VERSION "HNNBNNNYNNNNNNNNNNNNNNNNNNNNNNNNNNNNNNNNNN/4/%%%/4/'%**4NNN///"

NS_ :

BS_:

BU_: BAP_Tester CGS Gateway Gateway_PAG HUD Kombi Kombi_LB Kombi_PAG Waehlhebel_SB

BO_ 974 TSG_HFS_01: 8 Gateway
 SG_ HFS_Tuer_geoeffnet : 0|1@1+ (1.0,0.0) [0.0|1] ""  Vector__XXX
 SG_ HFS_verriegelt : 1|1@1+ (1.0,0.0) [0.0|1] ""  Vector__XXX
 SG_ HFS_gesafet : 2|1@1+ (1.0,0.0) [0.0|1] ""  Vector__XXX
 SG_ HFS_Heckrollotaster_betaetigt : 3|1@1+ (1.0,0.0) [0.0|1] ""  Vector__XXX
 SG_ HFS_Tuerschloss_defekt : 4|1@1+ (1.0,0.0) [0.0|1] ""  Kombi,Kombi_LB,Kombi_PAG
 SG_ HFS_Unlock_Taster : 5|1@1+ (1.0,0.0) [0.0|1] ""  Vector__XXX
 SG_ HFS_Lock_Taster : 6|1@1+ (1.0,0.0) [0.0|1] ""  Vector__XXX
 SG_ HFS_Sperrklinke : 7|1@1+ (1.0,0.0) [0.0|1] ""  Vector__XXX
 SG_ HFS_TAG_betaetigt : 8|1@1+ (1.0,0.0) [0.0|1] ""  Vector__XXX
 SG_ HFS_TIG_betaetigt : 9|1@1+ (1.0,0.0) [0.0|1] ""  Vector__XXX
 SG_ HFS_FH_S_HBFS_AutoHoch : 10|1@1+ (1.0,0.0) [0.0|1] ""  Vector__XXX
 SG_ HFS_FH_S_HBFS_AutoTief : 11|1@1+ (1.0,0.0) [0.0|1] ""  Vector__XXX
 SG_ HFS_FH_S_HBFS_ManHoch : 12|1@1+ (1.0,0.0) [0.0|1] ""  Vector__XXX
 SG_ HFS_FH_S_HBFS_ManTief : 13|1@1+ (1.0,0.0) [0.0|1] ""  Vector__XXX
 SG_ HFS_Tuer_Status : 14|2@1+ (1.0,0.0) [0.0|3] ""  Kombi_PAG
 SG_ HFS_SAD_Schalter : 16|4@1+ (1.0,0.0) [0.0|15] ""  Vector__XXX
 SG_ HFS_FH_S_ManHoch : 20|1@1+ (1.0,0.0) [0.0|1] ""  Vector__XXX
 SG_ HFS_FH_S_AutoHoch : 21|1@1+ (1.0,0.0) [0.0|1] ""  Vector__XXX
 SG_ HFS_FH_S_ManTief : 22|1@1+ (1.0,0.0) [0.0|1] ""  Vector__XXX
 SG_ HFS_FH_S_AutoTief : 23|1@1+ (1.0,0.0) [0.0|1] ""  Vector__XXX
 SG_ HFS_FH_Oeffnung : 24|8@1+ (0.5,0) [0.0|100.0] "Unit_PerCent"  Vector__XXX
 SG_ HFS_FH_Bew_hoch : 32|1@1+ (1.0,0.0) [0.0|1] ""  Vector__XXX
 SG_ HFS_FH_Bew_tief : 33|1@1+ (1.0,0.0) [0.0|1] ""  Vector__XXX
 SG_ HFS_FH_Fang : 34|1@1+ (1.0,0.0) [0.0|1] ""  Vector__XXX
 SG_ HFS_FH_Block : 35|1@1+ (1.0,0.0) [0.0|1] ""  Vector__XXX
 SG_ HFS_FH_Thermo : 36|1@1+ (1.0,0.0) [0.0|1] ""  Vector__XXX
 SG_ HFS_UEKB_aktiviert : 37|1@1+ (1.0,0.0) [0.0|1] ""  Vector__XXX
 SG_ HFS_Tueroeffnen_Warnung : 38|1@1+ (1.0,0.0) [0.0|1] ""  Kombi,Kombi_LB,Kombi_PAG
 SG_ HFS_FH_normiert : 39|1@1+ (1.0,0.0) [0.0|1] ""  Vector__XXX
 SG_ ASW_Warnung_aktiv_HFS : 40|1@1+ (1.0,0.0) [0.0|1] ""  Kombi,Kombi_LB,Kombi_PAG
 SG_ HFS_Zuziehhilfe_aktiv : 41|1@1+ (1.0,0.0) [0.0|1] ""  Vector__XXX
 SG_ HFS_Seitenrollo_hoch : 42|1@1+ (1.0,0.0) [0.0|1] ""  Vector__XXX
 SG_ HFS_Seitenrollo_tief : 43|1@1+ (1.0,0.0) [0.0|1] ""  Vector__XXX
 SG_ HFS_Status_KiSi : 44|1@1+ (1.0,0.0) [0.0|1] ""  Kombi_PAG
 SG_ SSR_HFS_Pos_Unten : 45|1@1+ (1.0,0.0) [0.0|1] ""  Vector__XXX
 SG_ HFS_Oben_Block_erw : 46|1@1+ (1.0,0.0) [0.0|1] ""  Vector__XXX
 SG_ HFS_Unten_Block_erw : 47|1@1+ (1.0,0.0) [0.0|1] ""  Vector__XXX
 SG_ MTHFS_M_Taste : 48|1@1+ (1.0,0.0) [0.0|1] ""  Vector__XXX
 SG_ MTHFS_Pos1 : 49|1@1+ (1.0,0.0) [0.0|1] ""  Vector__XXX
 SG_ MTHFS_Pos2 : 50|1@1+ (1.0,0.0) [0.0|1] ""  Vector__XXX
 SG_ MTHFS_Pos3 : 51|1@1+ (1.0,0.0) [0.0|1] ""  Vector__XXX
 SG_ HFS_MRollo_Schalter : 52|3@1+ (1.0,0.0) [0.0|7] ""  Vector__XXX
 SG_ HFS_Lock_Taster_inv : 55|1@1+ (1.0,0.0) [0.0|1] ""  Vector__XXX
 SG_ HFS_Status_eTAG : 56|2@1+ (1.0,0.0) [0.0|3] ""  Vector__XXX
 SG_ HFS_Tuer_Status_QBit : 58|1@1+ (1.0,0.0) [0.0|1] ""  Vector__XXX
 SG_ HFS_TCR_Mode_aktiv : 59|1@1+ (1.0,0.0) [0.0|1] ""  Kombi_PAG

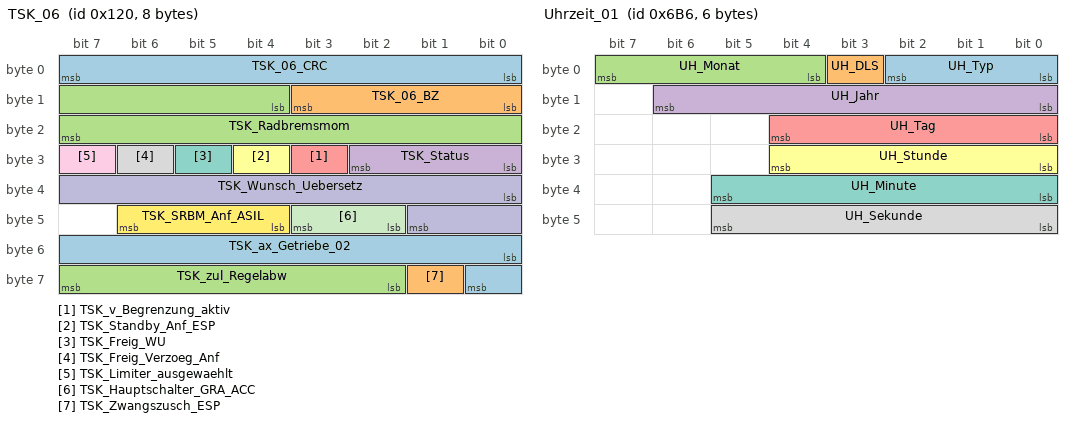
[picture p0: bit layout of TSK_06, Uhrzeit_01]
BO_ 288 TSK_06: 8 Gateway
 SG_ TSK_06_CRC : 0|8@1+ (1,0) [0|255] ""  Vector__XXX
 SG_ TSK_06_BZ : 8|4@1+ (1,0) [0|15] ""  Vector__XXX
 SG_ TSK_Radbremsmom : 12|12@1+ (8,0) [0|32760] "Unit_NewtoMeter"  Vector__XXX
 SG_ TSK_Status : 24|3@1+ (1.0,0.0) [0.0|7] ""  Vector__XXX
 SG_ TSK_v_Begrenzung_aktiv : 27|1@1+ (1.0,0.0) [0.0|1] ""  Vector__XXX
 SG_ TSK_Standby_Anf_ESP : 28|1@1+ (1.0,0.0) [0.0|1] ""  Vector__XXX
 SG_ TSK_Freig_WU : 29|1@1+ (1.0,0.0) [0.0|1] ""  Vector__XXX
 SG_ TSK_Freig_Verzoeg_Anf : 30|1@1+ (1.0,0.0) [0.0|1] ""  Vector__XXX
 SG_ TSK_Limiter_ausgewaehlt : 31|1@1+ (1.0,0.0) [0.0|1] ""  Vector__XXX
 SG_ TSK_Wunsch_Uebersetz : 32|10@1+ (0.0245,0) [0.0245|25.0635] ""  Vector__XXX
 SG_ TSK_Hauptschalter_GRA_ACC : 42|2@1+ (1.0,0.0) [0.0|3] ""  Kombi,Kombi_LB,Kombi_PAG
 SG_ TSK_SRBM_Anf_ASIL : 44|3@1+ (1.0,0.0) [0.0|7] ""  Vector__XXX
 SG_ TSK_ax_Getriebe_02 : 48|9@1+ (0.024,-2.016) [-2.016|10.224] "Unit_MeterPerSeconSquar"  Vector__XXX
 SG_ TSK_Zwangszusch_ESP : 57|1@1+ (1.0,0.0) [0.0|1] ""  Vector__XXX
 SG_ TSK_zul_Regelabw : 58|6@1+ (0.024,0) [0.000|1.512] "Unit_MeterPerSeconSquar"  Vector__XXX

BO_ 798 TSK_07: 8 Gateway
 SG_ TSK_07_CRC : 0|8@1+ (1,0) [0|255] ""  Kombi,Kombi_LB,Kombi_PAG
 SG_ TSK_07_BZ : 8|4@1+ (1,0) [0|15] ""  Kombi,Kombi_LB,Kombi_PAG
 SG_ TSK_Wunschgeschw : 12|10@1+ (0.32,0) [0.00|326.72] "Unit_KiloMeterPerHour"  HUD,Kombi,Kombi_LB,Kombi_PAG
 SG_ TSK_praediktiver_Hinweis : 22|3@1+ (1.0,0.0) [0.0|7] ""  HUD,Kombi,Kombi_PAG
 SG_ TSK_naechstes_Event : 25|6@1+ (1.0,0.0) [0.0|63] ""  HUD,Kombi,Kombi_PAG
 SG_ TSK_Fahrzeugstatus_praed_Fkt : 31|3@1+ (1.0,0.0) [0.0|7] ""  HUD,Kombi,Kombi_PAG
 SG_ TSK_praediktiver_Automode : 34|1@1+ (1.0,0.0) [0.0|1] ""  HUD,Kombi,Kombi_PAG
 SG_ TSK_Texte : 40|5@1+ (1.0,0.0) [0.0|31] ""  Kombi,Kombi_LB,Kombi_PAG
 SG_ TSK_Akustik : 45|3@1+ (1.0,0.0) [0.0|7] ""  Kombi,Kombi_LB,Kombi_PAG
 SG_ TSK_Texte_Primaeranz : 48|5@1+ (1.0,0.0) [0.0|31] ""  HUD,Kombi,Kombi_LB,Kombi_PAG
 SG_ TSK_Limiter_Fahrerinfo : 53|2@1+ (1.0,0.0) [0.0|3] ""  HUD,Kombi,Kombi_LB,Kombi_PAG
 SG_ TSK_Limiter_Anzeige : 55|1@1+ (1.0,0.0) [0.0|1] ""  HUD,Kombi,Kombi_LB,Kombi_PAG
 SG_ TSK_Fahrzeugstatus_GRA : 56|1@1+ (1.0,0.0) [0.0|1] ""  Kombi,Kombi_LB,Kombi_PAG
 SG_ TSK_Fahrzeugstatus_Limiter : 57|1@1+ (1.0,0.0) [0.0|1] ""  Kombi,Kombi_LB,Kombi_PAG
 SG_ MO_Motorlaufwarnung : 58|1@1+ (1.0,0.0) [0.0|1] ""  Kombi,Kombi_LB,Kombi_PAG
 SG_ MO_Verlassenswarnung : 59|1@1+ (1.0,0.0) [0.0|1] ""  Kombi,Kombi_LB,Kombi_PAG
 SG_ TSK_naechstes_Event_Einheit : 60|1@1+ (1.0,0.0) [0.0|1] ""  Kombi,Kombi_PAG
 SG_ TSK_Status_Anzeige : 61|3@1+ (1.0,0.0) [0.0|7] ""  HUD,Kombi,Kombi_LB,Kombi_PAG

BO_ 563 TSK_10: 8 Gateway
 SG_ TSK_praed_Wunschgeschw : 54|10@1+ (0.32,0) [0.00|326.72] "Unit_KiloMeterPerHour"  HUD,Kombi,Kombi_PAG

BO_ 1718 Uhrzeit_01: 6 Kombi
 SG_ UH_Typ : 0|3@1+ (1.0,0.0) [0.0|7] ""  Gateway,Gateway_PAG
 SG_ UH_DLS : 3|1@1+ (1.0,0.0) [0.0|1] ""  Gateway,Gateway_PAG
 SG_ UH_Monat : 4|4@1+ (1,0) [1|12] "Unit_Month"  Gateway,Gateway_PAG
 SG_ UH_Jahr : 8|7@1+ (1,2000) [2000|2127] "Unit_Year"  Gateway,Gateway_PAG
 SG_ UH_Tag : 16|5@1+ (1,0) [1|31] "Unit_Day"  Gateway,Gateway_PAG
 SG_ UH_Stunde : 24|5@1+ (1,0) [0|23] "Unit_Hours"  Gateway,Gateway_PAG
 SG_ UH_Minute : 32|6@1+ (1,0) [0|59] "Unit_Minut"  Gateway,Gateway_PAG
 SG_ UH_Sekunde : 40|6@1+ (1,0) [0|59] "Unit_Secon"  Gateway,Gateway_PAG

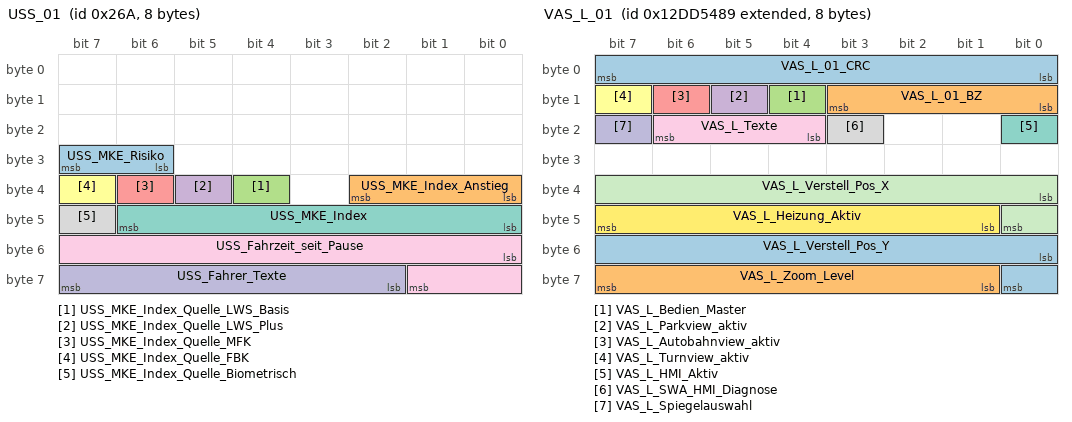
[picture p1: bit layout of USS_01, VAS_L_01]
BO_ 618 USS_01: 8 Gateway
 SG_ USS_MKE_Risiko : 30|2@1+ (1.0,0.0) [0.0|3] ""  Vector__XXX
 SG_ USS_MKE_Index_Anstieg : 32|3@1+ (1.0,0.0) [0.0|7] ""  Vector__XXX
 SG_ USS_MKE_Index_Quelle_LWS_Basis : 36|1@1+ (1.0,0.0) [0.0|1] ""  Vector__XXX
 SG_ USS_MKE_Index_Quelle_LWS_Plus : 37|1@1+ (1.0,0.0) [0.0|1] ""  Vector__XXX
 SG_ USS_MKE_Index_Quelle_MFK : 38|1@1+ (1.0,0.0) [0.0|1] ""  Vector__XXX
 SG_ USS_MKE_Index_Quelle_FBK : 39|1@1+ (1.0,0.0) [0.0|1] ""  Vector__XXX
 SG_ USS_MKE_Index : 40|7@1+ (0.1,0) [0.0|10.0] ""  Vector__XXX
 SG_ USS_MKE_Index_Quelle_Biometrisch : 47|1@1+ (1.0,0.0) [0.0|1] ""  Vector__XXX
 SG_ USS_Fahrzeit_seit_Pause : 48|10@1+ (1,0) [0|1020] "Unit_Minut"  Vector__XXX
 SG_ USS_Fahrer_Texte : 58|6@1+ (1.0,0.0) [0.0|63] ""  Kombi,Kombi_LB

BO_ 2463978633 VAS_L_01: 8 Gateway
 SG_ VAS_L_01_CRC : 0|8@1+ (1,0) [0|255] ""  Kombi,Kombi_LB
 SG_ VAS_L_01_BZ : 8|4@1+ (1,0) [0|15] ""  Kombi,Kombi_LB
 SG_ VAS_L_Bedien_Master : 12|1@1+ (1.0,0.0) [0.0|1] ""  Vector__XXX
 SG_ VAS_L_Parkview_aktiv : 13|1@1+ (1.0,0.0) [0.0|1] ""  Vector__XXX
 SG_ VAS_L_Autobahnview_aktiv : 14|1@1+ (1.0,0.0) [0.0|1] ""  Vector__XXX
 SG_ VAS_L_Turnview_aktiv : 15|1@1+ (1.0,0.0) [0.0|1] ""  Vector__XXX
 SG_ VAS_L_HMI_Aktiv : 16|1@1+ (1.0,0.0) [0.0|1] ""  Vector__XXX
 SG_ VAS_L_SWA_HMI_Diagnose : 19|1@1+ (1.0,0.0) [0.0|1] ""  Vector__XXX
 SG_ VAS_L_Texte : 20|3@1+ (1.0,0.0) [0.0|7] ""  Kombi
 SG_ VAS_L_Spiegelauswahl : 23|1@1+ (1.0,0.0) [0.0|1] ""  Vector__XXX
 SG_ VAS_L_Verstell_Pos_X : 32|9@1+ (1,0) [0|400] "Unit_None"  Vector__XXX
 SG_ VAS_L_Heizung_Aktiv : 41|7@1+ (1,0) [0|100] "Unit_PerCent"  Vector__XXX
 SG_ VAS_L_Verstell_Pos_Y : 48|9@1+ (1,0) [0|400] "Unit_None"  Vector__XXX
 SG_ VAS_L_Zoom_Level : 57|7@1+ (1,0) [0|100] "Unit_PerCent"  Vector__XXX

BO_ 995 Verdeck_01: 8 Gateway
 SG_ Verdeck_01_CRC : 0|8@1+ (1,0) [0|255] ""  Vector__XXX
 SG_ Verdeck_01_BZ : 8|4@1+ (1,0) [0|15] ""  Vector__XXX
 SG_ VS_VD_zu_ver : 16|1@1+ (1.0,0.0) [0.0|1] ""  Kombi,Kombi_PAG
 SG_ VS_VD_entriegelt : 17|1@1+ (1.0,0.0) [0.0|1] ""  Vector__XXX
 SG_ VS_VD_offen_ver : 18|1@1+ (1.0,0.0) [0.0|1] ""  Kombi
 SG_ VS_VD_Zwischenposition : 19|1@1+ (1.0,0.0) [0.0|1] ""  Vector__XXX
 SG_ VS_VD_Bew_auf : 20|1@1+ (1.0,0.0) [0.0|1] ""  Vector__XXX
 SG_ VS_VD_Bew_zu : 21|1@1+ (1.0,0.0) [0.0|1] ""  Vector__XXX
 SG_ VS_Verdeck_Anf : 22|1@1+ (1.0,0.0) [0.0|1] ""  Vector__XXX
 SG_ VS_Hardtop : 23|1@1+ (1.0,0.0) [0.0|1] ""  Vector__XXX
 SG_ VS_VD_Fehler : 24|1@1+ (1.0,0.0) [0.0|1] ""  Vector__XXX
 SG_ VS_Lampe_Blk : 25|1@1+ (1.0,0.0) [0.0|1] ""  Kombi
 SG_ VS_Buzzer : 26|1@1+ (1.0,0.0) [0.0|1] ""  Kombi
 SG_ VS_HD_sperren : 27|1@1+ (1.0,0.0) [0.0|1] ""  Vector__XXX
 SG_ VS_HHS_enable : 28|1@1+ (1.0,0.0) [0.0|1] ""  Vector__XXX
 SG_ VD_SpannungsAnf : 29|2@1+ (1.0,0.0) [0.0|3] ""  Vector__XXX
 SG_ VS_VDKD_auf : 31|1@1+ (1.0,0.0) [0.0|1] ""  Vector__XXX
 SG_ VS_FS_AutoHoch : 32|1@1+ (1.0,0.0) [0.0|1] ""  Vector__XXX
 SG_ VS_FS_AutoTief : 33|1@1+ (1.0,0.0) [0.0|1] ""  Vector__XXX
 SG_ VS_FS_ManHoch : 34|1@1+ (1.0,0.0) [0.0|1] ""  Vector__XXX
 SG_ VS_FS_ManTief : 35|1@1+ (1.0,0.0) [0.0|1] ""  Vector__XXX
 SG_ VS_BFS_AutoHoch : 36|1@1+ (1.0,0.0) [0.0|1] ""  Vector__XXX
 SG_ VS_BFS_AutoTief : 37|1@1+ (1.0,0.0) [0.0|1] ""  Vector__XXX
 SG_ VS_BFS_ManHoch : 38|1@1+ (1.0,0.0) [0.0|1] ""  Vector__XXX
 SG_ VS_BFS_ManTief : 39|1@1+ (1.0,0.0) [0.0|1] ""  Vector__XXX
 SG_ VS_HFS_AutoHoch : 40|1@1+ (1.0,0.0) [0.0|1] ""  Vector__XXX
 SG_ VS_HFS_AutoTief : 41|1@1+ (1.0,0.0) [0.0|1] ""  Vector__XXX
 SG_ VS_HFS_ManHoch : 42|1@1+ (1.0,0.0) [0.0|1] ""  Vector__XXX
 SG_ VS_HFS_ManTief : 43|1@1+ (1.0,0.0) [0.0|1] ""  Vector__XXX
 SG_ VS_HBFS_AutoHoch : 44|1@1+ (1.0,0.0) [0.0|1] ""  Vector__XXX
 SG_ VS_HBFS_AutoTief : 45|1@1+ (1.0,0.0) [0.0|1] ""  Vector__XXX
 SG_ VS_HBFS_ManHoch : 46|1@1+ (1.0,0.0) [0.0|1] ""  Vector__XXX
 SG_ VS_HBFS_ManTief : 47|1@1+ (1.0,0.0) [0.0|1] ""  Vector__XXX
 SG_ VS_FH_FT_Langhub : 49|1@1+ (1.0,0.0) [0.0|1] ""  Vector__XXX
 SG_ VS_Windschott_nicht_abgelegt : 50|1@1+ (1.0,0.0) [0.0|1] ""  Vector__XXX
 SG_ VS_FH_BT_Langhub : 51|1@1+ (1.0,0.0) [0.0|1] ""  Vector__XXX
 SG_ VS_FH_HFS_Langhub : 53|1@1+ (1.0,0.0) [0.0|1] ""  Vector__XXX
 SG_ VS_Heckschloss_auf : 54|1@1+ (1.0,0.0) [0.0|1] ""  Vector__XXX
 SG_ VS_FH_HBFS_Langhub : 55|1@1+ (1.0,0.0) [0.0|1] ""  Vector__XXX
 SG_ VSG_Meldungen : 56|6@1+ (1,0) [1|63] "Unit_None"  Kombi,Kombi_PAG
 SG_ VS_StartStopp_Info : 62|2@1+ (1.0,0.0) [0.0|3] ""  Vector__XXX

BO_ 1716 VIN_01: 8 Gateway
 SG_ VIN_01_MUX M  : 0|2@1+ (1,0) [0|3] ""  Kombi,Kombi_LB,Kombi_PAG
 SG_ KS_Geheimnis_1 m0  : 8|8@1+ (1,0) [0|255] ""  Vector__XXX
 SG_ VIN_4 m1  : 8|8@1+ (1,0) [0|255] ""  Kombi,Kombi_PAG
 SG_ VIN_11 m2  : 8|8@1+ (1,0) [0|255] ""  Kombi,Kombi_PAG
 SG_ KS_Geheimnis_2 m0  : 16|8@1+ (1,0) [0|255] ""  Vector__XXX
 SG_ VIN_5 m1  : 16|8@1+ (1,0) [0|255] ""  Kombi,Kombi_PAG
 SG_ VIN_12 m2  : 16|8@1+ (1,0) [0|255] ""  Kombi,Kombi_PAG
 SG_ KS_Geheimnis_3 m0  : 24|8@1+ (1,0) [0|255] ""  Vector__XXX
 SG_ VIN_6 m1  : 24|8@1+ (1,0) [0|255] ""  Kombi,Kombi_PAG
 SG_ VIN_13 m2  : 24|8@1+ (1,0) [0|255] ""  Kombi,Kombi_PAG
 SG_ KS_Geheimnis_4 m0  : 32|8@1+ (1,0) [0|255] ""  Vector__XXX
 SG_ VIN_7 m1  : 32|8@1+ (1,0) [0|255] ""  Kombi,Kombi_PAG
 SG_ VIN_14 m2  : 32|8@1+ (1,0) [0|255] ""  Kombi,Kombi_PAG
 SG_ VIN_1 m0  : 40|8@1+ (1,0) [0|255] ""  Kombi,Kombi_LB,Kombi_PAG
 SG_ VIN_8 m1  : 40|8@1+ (1,0) [0|255] ""  Kombi,Kombi_PAG
 SG_ VIN_15 m2  : 40|8@1+ (1,0) [0|255] ""  Kombi,Kombi_PAG
 SG_ VIN_2 m0  : 48|8@1+ (1,0) [0|255] ""  Kombi,Kombi_LB,Kombi_PAG
 SG_ VIN_9 m1  : 48|8@1+ (1,0) [0|255] ""  Kombi,Kombi_PAG
 SG_ VIN_16 m2  : 48|8@1+ (1,0) [0|255] ""  Kombi,Kombi_PAG
 SG_ VIN_3 m0  : 56|8@1+ (1,0) [0|255] ""  Kombi,Kombi_LB,Kombi_PAG
 SG_ VIN_10 m1  : 56|8@1+ (1,0) [0|255] ""  Kombi,Kombi_PAG
 SG_ VIN_17 m2  : 56|8@1+ (1,0) [0|255] ""  Kombi,Kombi_PAG

BO_ 385 VZE_01: 8 Gateway
 SG_ VZE_Anzeigemodus : 0|2@1+ (1.0,0.0) [0.0|3] ""  HUD,Kombi,Kombi_LB,Kombi_PAG
 SG_ VZE_Hinweistext : 2|3@1+ (1,0) [1|7] ""  Kombi,Kombi_LB,Kombi_PAG
 SG_ VZE_Akustik_Limitwechsel : 5|1@1+ (1.0,0.0) [0.0|1] ""  Kombi,Kombi_LB,Kombi_PAG
 SG_ VZE_Modus_OptischeWarnung : 6|1@1+ (1.0,0.0) [0.0|1] ""  HUD,Kombi,Kombi_LB,Kombi_PAG
 SG_ VZE_Verkehrszeichen_Einheit : 8|1@1+ (1.0,0.0) [0.0|1] ""  HUD,Kombi_PAG
 SG_ VZE_Anzeigeunterdrueck_Zeichen_3 : 9|1@1+ (1.0,0.0) [0.0|1] ""  HUD,Kombi,Kombi_LB
 SG_ VZE_Anzeigeunterdrueck_Zeichen_2 : 10|1@1+ (1.0,0.0) [0.0|1] ""  HUD,Kombi,Kombi_LB
 SG_ VZE_Verkehrszeichen_1 : 11|8@1+ (1,0) [1|255] ""  HUD,Kombi,Kombi_LB,Kombi_PAG
 SG_ VZE_Verkehrszeichen_2 : 19|8@1+ (1,0) [1|255] ""  HUD,Kombi,Kombi_LB,Kombi_PAG
 SG_ VZE_Verkehrszeichen_3 : 27|8@1+ (1,0) [1|255] ""  HUD,Kombi,Kombi_LB,Kombi_PAG
 SG_ VZE_Warnung_Verkehrszeichen_1 : 35|1@1+ (1.0,0.0) [0.0|1] ""  HUD,Kombi,Kombi_LB,Kombi_PAG
 SG_ VZE_Warnung_Verkehrszeichen_2 : 36|1@1+ (1.0,0.0) [0.0|1] ""  HUD,Kombi,Kombi_LB,Kombi_PAG
 SG_ VZE_Warnung_Verkehrszeichen_3 : 37|1@1+ (1.0,0.0) [0.0|1] ""  HUD,Kombi,Kombi_LB,Kombi_PAG
 SG_ VZE_Zusatzschild_1 : 38|4@1+ (1,0) [1|15] ""  HUD,Kombi,Kombi_LB,Kombi_PAG
 SG_ VZE_Zusatzschild_2 : 42|4@1+ (1,0) [1|15] ""  HUD,Kombi,Kombi_LB,Kombi_PAG
 SG_ VZE_Zusatzschild_3 : 46|4@1+ (1,0) [1|15] ""  HUD,Kombi,Kombi_LB,Kombi_PAG
 SG_ VZE_Anzeigeunterdrueck_Zeichen_1 : 50|1@1+ (1.0,0.0) [0.0|1] ""  HUD,Kombi,Kombi_LB,Kombi_PAG
 SG_ VZE_Zeichen_01_KameraWied : 51|1@1+ (1.0,0.0) [0.0|1] ""  Vector__XXX
 SG_ VZE_Zeichen_02_KameraWied : 52|1@1+ (1.0,0.0) [0.0|1] ""  Vector__XXX
 SG_ VZE_Zeichen_03_KameraWied : 53|1@1+ (1.0,0.0) [0.0|1] ""  Vector__XXX
 SG_ VZE_Zeichen_01_Kamera : 54|1@1+ (1.0,0.0) [0.0|1] ""  Vector__XXX
 SG_ VZE_Zeichen_01_Karte : 55|1@1+ (1.0,0.0) [0.0|1] ""  Vector__XXX
 SG_ VZE_Zeichen_01_Gesetz : 56|1@1+ (1.0,0.0) [0.0|1] ""  Vector__XXX
 SG_ VZE_Zeichen_02_Kamera : 57|1@1+ (1.0,0.0) [0.0|1] ""  Vector__XXX
 SG_ VZE_Zeichen_02_Karte : 58|1@1+ (1.0,0.0) [0.0|1] ""  Vector__XXX
 SG_ VZE_Zeichen_02_Gesetz : 59|1@1+ (1.0,0.0) [0.0|1] ""  Vector__XXX
 SG_ VZE_Zeichen_03_Kamera : 60|1@1+ (1.0,0.0) [0.0|1] ""  Vector__XXX
 SG_ VZE_Zeichen_03_Karte : 61|1@1+ (1.0,0.0) [0.0|1] ""  Vector__XXX
 SG_ VZE_Zeichen_03_Gesetz : 62|1@1+ (1.0,0.0) [0.0|1] ""  Vector__XXX
 SG_ VZE_Gong : 63|1@1+ (1.0,0.0) [0.0|1] ""  Kombi,Kombi_LB,Kombi_PAG

BO_ 668 VZE_02: 8 Gateway
 SG_ VZE_Akustik_Limitwechsel_Status : 5|1@1+ (1.0,0.0) [0.0|1] ""  Vector__XXX
 SG_ VZE_SLWF_Status : 6|2@1+ (1.0,0.0) [0.0|3] ""  Kombi,Kombi_LB,Kombi_PAG
 SG_ VZE_Anzeigeunterdrueck_Zeichen_5 : 8|1@1+ (1.0,0.0) [0.0|1] ""  HUD,Kombi,Kombi_LB
 SG_ VZE_Zeichen_05_KameraWied : 9|1@1+ (1.0,0.0) [0.0|1] ""  Vector__XXX
 SG_ VZE_Zeichen_05_Kamera : 10|1@1+ (1.0,0.0) [0.0|1] ""  Vector__XXX
 SG_ VZE_Verkehrszeichen_4 : 11|8@1+ (1,0) [1|255] ""  HUD,Kombi,Kombi_LB,Kombi_PAG
 SG_ VZE_Verkehrszeichen_5 : 19|8@1+ (1,0) [1|255] ""  HUD,Kombi,Kombi_LB,Kombi_PAG
 SG_ VZE_Anhaenger_Vmax : 27|4@1+ (10,10) [10|140] "Unit_KiloMeterPerHour"  Vector__XXX
 SG_ VZE_Zeichen_04_Gesetz : 31|1@1+ (1.0,0.0) [0.0|1] ""  Vector__XXX
 SG_ VZE_Zeichen_04_Kamera : 32|1@1+ (1.0,0.0) [0.0|1] ""  Vector__XXX
 SG_ VZE_Zeichen_04_KameraWied : 33|1@1+ (1.0,0.0) [0.0|1] ""  Vector__XXX
 SG_ VZE_Zeichen_04_Karte : 34|1@1+ (1.0,0.0) [0.0|1] ""  Vector__XXX
 SG_ VZE_Warnung_Verkehrszeichen_4 : 35|1@1+ (1.0,0.0) [0.0|1] ""  HUD,Kombi,Kombi_LB,Kombi_PAG
 SG_ VZE_Warnung_Verkehrszeichen_5 : 36|1@1+ (1.0,0.0) [0.0|1] ""  HUD,Kombi,Kombi_LB,Kombi_PAG
 SG_ VZE_Zeichen_05_Gesetz : 37|1@1+ (1.0,0.0) [0.0|1] ""  Vector__XXX
 SG_ VZE_Zusatzschild_4 : 38|4@1+ (1,0) [1|15] ""  HUD,Kombi,Kombi_LB,Kombi_PAG
 SG_ VZE_Zusatzschild_5 : 42|4@1+ (1,0) [1|15] ""  HUD,Kombi,Kombi_LB,Kombi_PAG
 SG_ VZE_Baustelle : 46|2@1+ (1.0,0.0) [0.0|3] ""  Vector__XXX
 SG_ VZE_Zeichen_05_Karte : 48|1@1+ (1.0,0.0) [0.0|1] ""  Vector__XXX
 SG_ VZE_Zeichen_05_Entfernung : 49|7@1+ (1,0) [1|127] "Unit_Meter"  Vector__XXX
 SG_ VZE_Zeichen_05_Entfernung_StdA : 56|7@1+ (1,0) [1|127] "Unit_Meter"  Vector__XXX
 SG_ VZE_Anzeigeunterdrueck_Zeichen_4 : 63|1@1+ (1.0,0.0) [0.0|1] ""  HUD,Kombi,Kombi_LB

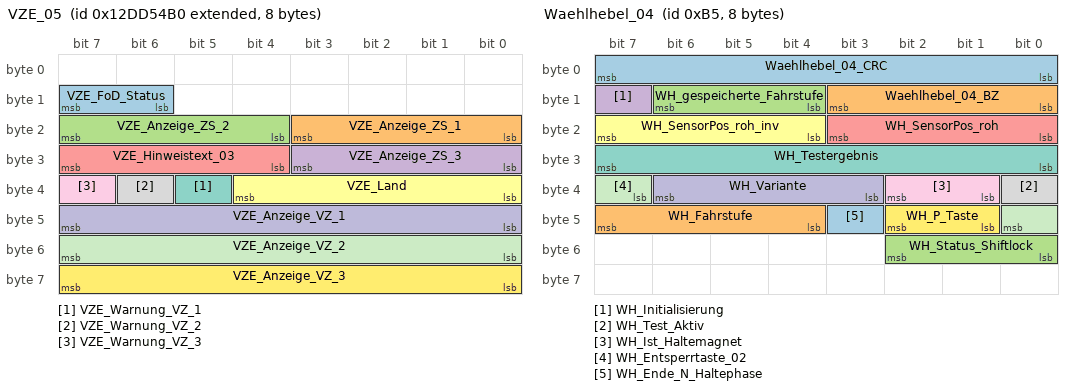
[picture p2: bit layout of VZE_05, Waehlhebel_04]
BO_ 2463978672 VZE_05: 8 Gateway
 SG_ VZE_FoD_Status : 14|2@1+ (1.0,0.0) [0.0|3] ""  HUD,Kombi,Kombi_LB,Kombi_PAG
 SG_ VZE_Anzeige_ZS_1 : 16|4@1+ (1,0) [1|15] "Unit_None"  HUD,Kombi,Kombi_LB,Kombi_PAG
 SG_ VZE_Anzeige_ZS_2 : 20|4@1+ (1,0) [1|15] "Unit_None"  HUD,Kombi,Kombi_LB,Kombi_PAG
 SG_ VZE_Anzeige_ZS_3 : 24|4@1+ (1,0) [1|15] "Unit_None"  HUD,Kombi,Kombi_LB,Kombi_PAG
 SG_ VZE_Hinweistext_03 : 28|4@1+ (1,0) [1|15] ""  HUD,Kombi,Kombi_LB,Kombi_PAG
 SG_ VZE_Land : 32|5@1+ (1,0) [1|31] ""  HUD,Kombi,Kombi_LB,Kombi_PAG
 SG_ VZE_Warnung_VZ_1 : 37|1@1+ (1.0,0.0) [0.0|1] ""  HUD,Kombi,Kombi_LB,Kombi_PAG
 SG_ VZE_Warnung_VZ_2 : 38|1@1+ (1.0,0.0) [0.0|1] ""  HUD,Kombi,Kombi_LB,Kombi_PAG
 SG_ VZE_Warnung_VZ_3 : 39|1@1+ (1.0,0.0) [0.0|1] ""  HUD,Kombi,Kombi_LB,Kombi_PAG
 SG_ VZE_Anzeige_VZ_1 : 40|8@1+ (1,0) [1|255] ""  HUD,Kombi,Kombi_LB,Kombi_PAG
 SG_ VZE_Anzeige_VZ_2 : 48|8@1+ (1,0) [1|255] "Unit_None"  HUD,Kombi,Kombi_LB,Kombi_PAG
 SG_ VZE_Anzeige_VZ_3 : 56|8@1+ (1,0) [1|255] "Unit_None"  HUD,Kombi,Kombi_LB,Kombi_PAG

BO_ 181 Waehlhebel_04: 8 CGS
 SG_ Waehlhebel_04_CRC : 0|8@1+ (1,0) [0|255] ""  Gateway,Gateway_PAG
 SG_ Waehlhebel_04_BZ : 8|4@1+ (1,0) [0|15] ""  Gateway,Gateway_PAG
 SG_ WH_gespeicherte_Fahrstufe : 12|3@1+ (1.0,0.0) [0.0|7] ""  Gateway,Gateway_PAG,Kombi_PAG
 SG_ WH_Initialisierung : 15|1@1+ (1.0,0.0) [0.0|1] ""  Gateway,Gateway_PAG,Kombi_PAG
 SG_ WH_SensorPos_roh : 16|4@1+ (1.0,0.0) [0.0|15] ""  Gateway,Gateway_PAG,Kombi_PAG
 SG_ WH_SensorPos_roh_inv : 20|4@1+ (1.0,0.0) [0.0|15] ""  Gateway,Gateway_PAG,Kombi_PAG
 SG_ WH_Testergebnis : 24|8@1+ (1,0) [0|255] ""  Gateway,Gateway_PAG
 SG_ WH_Test_Aktiv : 32|1@1+ (1.0,0.0) [0.0|1] ""  Gateway,Gateway_PAG
 SG_ WH_Ist_Haltemagnet : 33|2@1+ (1.0,0.0) [0.0|3] ""  Gateway,Gateway_PAG
 SG_ WH_Variante : 35|4@1+ (1.0,0.0) [0.0|15] ""  Gateway,Gateway_PAG,Kombi,Kombi_LB,Kombi_PAG
 SG_ WH_Entsperrtaste_02 : 39|2@1+ (1.0,0.0) [0.0|3] ""  Gateway,Gateway_PAG
 SG_ WH_P_Taste : 41|2@1+ (1.0,0.0) [0.0|3] ""  Gateway,Gateway_PAG
 SG_ WH_Ende_N_Haltephase : 43|1@1+ (1.0,0.0) [0.0|1] ""  Gateway,Gateway_PAG
 SG_ WH_Fahrstufe : 44|4@1+ (1.0,0.0) [0.0|15] ""  Gateway,Gateway_PAG
 SG_ WH_Status_Shiftlock : 48|3@1+ (1.0,0.0) [0.0|7] ""  Gateway,Gateway_PAG

BO_ 2589283476 Waehlhebel_05: 8 CGS
 SG_ WH_Warnung_02 : 12|3@1+ (1.0,0.0) [0.0|7] ""  Kombi,Kombi_LB,Kombi_PAG
 SG_ WH_Warnung_03 : 15|3@1+ (1.0,0.0) [0.0|7] ""  Kombi,Kombi_LB

BO_ 916 WBA_03: 8 Gateway
 SG_ WBA_03_CRC : 0|8@1+ (1,0) [0|255] ""  Kombi,Kombi_LB,Kombi_PAG
 SG_ WBA_03_BZ : 8|4@1+ (1,0) [0|15] ""  Kombi,Kombi_LB,Kombi_PAG
 SG_ WBA_Fahrstufe_02 : 12|4@1+ (1.0,0.0) [0.0|15] ""  HUD,Kombi,Kombi_LB,Kombi_PAG
 SG_ WBA_ZielFahrstufe : 16|4@1+ (1.0,0.0) [0.0|15] ""  Vector__XXX
 SG_ WBA_GE_Warnung_02 : 20|4@1+ (1.0,0.0) [0.0|15] ""  Kombi,Kombi_LB,Kombi_PAG
 SG_ WBA_eing_Gang_02 : 24|4@1+ (1.0,0.0) [0.0|15] ""  HUD,Kombi,Kombi_LB,Kombi_PAG
 SG_ WBA_GE_Texte : 28|3@1+ (1.0,0.0) [0.0|7] ""  Kombi,Kombi_LB,Kombi_PAG
 SG_ WBA_Segeln_aktiv : 31|1@1+ (1.0,0.0) [0.0|1] ""  Kombi,Kombi_LB,Kombi_PAG
 SG_ WBA_Schaltschema : 32|5@1+ (1.0,0.0) [0.0|31] ""  Vector__XXX
 SG_ WBA_GE_Zusatzwarnungen : 37|3@1+ (1.0,0.0) [0.0|7] ""  Kombi,Kombi_LB,Kombi_PAG
 SG_ GE_Sollgang : 40|4@1+ (1.0,0.0) [0.0|15] ""  Kombi,Kombi_LB,Kombi_PAG
 SG_ GE_Tipschaltempf_verfuegbar : 44|1@1+ (1.0,0.0) [0.0|1] ""  Kombi,Kombi_LB,Kombi_PAG
 SG_ WBA_GE_Texte_02 : 45|3@1+ (1.0,0.0) [0.0|7] ""  HUD,Kombi,Kombi_LB,Kombi_PAG
 SG_ WBA_GE_Texte_03 : 48|4@1+ (1.0,0.0) [0.0|15] ""  Vector__XXX
 SG_ WBA_Blinken : 54|1@1+ (1.0,0.0) [0.0|1] ""  HUD,Kombi,Kombi_LB,Kombi_PAG
 SG_ GE_Wiederstart_Anz_Std : 55|1@1+ (1.0,0.0) [0.0|1] ""  Vector__XXX
 SG_ GE_Stoppverbot_Anz_01 : 56|1@1+ (1.0,0.0) [0.0|1] ""  Vector__XXX
 SG_ GE_Stoppverbot_Anz_02 : 57|1@1+ (1.0,0.0) [0.0|1] ""  Vector__XXX
 SG_ GE_Stoppverbot_Anz_03 : 58|1@1+ (1.0,0.0) [0.0|1] ""  Vector__XXX
 SG_ GE_Stoppverbot_Anz_04 : 59|1@1+ (1.0,0.0) [0.0|1] ""  Vector__XXX
 SG_ GE_Stoppverbot_Anz_05 : 60|1@1+ (1.0,0.0) [0.0|1] ""  Vector__XXX
 SG_ GE_Stoppverbot_Anz_06 : 61|1@1+ (1.0,0.0) [0.0|1] ""  Vector__XXX
 SG_ GE_Stoppverbot_Anz_07 : 62|1@1+ (1.0,0.0) [0.0|1] ""  Vector__XXX
 SG_ GE_Stoppverbot_Anz_Std : 63|1@1+ (1.0,0.0) [0.0|1] ""  Vector__XXX

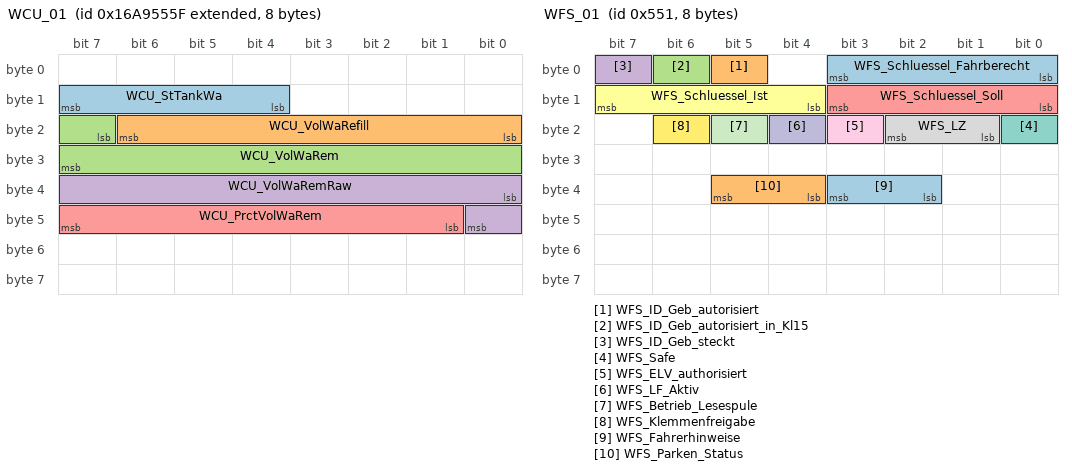
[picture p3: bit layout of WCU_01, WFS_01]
BO_ 2527679839 WCU_01: 8 Gateway
 SG_ WCU_StTankWa : 12|4@1+ (1.0,0.0) [0.0|15] ""  Kombi,Kombi_PAG
 SG_ WCU_VolWaRefill : 16|7@1+ (0.25,0) [0.00|31.25] "Unit_Liter"  Kombi,Kombi_PAG
 SG_ WCU_VolWaRem : 23|9@1+ (0.1,-1) [-1.0|49.9] "Unit_Liter"  Kombi,Kombi_PAG
 SG_ WCU_VolWaRemRaw : 32|9@1+ (0.1,0) [0.0|50.9] "Unit_Liter"  Kombi
 SG_ WCU_PrctVolWaRem : 41|7@1+ (1,0) [0|125] "Unit_PerCent"  Kombi,Kombi_PAG

BO_ 1361 WFS_01: 8 Gateway
 SG_ WFS_Schluessel_Fahrberecht : 0|4@1+ (1.0,0.0) [0.0|15] ""  Vector__XXX
 SG_ WFS_ID_Geb_autorisiert : 5|1@1+ (1.0,0.0) [0.0|1] ""  Vector__XXX
 SG_ WFS_ID_Geb_autorisiert_in_Kl15 : 6|1@1+ (1.0,0.0) [0.0|1] ""  Vector__XXX
 SG_ WFS_ID_Geb_steckt : 7|1@1+ (1.0,0.0) [0.0|1] ""  Vector__XXX
 SG_ WFS_Schluessel_Soll : 8|4@1+ (1,0) [0|8] "Unit_None"  Kombi,Kombi_LB,Kombi_PAG
 SG_ WFS_Schluessel_Ist : 12|4@1+ (1,0) [0|8] "Unit_None"  Kombi,Kombi_LB,Kombi_PAG
 SG_ WFS_Safe : 16|1@1+ (1.0,0.0) [0.0|1] ""  Kombi,Kombi_LB,Kombi_PAG
 SG_ WFS_LZ : 17|2@1+ (1.0,0.0) [0.0|3] ""  Kombi,Kombi_LB,Kombi_PAG
 SG_ WFS_ELV_authorisiert : 19|1@1+ (1.0,0.0) [0.0|1] ""  Vector__XXX
 SG_ WFS_LF_Aktiv : 20|1@1+ (1.0,0.0) [0.0|1] ""  Vector__XXX
 SG_ WFS_Betrieb_Lesespule : 21|1@1+ (1.0,0.0) [0.0|1] ""  Vector__XXX
 SG_ WFS_Klemmenfreigabe : 22|1@1+ (1.0,0.0) [0.0|1] ""  Vector__XXX
 SG_ WFS_Fahrerhinweise : 34|2@1+ (1.0,0.0) [0.0|3] ""  Kombi,Kombi_LB,Kombi_PAG
 SG_ WFS_Parken_Status : 36|2@1+ (1.0,0.0) [0.0|3] ""  Vector__XXX

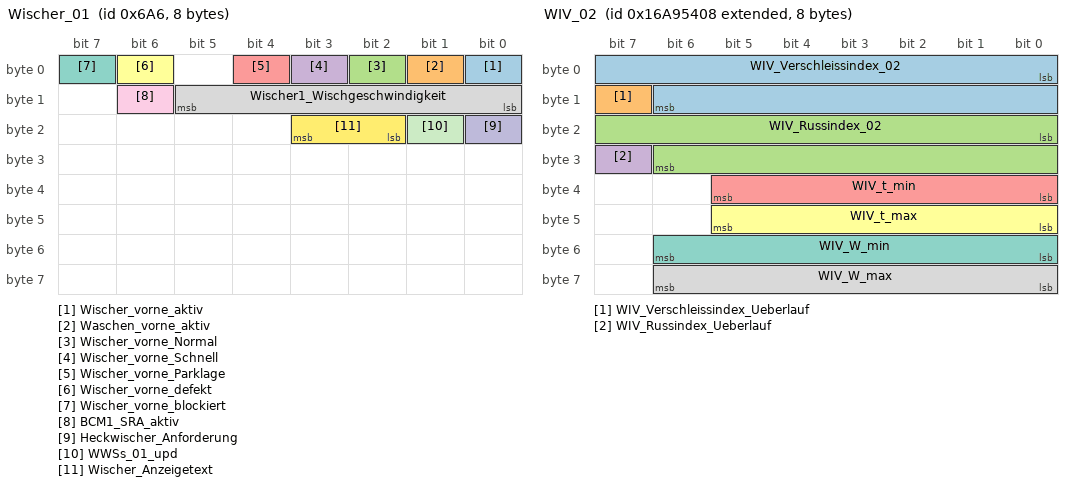
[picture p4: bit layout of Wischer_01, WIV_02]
BO_ 1702 Wischer_01: 8 Gateway
 SG_ Wischer_vorne_aktiv : 0|1@1+ (1.0,0.0) [0.0|1] ""  Vector__XXX
 SG_ Waschen_vorne_aktiv : 1|1@1+ (1.0,0.0) [0.0|1] ""  Vector__XXX
 SG_ Wischer_vorne_Normal : 2|1@1+ (1.0,0.0) [0.0|1] ""  Vector__XXX
 SG_ Wischer_vorne_Schnell : 3|1@1+ (1.0,0.0) [0.0|1] ""  Vector__XXX
 SG_ Wischer_vorne_Parklage : 4|1@1+ (1.0,0.0) [0.0|1] ""  Vector__XXX
 SG_ Wischer_vorne_defekt : 6|1@1+ (1.0,0.0) [0.0|1] ""  Kombi,Kombi_LB,Kombi_PAG
 SG_ Wischer_vorne_blockiert : 7|1@1+ (1.0,0.0) [0.0|1] ""  Vector__XXX
 SG_ Wischer1_Wischgeschwindigkeit : 8|6@1+ (1,9) [10|70] "Unit_MinutInver"  Vector__XXX
 SG_ BCM1_SRA_aktiv : 14|1@1+ (1.0,0.0) [0.0|1] ""  Vector__XXX
 SG_ Heckwischer_Anforderung : 16|1@1+ (1.0,0.0) [0.0|1] ""  Vector__XXX
 SG_ WWSs_01_upd : 17|1@1+ (1.0,0.0) [0.0|1] ""  Vector__XXX
 SG_ Wischer_Anzeigetext : 18|2@1+ (1.0,0.0) [0.0|3] ""  Kombi,Kombi_LB,Kombi_PAG

BO_ 2527679496 WIV_02: 8 Gateway
 SG_ WIV_Verschleissindex_02 : 0|15@1+ (0.001,0) [0.000|32.766] ""  Kombi,Kombi_LB,Kombi_PAG
 SG_ WIV_Verschleissindex_Ueberlauf : 15|1@1+ (1.0,0.0) [0.0|1] ""  Kombi,Kombi_LB,Kombi_PAG
 SG_ WIV_Russindex_02 : 16|15@1+ (0.001,0) [0.000|32.766] ""  Kombi,Kombi_LB,Kombi_PAG
 SG_ WIV_Russindex_Ueberlauf : 31|1@1+ (1.0,0.0) [0.0|1] ""  Kombi,Kombi_LB,Kombi_PAG
 SG_ WIV_t_min : 32|6@1+ (1,0) [0|63] "Unit_Month"  Kombi,Kombi_LB,Kombi_PAG
 SG_ WIV_t_max : 40|6@1+ (1,0) [0|63] "Unit_Month"  Kombi,Kombi_LB,Kombi_PAG
 SG_ WIV_W_min : 48|7@1+ (1000,0) [0|127000] "Unit_KiloMeter"  Kombi,Kombi_LB,Kombi_PAG
 SG_ WIV_W_max : 56|7@1+ (1000,0) [0|127000] "Unit_KiloMeter"  Kombi,Kombi_LB,Kombi_PAG

BO_ 2617040384 XCP_HUD_CRO_01: 8 Vector__XXX
 SG_ XCP_HUD_CRO_01_Data : 0|64@1+ (1,0) [0|1] ""  HUD

BO_ 2617040385 XCP_HUD_DTO_01: 8 HUD
 SG_ XCP_HUD_DTO_01_Data : 0|64@1+ (1,0) [0|1] ""  Vector__XXX

BO_ 2617026048 XCP_Kombi_CRO_01: 8 Vector__XXX
 SG_ XCP_Kombi_CRO_01_Data : 0|64@1+ (1,0) [0|1] ""  Kombi,Kombi_LB,Kombi_PAG

BO_ 2617026049 XCP_Kombi_DTO_01: 8 Kombi
 SG_ XCP_Kombi_DTO_01_Data : 0|64@1+ (1,0) [0|1] ""  Vector__XXX

BO_ 2617155072 XCP_Waehlhebel_CRO_01: 8 Vector__XXX
 SG_ XCP_Waehlhebel_CRO_01_Data : 0|64@1+ (1,0) [0|1] ""  CGS,Waehlhebel_SB

BO_ 2617155073 XCP_Waehlhebel_DTO_01: 8 CGS
 SG_ XCP_Waehlhebel_DTO_01_Data : 0|64@1+ (1,0) [0|1] ""  Vector__XXX

BO_ 2527679655 Zentralrechner_03: 8 Gateway
 SG_ ZR_SOC_Weiterfahrt : 51|7@1+ (1,0) [0|100] "Unit_PerCent"  Vector__XXX
 SG_ MMI_StartupAnimation : 61|3@1+ (1.0,0.0) [0.0|7] ""  Kombi,Kombi_LB,Kombi_PAG

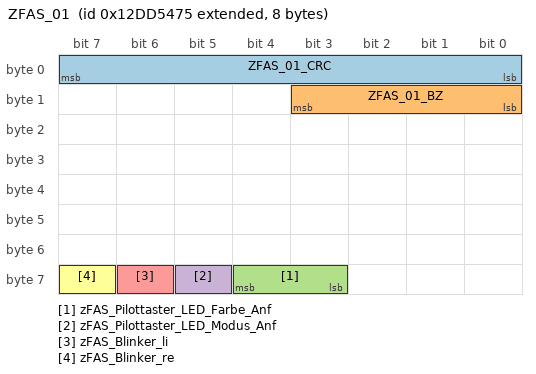
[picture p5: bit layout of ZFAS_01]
BO_ 2463978613 ZFAS_01: 8 Gateway
 SG_ ZFAS_01_CRC : 0|8@1+ (1,0) [0|255] ""  Vector__XXX
 SG_ ZFAS_01_BZ : 8|4@1+ (1,0) [0|15] ""  Vector__XXX
 SG_ zFAS_Pilottaster_LED_Farbe_Anf : 59|2@1+ (1.0,0.0) [0.0|3] ""  Waehlhebel_SB
 SG_ zFAS_Pilottaster_LED_Modus_Anf : 61|1@1+ (1.0,0.0) [0.0|1] ""  Waehlhebel_SB
 SG_ zFAS_Blinker_li : 62|1@1+ (1.0,0.0) [0.0|1] ""  Vector__XXX
 SG_ zFAS_Blinker_re : 63|1@1+ (1.0,0.0) [0.0|1] ""  Vector__XXX

BO_ 1411 ZV_02: 8 Gateway
 SG_ BCM_FH_Freigabe : 12|1@1+ (1.0,0.0) [0.0|1] ""  Vector__XXX
 SG_ BCM_Komfortfkt_Freigabe : 13|1@1+ (1.0,0.0) [0.0|1] ""  Vector__XXX
 SG_ BCM_HSK_Freigabe : 14|1@1+ (1.0,0.0) [0.0|1] ""  Vector__XXX
 SG_ BCM_Verdeck_Freigabe : 15|1@1+ (1.0,0.0) [0.0|1] ""  Vector__XXX
 SG_ ZV_verriegelt_intern_ist : 16|1@1+ (1.0,0.0) [0.0|1] ""  Vector__XXX
 SG_ ZV_verriegelt_extern_ist : 17|1@1+ (1.0,0.0) [0.0|1] ""  Kombi,Kombi_LB,Kombi_PAG
 SG_ ZV_verriegelt_intern_soll : 18|1@1+ (1.0,0.0) [0.0|1] ""  Vector__XXX
 SG_ ZV_verriegelt_extern_soll : 19|1@1+ (1.0,0.0) [0.0|1] ""  Vector__XXX
 SG_ ZV_gesafet_extern_ist : 20|1@1+ (1.0,0.0) [0.0|1] ""  Vector__XXX
 SG_ ZV_gesafet_extern_soll : 21|1@1+ (1.0,0.0) [0.0|1] ""  Vector__XXX
 SG_ ZV_Einzeltuerentriegelung : 22|1@1+ (1.0,0.0) [0.0|1] ""  Vector__XXX
 SG_ ZV_Heckeinzelentriegelung : 23|1@1+ (1.0,0.0) [0.0|1] ""  Vector__XXX
 SG_ ZV_FT_offen : 24|1@1+ (1.0,0.0) [0.0|1] ""  Kombi,Kombi_LB,Kombi_PAG
 SG_ ZV_BT_offen : 25|1@1+ (1.0,0.0) [0.0|1] ""  Kombi,Kombi_LB,Kombi_PAG
 SG_ ZV_HFS_offen : 26|1@1+ (1.0,0.0) [0.0|1] ""  Kombi,Kombi_LB,Kombi_PAG
 SG_ ZV_HBFS_offen : 27|1@1+ (1.0,0.0) [0.0|1] ""  Kombi,Kombi_LB,Kombi_PAG
 SG_ ZV_HD_offen : 28|1@1+ (1.0,0.0) [0.0|1] ""  Kombi,Kombi_LB,Kombi_PAG
 SG_ ZV_HS_offen : 29|1@1+ (1.0,0.0) [0.0|1] ""  Vector__XXX
 SG_ IRUE_aktiv : 30|1@1+ (1.0,0.0) [0.0|1] ""  Vector__XXX
 SG_ DWA_aktiv : 31|1@1+ (1.0,0.0) [0.0|1] ""  Vector__XXX
 SG_ HD_Hauptraste : 32|1@1+ (1.0,0.0) [0.0|1] ""  Vector__XXX
 SG_ HD_Vorraste : 33|1@1+ (1.0,0.0) [0.0|1] ""  Vector__XXX
 SG_ FFB_CarFinder : 38|1@1+ (1.0,0.0) [0.0|1] ""  Vector__XXX
 SG_ FFB_Komfortoeffnen : 39|1@1+ (1.0,0.0) [0.0|1] ""  Vector__XXX
 SG_ FFB_Komfortschliessen : 40|1@1+ (1.0,0.0) [0.0|1] ""  Vector__XXX
 SG_ ZV_Schluessel_Zugang : 42|4@1+ (1.0,0.0) [0.0|15] ""  Vector__XXX
 SG_ ZV_SafeFunktion_aktiv : 46|1@1+ (1.0,0.0) [0.0|1] ""  Kombi,Kombi_LB,Kombi_PAG
 SG_ FBS_Warn_Schluessel_Batt : 47|1@1+ (1.0,0.0) [0.0|1] ""  Vector__XXX
 SG_ ZV_Oeffnungsmodus : 48|2@1+ (1.0,0.0) [0.0|3] ""  Vector__XXX
 SG_ HFS_verriegelt : 50|1@1+ (1.0,0.0) [0.0|1] ""  Vector__XXX
 SG_ HFS_gesafet : 51|1@1+ (1.0,0.0) [0.0|1] ""  Vector__XXX
 SG_ HBFS_verriegelt : 52|1@1+ (1.0,0.0) [0.0|1] ""  Vector__XXX
 SG_ HBFS_gesafet : 53|1@1+ (1.0,0.0) [0.0|1] ""  Vector__XXX
 SG_ ZV_ist_Zustand_verfuegbar : 54|1@1+ (1.0,0.0) [0.0|1] ""  Vector__XXX
 SG_ IRUE_Taster_Fkts_LED : 55|1@1+ (1.0,0.0) [0.0|1] ""  Vector__XXX
 SG_ ZV_Tankklappe_offen : 56|1@1+ (1.0,0.0) [0.0|1] ""  Kombi,Kombi_LB,Kombi_PAG
 SG_ ZV_Rollo_auf : 57|1@1+ (1.0,0.0) [0.0|1] ""  Vector__XXX
 SG_ ZV_Rollo_zu : 58|1@1+ (1.0,0.0) [0.0|1] ""  Vector__XXX
 SG_ ZV_SAD_auf : 59|1@1+ (1.0,0.0) [0.0|1] ""  Vector__XXX
 SG_ ZV_SAD_zu : 60|1@1+ (1.0,0.0) [0.0|1] ""  Vector__XXX
 SG_ BCM_Tankklappensteller_Fehler : 61|1@1+ (1.0,0.0) [0.0|1] ""  Vector__XXX
 SG_ ZV_verriegelt_soll : 62|2@1+ (1.0,0.0) [0.0|3] ""  Vector__XXX

BO_TX_BU_ 974 :Gateway,Gateway_PAG;
BO_TX_BU_ 288 :Gateway,Gateway_PAG;
BO_TX_BU_ 798 :Gateway,Gateway_PAG;
BO_TX_BU_ 563 :Gateway,Gateway_PAG;
BO_TX_BU_ 1718 :Kombi,Kombi_LB,Kombi_PAG;
BO_TX_BU_ 618 :Gateway,Gateway_PAG;
BO_TX_BU_ 2463978633 :Gateway,Gateway_PAG;
BO_TX_BU_ 995 :Gateway,Gateway_PAG;
BO_TX_BU_ 1716 :Gateway,Gateway_PAG;
BO_TX_BU_ 385 :Gateway,Gateway_PAG;
BO_TX_BU_ 668 :Gateway,Gateway_PAG;
BO_TX_BU_ 2463978672 :Gateway,Gateway_PAG;
BO_TX_BU_ 181 :CGS,Kombi_LB,Waehlhebel_SB;
BO_TX_BU_ 2589283476 :CGS,Waehlhebel_SB;
BO_TX_BU_ 916 :Gateway,Gateway_PAG;
BO_TX_BU_ 2527679839 :Gateway,Gateway_PAG;
BO_TX_BU_ 1361 :Gateway,Gateway_PAG;
BO_TX_BU_ 1702 :Gateway,Gateway_PAG;
BO_TX_BU_ 2527679496 :Gateway,Gateway_PAG;
BO_TX_BU_ 2617026049 :Kombi,Kombi_LB,Kombi_PAG;
BO_TX_BU_ 2617155073 :CGS,Waehlhebel_SB;
BO_TX_BU_ 2527679655 :Gateway,Gateway_PAG;
BO_TX_BU_ 2463978613 :Gateway,Gateway_PAG;
BO_TX_BU_ 1411 :Gateway,Gateway_PAG;
CM_ BO_ 288 "Vorschlag TSK-Schnittstelle MQB";
CM_ BO_ 798 "ab MQB";
CM_ BO_ 995 "ab MQB IS5";
CM_ BO_ 1716 "200ms bei D4 und folgende";
CM_ BO_ 916 "ersetzt WBA_02";
CM_ BO_ 1702 "MLBevo";

CM_ SG_ 974 ASW_Warnung_aktiv_HFS "Abschaltung der Ambientefunktion Tür hinten der Fahrerseite bei aktiver ASW Warnung an der Fahrertür";
CM_ SG_ 974 HFS_FH_Bew_hoch "HFS Fenster bewegt sich in Richtung hoch";
CM_ SG_ 974 HFS_FH_Bew_tief "HFS Fenster bewegt sich in Richtung tief";
CM_ SG_ 974 HFS_FH_Block "Fensterscheibe befindet sich im mechanischen Block (oben oder unten)";
CM_ SG_ 974 HFS_FH_Fang "Fangbereich ist 4mm von oberer Lippendichtung";
CM_ SG_ 974 HFS_FH_normiert "Die Position der Fensterheberscheibe ist bekannt.";
CM_ SG_ 974 HFS_FH_Oeffnung "Gibt den Fensteröffnungswert in % an.";
CM_ SG_ 974 HFS_FH_S_AutoHoch "Betaetigung FH Schalter auto hoch";
CM_ SG_ 974 HFS_FH_S_AutoTief "Betaetigung FH Schalter auto tief ";
CM_ SG_ 974 HFS_FH_S_HBFS_AutoHoch "Automatisches Hochfahren der Seitenscheibe HBFS";
CM_ SG_ 974 HFS_FH_S_HBFS_AutoTief "Automatisches Absenken der Seitenscheibe HBFS";
CM_ SG_ 974 HFS_FH_S_HBFS_ManHoch "Manuelles Hochfahren der Seitenscheibe HBFS";
CM_ SG_ 974 HFS_FH_S_HBFS_ManTief "Manuelles Absenken der Seitenscheibe HBFS";
CM_ SG_ 974 HFS_FH_S_ManHoch "Betaetigung FH Schalter man hoch ";
CM_ SG_ 974 HFS_FH_S_ManTief "Betaetigung FH Schalter man tief";
CM_ SG_ 974 HFS_FH_Thermo "gibt an ob Fensterheber im Thermoschutz ist";
CM_ SG_ 974 HFS_gesafet "HFS Tuer gesafet.
Im Zustand Safe wird auch das Signal HFS_verriegelt = 1 gesendet.";
CM_ SG_ 974 HFS_Heckrollotaster_betaetigt "Verfahren des Heckrollos in Richtung Hoch

Bei Einfachtaster wird Bit als Togglebit verwendet (Heckrollo hoch, tief)";
CM_ SG_ 974 HFS_Lock_Taster "Betätigung Lock-Taster";
CM_ SG_ 974 HFS_Lock_Taster_inv "Lock Taster nicht betätigt";
CM_ SG_ 974 HFS_MRollo_Schalter "  | MRollo2
-----------------------------
0 | nicht_betaetigt
1 | (m) Zu
2 | (a) Zu
3 | (m) Auf
4 | (a) Auf
5 | Schalter nicht verfuegbar
6 | Init
7 | Fehlerfall";
CM_ SG_ 974 HFS_Oben_Block_erw "Fensterheber in Blockerwartung oben";
CM_ SG_ 974 HFS_SAD_Schalter "  |   Ausstelldach MD3
-----------------------------
0 | nicht_betaetigt
1 |
2 |
3 |
4 |
5 | (m) Auf
6 | (a) Auf
7 | (m) Zu
8 | (a) Zu
13| Schalter nicht verfuegbar
14| Init
15| Fehlerfall";
CM_ SG_ 974 HFS_Seitenrollo_hoch "Seitenrollo in Bewegung Richtung hoch";
CM_ SG_ 974 HFS_Seitenrollo_tief "Seitenrollo in Bewegung Richtung tief";
CM_ SG_ 974 HFS_Sperrklinke "Vorraste für Schloß

zwischen Vor- und Hauptraste Signal kurz auf 1, danach wieder auf 0 wenn Tür in Hauptraste (Tür ist sicher zu wenn Sperrklinke und Türkontakt auf 0 sind)";
CM_ SG_ 974 HFS_Status_eTAG "Status des elektrischen Tueraussengriffes Tuer Fahrerseite hinten";
CM_ SG_ 974 HFS_Status_KiSi "Status Kindersicherung hinten Fahrerseite";
CM_ SG_ 974 HFS_TAG_betaetigt "Betaetigung Türaussengriff";
CM_ SG_ 974 HFS_TCR_Mode_aktiv "Signal zeigt eine aktive mechanische Redundanz am Türschloss an.";
CM_ SG_ 974 HFS_TIG_betaetigt "Betaetigung Türinnengriff";
CM_ SG_ 974 HFS_Tuer_geoeffnet "HFS Tuer geoeffnet";
CM_ SG_ 974 HFS_Tuer_Status "Türstatus mit Fehler und Initwert";
CM_ SG_ 974 HFS_Tuer_Status_QBit "Dieses Bit gibt die Zuverlässigkeit des Türkontakts an. Ein auf dieses Bit folgender Fehlereintrag ist mit dem Sender des Bits abzustimmen (gültig ab PPE).";
CM_ SG_ 974 HFS_Tueroeffnen_Warnung "Bit wird gesetzt, wenn Tür während der Fahrt geoeffnet werden soll.";
CM_ SG_ 974 HFS_Tuerschloss_defekt "Das hintere Tuerschloss auf der Fahrerseite ist nicht mehr funktionsfähig.";
CM_ SG_ 974 HFS_UEKB_aktiviert "Überschutzbegrenzungskraft bei Reversieren";
CM_ SG_ 974 HFS_Unlock_Taster "Betaetigung Unlock Taster";
CM_ SG_ 974 HFS_Unten_Block_erw "Fensterheber in Blockerwartung unten";
CM_ SG_ 974 HFS_verriegelt "HFS Tuer verriegelt";
CM_ SG_ 974 HFS_Zuziehhilfe_aktiv "Zuziehhilfe aktiv";
CM_ SG_ 974 MTHFS_M_Taste "Betätigung M-Taste HFS";
CM_ SG_ 974 MTHFS_Pos1 "Betätigung Postionstaste 1 HFS";
CM_ SG_ 974 MTHFS_Pos2 "Betätigung Postionstaste 2 HFS
";
CM_ SG_ 974 MTHFS_Pos3 "Betätigung Postionstaste 3 HFS";
CM_ SG_ 974 SSR_HFS_Pos_Unten "Signal für die 'Global Close'. Über dieses Bit wissen die anderen TSGs, ob der SSR oder der FH verfahren werden darf.";

CM_ SG_ 288 TSK_06_BZ "Botschaft asynchron geroutet. Zählerwert kann springen.";
CM_ SG_ 288 TSK_06_CRC "Für MLB:
'Berechnung siehe Lastenheft 'Kommunikationsabsicherung für FlexRay und CAN''

Ab MQB und MLBevo:
'Berechnung siehe Lastenheft 'End-to-End Kommunikationsabsicherung''

Endwerte siehe Begleitdokument 'S-PDU Kennungsfolgen'";
CM_ SG_ 288 TSK_ax_Getriebe_02 "Beschleunigungsanforderung des Beschleunigungsreglers (u. a. für ACC, GRA, Speed Limiter). Das Signal wird vom Getriebe benutzt, um die von GRA/ACC geforderte Sollbeschleunigung in dem verbrauchsgünstigsten Gang einzustellen.
MQB: Im MQB wird die Sollbes";
CM_ SG_ 288 TSK_Freig_Verzoeg_Anf "Freigabe der Verzögerungsanforderung der ACC oder ggf. GRA+ Funktion für ECD Regelung im ESP";
CM_ SG_ 288 TSK_Freig_WU "Freigabe des TSK_Übersetzungswunsches bei ACC/GRA Betrieb bergab für die Verstellung nach kurz bzw. Rückschaltung im Getriebe.";
CM_ SG_ 288 TSK_Hauptschalter_GRA_ACC "Stellung des GRA/ACC Hauptschalters. Das Signal wird auch bei Fehlerabschaltungen von GRA/ACC weiterhin bedient und ermöglicht für ACC die Steuerung der ACC-Anzeige auch in Fehlerfällen.";
CM_ SG_ 288 TSK_Limiter_ausgewaehlt "ACC/GRA-Betrieb nur bei nicht ausgewähltem Limiter möglich";
CM_ SG_ 288 TSK_Radbremsmom "Bei der Schnittstelle vom TSK zum ESP soll in Folgeprojekten des B8 und insbesondere bei VW-Projekten die Ansteuerung der Bremse nicht über Sollbeschleunigung sondern Bremsmoment erfolgen.  Es handelt sich genauer um das Summenradbremsmoment, welches die ";
CM_ SG_ 288 TSK_SRBM_Anf_ASIL "ASIL-Level des TSK-Anforderers, der aktuell eine Bremsmomentenanforderung auslöst";
CM_ SG_ 288 TSK_Standby_Anf_ESP "Mit diesem Bit wird das aktive Bremssystem auf eine anstehende TSK-Verzögerungsanforderung vorbereitet (Überfahren Leerweg, Anlegen Bremsbeläge)";
CM_ SG_ 288 TSK_Status "Betriebszustand des TSK-Reglers";
CM_ SG_ 288 TSK_v_Begrenzung_aktiv "Limiter oder HGB begrenzen die Beschleunigung/das Moment";
CM_ SG_ 288 TSK_Wunsch_Uebersetz "Bei ACC/GRA Betrieb bergab teilt der TSK dem Getriebe mit, dass eine Drehzahlerhöhung erwünscht ist, um mehr Schleppmoment und damit verbunden die nötige Verzögerung zu erzeugen, um die Geschwindigkeit konstant zu halten. 

Nutzung im VL: das Getriebe v";
CM_ SG_ 288 TSK_zul_Regelabw "Anforderung der zulässigen Regelabweichung vom Triebstrangkoordinator. Zulässiger Betrag der Abweichung zwischen angeforderter 'TSK_Sollbeschleunigung_Getriebe' und umzusetzender Sollbeschleunigung  im Getriebe. Im TSK wird, abhängig vom Arbeitspunkt die ";
CM_ SG_ 288 TSK_Zwangszusch_ESP "Mit diesem Bit wird das ESP/ASR zwangsweise aktiviert. Bei gesetztem Bit ist ein ausgetastetes ESP (oder ASR) wieder aktiviert bzw. wird die Austastung verhindert.";

CM_ SG_ 798 MO_Motorlaufwarnung "Signal zur Anforderung der 'Motorlaufwarnung' im Kombi.";
CM_ SG_ 798 MO_Verlassenswarnung "Signal steuert die Verlassenswarnung im Kombi an.";
CM_ SG_ 798 TSK_07_CRC "Für MLB:
'Berechnung siehe Lastenheft 'Kommunikationsabsicherung für FlexRay und CAN''

Ab MQB und MLBevo:
'Berechnung siehe Lastenheft 'End-to-End Kommunikationsabsicherung''

Endwerte siehe Begleitdokument 'S-PDU Kennungsfolgen'";
CM_ SG_ 798 TSK_Akustik "Anforderung zur Ausgabe Akustischer Meldungen des Triebstrangkoordinators";
CM_ SG_ 798 TSK_Fahrzeugstatus_GRA "Zur Anzeige der Nicht-Verfuegbarkeit des Geschwindigkeitsregelanlage im Fahrzeugstatus";
CM_ SG_ 798 TSK_Fahrzeugstatus_Limiter "Zur Anzeige der Nicht-Verfuegbarkeit des Speedlimiters im Fahrzeugstatus";
CM_ SG_ 798 TSK_Fahrzeugstatus_praed_Fkt "Zeigt den Status der Prädiktion der Kundenfunktionen P_LIM und P_ GRA an";
CM_ SG_ 798 TSK_Limiter_Anzeige "Signalisiert den Wunsch des MSG an das Kombiinstrument, seine Anzeige auf Limiter umzuschalten";
CM_ SG_ 798 TSK_Limiter_Fahrerinfo "Fahrerhinweise und Warnungen des Speedlimiters";
CM_ SG_ 798 TSK_naechstes_Event "Anzeige des naechsten Streckenereignisses, welches in der PGRA-PLIM Regelung eine Änderung der Zielgeschwindigkeit zur Folge hat";
CM_ SG_ 798 TSK_naechstes_Event_Einheit "Das Signal zeigt an in welcher Einheit der Hinweis anzuzeigen ist. Bspw. Schilder in mph und Anzeige in Km/h";
CM_ SG_ 798 TSK_praediktiver_Automode "Signal zur Anzeige des Automodes bei praediktivem Limiter/GRA";
CM_ SG_ 798 TSK_praediktiver_Hinweis "Anzeigesteuerung ob Geschwindigkeitshinweis als Vorschlag (zur Übernahme) oder als Hinweis (bei automatischer Übernahme) behandelt werden soll";
CM_ SG_ 798 TSK_Status_Anzeige "Signalisiert den Status von GRA oder Limiter zur Anzeige im Kombiinstrument.
Der Signalwert 'Limitierung_aktiv' wird nur verwendet für den Audi Speedlimiter und zeigt bei aktivier Funktion an, dass nahe an der Abregelgeschwindigkeit gefahren wird und die";
CM_ SG_ 798 TSK_Texte "Textmeldungen des TSK zur Darstellung im Kombi";
CM_ SG_ 798 TSK_Texte_Primaeranz "Trigger für Anzeigetexte von GRA und Limiter, GRA Temporäranzeige (Audi) und Limiter Warnungen

0 keine Anzeige 
1 GRA Symbol passiv xxx km/h / mph (nur Audi)
2 GRA Symbol aktiv xxx km/h / mph (nur Audi)
3 Bremse überhitzt ! (reserv.)
4 Limiter Modu";
CM_ SG_ 798 TSK_Wunschgeschw "Zur Anzeige der Wunschgeschwindigkeit von GRA/Speedlimiter im Kombiinstrument";

CM_ SG_ 563 TSK_praed_Wunschgeschw "Zur Anzeige der prädiktiven Wunschgeschwindigkeit von GRA/Speedlimiter im Kombiinstrument";

CM_ SG_ 1718 UH_Minute "0x3C- 0x3f = Werte ungültig";
CM_ SG_ 1718 UH_Monat "0x0D, 0xF =  Werte ungültig
0x0E = Relatives Datum (nur VW)";
CM_ SG_ 1718 UH_Sekunde "0x3C- 0x3f = Werte ungültig";
CM_ SG_ 1718 UH_Stunde "0x18 - 0x1F = Werte ungültig";
CM_ SG_ 1718 UH_Tag "0x0: reserviert bei VW";
CM_ SG_ 1718 UH_Typ "0x4 - 0x7 = tbd. ";

CM_ SG_ 618 USS_Fahrer_Texte "Textdefinitionen";
CM_ SG_ 618 USS_Fahrzeit_seit_Pause "Fahrzeit seit Pause";
CM_ SG_ 618 USS_MKE_Index "Aktuell abgeschätzter Wert Fahrerzustand. 0 - 10 mit Auflösung 1/10.";
CM_ SG_ 618 USS_MKE_Index_Anstieg "Anstieg des Indexwertes";
CM_ SG_ 618 USS_MKE_Index_Quelle_Biometrisch "Verwendung von einer biometrischen Quelle für die Berechnung MKE Index";
CM_ SG_ 618 USS_MKE_Index_Quelle_FBK "Verwendung FBK für Berechnung MKE Index (kMKE)";
CM_ SG_ 618 USS_MKE_Index_Quelle_LWS_Basis "Verwendung LWS Basis für Berechnung MKE Index";
CM_ SG_ 618 USS_MKE_Index_Quelle_LWS_Plus "Verwendung LWS Plus für Berechnung MKE Index";
CM_ SG_ 618 USS_MKE_Index_Quelle_MFK "Verwendung MFK für Berechnung MKE Index";
CM_ SG_ 618 USS_MKE_Risiko "MKE-Risikoeinschätzung des Fahrers.";

CM_ SG_ 2463978633 VAS_L_01_BZ "4bit Botschaftszähler, wird mit jeder Sendebotschaft inkrementiert";
CM_ SG_ 2463978633 VAS_L_01_CRC "Für MLB:
Berechnung siehe Lastenheft 'Kommunikationsabsicherung für FlexRay und CAN'
Ab MQB und MLBevo:
Berechnung siehe Lastenheft 'End-to-End Kommunikationsabsicherung'

Endwerte siehe Begleitdokument 'S-PDU Kennungsfolgen'";
CM_ SG_ 2463978633 VAS_L_Autobahnview_aktiv "Status ob Autobahnview aktiv ist oder nicht";
CM_ SG_ 2463978633 VAS_L_Bedien_Master "Gibt an dass das linke Steuergerät Bedien Master ist";
CM_ SG_ 2463978633 VAS_L_Heizung_Aktiv "VAS rechts Heizung aktiv";
CM_ SG_ 2463978633 VAS_L_HMI_Aktiv "Gibt an ob das HMI angezeigt wird";
CM_ SG_ 2463978633 VAS_L_Parkview_aktiv "VAS links Parkview aktiv";
CM_ SG_ 2463978633 VAS_L_Spiegelauswahl "VAS links Spiegelauswahl";
CM_ SG_ 2463978633 VAS_L_SWA_HMI_Diagnose "SWA HMI Diagnose beim VAS";
CM_ SG_ 2463978633 VAS_L_Texte "Signal uebermittelt die Fahrerhinweise zum Kombi muss E2E abgesichert werden";
CM_ SG_ 2463978633 VAS_L_Turnview_aktiv "Status Turnview Anzeige";
CM_ SG_ 2463978633 VAS_L_Verstell_Pos_X "VAS links Spiegel Verstellposition X";
CM_ SG_ 2463978633 VAS_L_Verstell_Pos_Y "VAS links Spiegel Verstellposition Y";
CM_ SG_ 2463978633 VAS_L_Zoom_Level "VAS links Zoom Level Display";

CM_ SG_ 995 VD_SpannungsAnf "Anforderung Forderung des Verdecks zur Spannungsanhebung des Bordnetzes.";
CM_ SG_ 995 Verdeck_01_BZ "4bit Botschaftszähler, wird mit jeder Sendebotschaft inkrementiert";
CM_ SG_ 995 Verdeck_01_CRC "Für MLB:
Berechnung siehe Lastenheft 'Kommunikationsabsicherung für FlexRay und CAN'
Ab MQB und MLBevo:
Berechnung siehe Lastenheft 'End-to-End Kommunikationsabsicherung'

Endwerte siehe Begleitdokument 'S-PDU Kennungsfolgen'";
CM_ SG_ 995 VS_BFS_AutoHoch "automatischer Hochlauf des BFS Fenster ausgelöst durch die Verdecksteuerung";
CM_ SG_ 995 VS_BFS_AutoTief "automatischer Tieflauf des BFS Fenster ausgelöst durch die Verdecksteuerung";
CM_ SG_ 995 VS_BFS_ManHoch "manueller Hochlauf des BFS Fenster ausgelöst durch die Verdecksteuerung";
CM_ SG_ 995 VS_BFS_ManTief "manueller Tieflauf des BFS Fenster ausgelöst durch die Verdecksteuerung";
CM_ SG_ 995 VS_Buzzer "Buzzeransteuerung: 'Buzzeransteuerung' für Gong 200ms (Kombi)";
CM_ SG_ 995 VS_FH_BT_Langhub "Ansteuerung Fensterheber vom Verdecksteuergeraet";
CM_ SG_ 995 VS_FH_FT_Langhub "Ansteuerung Fensterheber vom Verdecksteuergeraet";
CM_ SG_ 995 VS_FH_HBFS_Langhub "Ansteuerung Fensterheber vom Verdecksteuergeraet";
CM_ SG_ 995 VS_FH_HFS_Langhub "Ansteuerung Fensterheber vom Verdecksteuergeraet";
CM_ SG_ 995 VS_FS_AutoHoch "automatischer Hochlauf des FS Fenster ausgelöst durch die Verdecksteuerung";
CM_ SG_ 995 VS_FS_AutoTief "automatischer Tieflauf des FS Fenster ausgelöst durch die Verdecksteuerung";
CM_ SG_ 995 VS_FS_ManHoch "manueller Hochlauf des FS Fenster ausgelöst durch die Verdecksteuerung";
CM_ SG_ 995 VS_FS_ManTief "manueller Tieflauf des FS Fenster ausgelöst durch die Verdecksteuerung";
CM_ SG_ 995 VS_Hardtop "Hardtop montiert";
CM_ SG_ 995 VS_HBFS_AutoHoch "automatischer Hochlauf des HBFS Fenster ausgelöst durch die Verdecksteuerung";
CM_ SG_ 995 VS_HBFS_AutoTief "automatischer Tieflauf des HBFS Fenster ausgelöst durch die Verdecksteuerung";
CM_ SG_ 995 VS_HBFS_ManHoch "manueller Hochlauf des HBFS Fenster ausgelöst durch die Verdecksteuerung";
CM_ SG_ 995 VS_HBFS_ManTief "manueller Tieflauf des HBFS Fenster ausgelöst durch die Verdecksteuerung";
CM_ SG_ 995 VS_HD_sperren "Bei gesetztem Signal wird der Kofferraum/Heckdeckel durch den BCM2 nicht entriegelt werden.";
CM_ SG_ 995 VS_Heckschloss_auf "Signal wird gesetzt, wenn fuer einen Verdeckbetrieb das Öffnen des Heckschlosses erforderlich ist.";
CM_ SG_ 995 VS_HFS_AutoHoch "automatischer Hochlauf des HFS Fenster ausgelöst durch die Verdecksteuerung";
CM_ SG_ 995 VS_HFS_AutoTief "automatischer Tieflauf des HFS Fenster ausgelöst durch die Verdecksteuerung";
CM_ SG_ 995 VS_HFS_ManHoch "manueller Hochlauf des HFS Fenster ausgelöst durch die Verdecksteuerung";
CM_ SG_ 995 VS_HFS_ManTief "manueller Tieflauf des HFS Fenster ausgelöst durch die Verdecksteuerung";
CM_ SG_ 995 VS_HHS_enable "Fehlende Beschreibung (Import)";
CM_ SG_ 995 VS_Lampe_Blk "Ansteuerung Lampe im Kombi

Wird aktiviert bei Aufprüfen, Verdecklauf und Fehlerfall (blinkend).


";
CM_ SG_ 995 VS_StartStopp_Info "Stopp-Freigabe und Start-Anforderung an den Start-Stopp-Koordinator";
CM_ SG_ 995 VS_VD_Bew_auf "



";
CM_ SG_ 995 VS_VD_Bew_zu "


";
CM_ SG_ 995 VS_VD_entriegelt "Zustand des Verdeck entriegelt";
CM_ SG_ 995 VS_VD_Fehler "Fehlerzustand Verdeck";
CM_ SG_ 995 VS_VD_offen_ver "Zustand des Verdecks verriegelt und offen";
CM_ SG_ 995 VS_VD_zu_ver "
";
CM_ SG_ 995 VS_VD_Zwischenposition "Verdeck in Zwischenposition";
CM_ SG_ 995 VS_VDKD_auf "Signal wird gesetzt, wenn der Verdeckkastendeckel vollstaendig geoeffnet ist



";
CM_ SG_ 995 VS_Verdeck_Anf "Verdeckanforderung (Signalisierung der Bereitschaft zur Verdeckbetaetigung ueber Komfortfunktion)";
CM_ SG_ 995 VS_Windschott_nicht_abgelegt "Windschott ist aufgestellt, in Zwischenposition oder die Position ist unbekannt";
CM_ SG_ 995 VSG_Meldungen "Meldungen fuers Kombi lt. konzernübergreifender Abstimmung

0 -> keine Meldung
1 -> 'Verdeckbetrieb RDW aktiv'
2 -> 'Verdeckbetrieb NAR aktiv'
3 -> 'stehendes Verdeck in Zwischenposition (ZP)'
4 -> 'autom. Verdeck in ZP und KL15 aus'
5 -> 'manuelle";

CM_ SG_ 1716 VIN_01_MUX "Achtung:
Die Botschaft ist nicht linear gemultiplext!!!
Sondern 0,1,0,2,0, usw.";
CM_ SG_ 1716 VIN_1 "Initwert:
0x2D bei Fahrzeugen mit Wegfahrsperrengeneration >= 5 
0x58 bei Fahrzeugen mit Wegfahrsperrengeneration < 5 (z.B. WFS-4)";
CM_ SG_ 1716 VIN_10 "Initwert:
0x2D bei Fahrzeugen mit Wegfahrsperrengeneration >= 5 
0x58 bei Fahrzeugen mit Wegfahrsperrengeneration < 5 (z.B. WFS-4)";
CM_ SG_ 1716 VIN_11 "Initwert:
0x2D bei Fahrzeugen mit Wegfahrsperrengeneration >= 5 
0x58 bei Fahrzeugen mit Wegfahrsperrengeneration < 5 (z.B. WFS-4)";
CM_ SG_ 1716 VIN_12 "Initwert:
0x2D bei Fahrzeugen mit Wegfahrsperrengeneration >= 5 
0x58 bei Fahrzeugen mit Wegfahrsperrengeneration < 5 (z.B. WFS-4)";
CM_ SG_ 1716 VIN_13 "Initwert:
0x2D bei Fahrzeugen mit Wegfahrsperrengeneration >= 5 
0x58 bei Fahrzeugen mit Wegfahrsperrengeneration < 5 (z.B. WFS-4)";
CM_ SG_ 1716 VIN_14 "Initwert:
0x2D bei Fahrzeugen mit Wegfahrsperrengeneration >= 5 
0x58 bei Fahrzeugen mit Wegfahrsperrengeneration < 5 (z.B. WFS-4)";
CM_ SG_ 1716 VIN_15 "Initwert:
0x2D bei Fahrzeugen mit Wegfahrsperrengeneration >= 5 
0x58 bei Fahrzeugen mit Wegfahrsperrengeneration < 5 (z.B. WFS-4)";
CM_ SG_ 1716 VIN_16 "Initwert:
0x2D bei Fahrzeugen mit Wegfahrsperrengeneration >= 5 
0x58 bei Fahrzeugen mit Wegfahrsperrengeneration < 5 (z.B. WFS-4)";
CM_ SG_ 1716 VIN_17 "Initwert:
0x2D bei Fahrzeugen mit Wegfahrsperrengeneration >= 5 
0x58 bei Fahrzeugen mit Wegfahrsperrengeneration < 5 (z.B. WFS-4)";
CM_ SG_ 1716 VIN_2 "Initwert:
0x2D bei Fahrzeugen mit Wegfahrsperrengeneration >= 5 
0x58 bei Fahrzeugen mit Wegfahrsperrengeneration < 5 (z.B. WFS-4)";
CM_ SG_ 1716 VIN_3 "Initwert:
0x2D bei Fahrzeugen mit Wegfahrsperrengeneration >= 5 
0x58 bei Fahrzeugen mit Wegfahrsperrengeneration < 5 (z.B. WFS-4)";
CM_ SG_ 1716 VIN_4 "Initwert:
0x2D bei Fahrzeugen mit Wegfahrsperrengeneration >= 5 
0x58 bei Fahrzeugen mit Wegfahrsperrengeneration < 5 (z.B. WFS-4)";
CM_ SG_ 1716 VIN_5 "Initwert:
0x2D bei Fahrzeugen mit Wegfahrsperrengeneration >= 5 
0x58 bei Fahrzeugen mit Wegfahrsperrengeneration < 5 (z.B. WFS-4)";
CM_ SG_ 1716 VIN_6 "Initwert:
0x2D bei Fahrzeugen mit Wegfahrsperrengeneration >= 5 
0x58 bei Fahrzeugen mit Wegfahrsperrengeneration < 5 (z.B. WFS-4)";
CM_ SG_ 1716 VIN_7 "Initwert:
0x2D bei Fahrzeugen mit Wegfahrsperrengeneration >= 5 
0x58 bei Fahrzeugen mit Wegfahrsperrengeneration < 5 (z.B. WFS-4)";
CM_ SG_ 1716 VIN_8 "Initwert:
0x2D bei Fahrzeugen mit Wegfahrsperrengeneration >= 5 
0x58 bei Fahrzeugen mit Wegfahrsperrengeneration < 5 (z.B. WFS-4)";
CM_ SG_ 1716 VIN_9 "Initwert:
0x2D bei Fahrzeugen mit Wegfahrsperrengeneration >= 5 
0x58 bei Fahrzeugen mit Wegfahrsperrengeneration < 5 (z.B. WFS-4)";

CM_ SG_ 385 VZE_Akustik_Limitwechsel "Anforderung eines Signaltons bei Tempolimitwechsel.";
CM_ SG_ 385 VZE_Anzeigemodus "Steuert die verschiedenen Möglichkeiten der Anzeige.";
CM_ SG_ 385 VZE_Anzeigeunterdrueck_Zeichen_1 "Steuerungssignal zur Steuerung der Sichtbarkeit von Verkehrszeichen ";
CM_ SG_ 385 VZE_Anzeigeunterdrueck_Zeichen_2 "Anzeigerelevanz des Zeichens in VZE_Verkehrszeichen_2";
CM_ SG_ 385 VZE_Anzeigeunterdrueck_Zeichen_3 "Anzeigerelevanz des Zeichens in VZE_Verkehrszeichen_3";
CM_ SG_ 385 VZE_Gong "Das Signal signalisiert dem Kombiinstrument ob bei der VZE-Tempowarnung ein Gong getriggert werden soll.";
CM_ SG_ 385 VZE_Hinweistext "Über Index wird ein Hinweistext beschrieben, der durch das Kombi dargestellte werden soll.

Wertebereich lt. Hashtabelle";
CM_ SG_ 385 VZE_Modus_OptischeWarnung "Das Signal gibt an, ob eine optische Warnung blinkend oder dauerhaft ausgegeben werden soll.";
CM_ SG_ 385 VZE_Verkehrszeichen_1 "Das Signal spiegelt eines der Verkehrszeichen: Geschwindigkeitsgebot, Überholverbot, Aufhebungszeichen wider.

Wertebereich lt. Hashtabelle";
CM_ SG_ 385 VZE_Verkehrszeichen_2 "Das Signal spiegelt eines der Verkehrszeichen: Geschwindigkeitsgebot, Überholverbot, Aufhebungszeichen wider.

Wertebereich lt. Hashtabelle";
CM_ SG_ 385 VZE_Verkehrszeichen_3 "Das Signal spiegelt eines der Verkehrszeichen: Geschwindigkeitsgebot, Überholverbot, Aufhebungszeichen wider.

Wertebereich lt. Hashtabelle";
CM_ SG_ 385 VZE_Verkehrszeichen_Einheit "Signal gibt an ob das übertragene Verkehrszeichen in mph oder km/h übermittelt wird";
CM_ SG_ 385 VZE_Warnung_Verkehrszeichen_1 "Ist das Signal gesetzt, so ist für das Verkehrszeichen 1 eine Warnung auszugeben.";
CM_ SG_ 385 VZE_Warnung_Verkehrszeichen_2 "Ist das Signal gesetzt, so ist für das Verkehrszeichen 2 eine Warnung auszugeben.";
CM_ SG_ 385 VZE_Warnung_Verkehrszeichen_3 "Ist das Signal gesetzt, so ist für das Verkehrszeichen 3 eine Warnung auszugeben.";
CM_ SG_ 385 VZE_Zeichen_01_Gesetz "Das VZE-Tempolimit in Verkehrszeichen1  ist das gesetzlich geltende Tempolimit (je Land/Straßenklasse).";
CM_ SG_ 385 VZE_Zeichen_01_Kamera "Das VZE-Tempolimit in Verkehrszeichen1 wurde von der Kamera erkannt.";
CM_ SG_ 385 VZE_Zeichen_01_KameraWied "Das VZE-Tempolimit  in Verkehrszeichen1 wurde als Wiederholungsschild von der Kamera erkannt.";
CM_ SG_ 385 VZE_Zeichen_01_Karte "Das VZE-Tempolimit in Verkehrszeichen1 stammt aus den Navigationskartendaten.";
CM_ SG_ 385 VZE_Zeichen_02_Gesetz "Das VZE-Tempolimit in Verkehrszeichen2  ist das gesetzlich geltende Tempolimit (je Land/Straßenklasse).";
CM_ SG_ 385 VZE_Zeichen_02_Kamera "Das VZE-Tempolimit in Verkehrszeichen2 wurde von der Kamera erkannt.";
CM_ SG_ 385 VZE_Zeichen_02_KameraWied "Das VZE-Tempolimit  in Verkehrszeichen2 wurde als Wiederholungsschild von der Kamera erkannt.";
CM_ SG_ 385 VZE_Zeichen_02_Karte "Das VZE-Tempolimit in Verkehrszeichen2 stammt aus den Navigationskartendaten.";
CM_ SG_ 385 VZE_Zeichen_03_Gesetz "Das VZE-Tempolimit in Verkehrszeichen3  ist das gesetzlich geltende Tempolimit (je Land/Straßenklasse).";
CM_ SG_ 385 VZE_Zeichen_03_Kamera "Das VZE-Tempolimit in Verkehrszeichen3 wurde von der Kamera erkannt.";
CM_ SG_ 385 VZE_Zeichen_03_KameraWied "Das VZE-Tempolimit  in Verkehrszeichen3 wurde als Wiederholungsschild von der Kamera erkannt.";
CM_ SG_ 385 VZE_Zeichen_03_Karte "Das VZE-Tempolimit in Verkehrszeichen3 stammt aus den Navigationskartendaten.";
CM_ SG_ 385 VZE_Zusatzschild_1 "Zusatzsschild, das zu Verkehrszeichen 1 angezeigt werden soll.

Wertebereich lt. Hashtabelle";
CM_ SG_ 385 VZE_Zusatzschild_2 "Zusatzsschild, das zu Verkehrszeichen 2 angezeigt werden soll.

Wertebereich lt. Hashtabelle";
CM_ SG_ 385 VZE_Zusatzschild_3 "Zusatzsschild, das zu Verkehrszeichen 3 angezeigt werden soll.

Wertebereich lt. Hashtabelle";

CM_ SG_ 668 VZE_Akustik_Limitwechsel_Status "Das Signal überträgt die Information, ob der Kunde, in den Einstellungen, die akustische Information, bei einem Tempolimitwechsel, ausgewählt hat.";
CM_ SG_ 668 VZE_Anhaenger_Vmax "Übertragung der aus Kundeneinstellung und länderspezifischen Regelungen (StVO, Rechtsprechung...) berechneten legalen Höchstgeschwindigkeit für das Gespann.

10+ 0*10 = 10 km/h
10+ 1*10 = 20 km/h
...
10+ 5*10 = 60 km/h
10+ 6*10 = 70 km/h
...
10+ 1";
CM_ SG_ 668 VZE_Anzeigeunterdrueck_Zeichen_4 "Anzeigerelevanz des Zeichens in VZE_Anzeigerelevanz_Zeichen_4";
CM_ SG_ 668 VZE_Anzeigeunterdrueck_Zeichen_5 "Anzeigerelevanz des Zeichens in VZE_Anzeigerelevanz_Zeichen_5";
CM_ SG_ 668 VZE_Baustelle "Das Signal gibt an, ob aktuell ein Baustellenschild von der VZE erkannt wurde.";
CM_ SG_ 668 VZE_SLWF_Status "Das Signal zeigt den SLWF Zustand der VZE an.";
CM_ SG_ 668 VZE_Verkehrszeichen_4 "Das Signal spiegelt eines der Verkehrszeichen: Geschwindigkeitsgebot, Überholverbot, Aufhebungszeichen wider.

Wertebereich lt. Hashtabelle";
CM_ SG_ 668 VZE_Verkehrszeichen_5 "Das Signal spiegelt eines der Verkehrszeichen: Geschwindigkeitsgebot, Überholverbot, Aufhebungszeichen wider.

Wertebereich lt. Hashtabelle";
CM_ SG_ 668 VZE_Warnung_Verkehrszeichen_4 "Ist das Signal gesetzt, so ist für das Verkehrszeichen 4 eine Warnung auszugeben.";
CM_ SG_ 668 VZE_Warnung_Verkehrszeichen_5 "Ist das Signal gesetzt, so ist für das Verkehrszeichen 5 eine Warnung auszugeben.";
CM_ SG_ 668 VZE_Zeichen_04_Gesetz "Das VZE-Tempolimit ist das gesetzlich geltende Tempolimit (je Land/Straßenklasse).";
CM_ SG_ 668 VZE_Zeichen_04_Kamera "Das VZE-Tempolimit wurde von der Kamera erkannt.";
CM_ SG_ 668 VZE_Zeichen_04_KameraWied "Das VZE-Tempolimit wurde als Wiederholungsschild von der Kamera erkannt.";
CM_ SG_ 668 VZE_Zeichen_04_Karte "Das VZE-Tempolimit stammt aus den Navigationskartendaten.";
CM_ SG_ 668 VZE_Zeichen_05_Entfernung "In dem Signal wird die Entfernung zum Verkehrszeichen5 übertragen";
CM_ SG_ 668 VZE_Zeichen_05_Entfernung_StdA "In dem Signal wird die Standardabweichung bzgl. der Entfernung zum Verkehrszeichen5 übertragen ";
CM_ SG_ 668 VZE_Zeichen_05_Gesetz "Das VZE-Tempolimit ist das gesetzlich geltende Tempolimit (je Land/Straßenklasse).";
CM_ SG_ 668 VZE_Zeichen_05_Kamera "Das VZE-Tempolimit wurde von der Kamera erkannt.";
CM_ SG_ 668 VZE_Zeichen_05_KameraWied "Das VZE-Tempolimit wurde als Wiederholungsschild von der Kamera erkannt.";
CM_ SG_ 668 VZE_Zeichen_05_Karte "Das VZE-Tempolimit stammt aus den Navigationskartendaten.";
CM_ SG_ 668 VZE_Zusatzschild_4 "Zusatzsschild, das zu Verkehrszeichen 4 angezeigt werden soll.

Wertebereich lt. Hashtabelle";
CM_ SG_ 668 VZE_Zusatzschild_5 "Zusatzsschild, das zu Verkehrszeichen 5 angezeigt werden soll.

Wertebereich lt. Hashtabelle";

CM_ SG_ 2463978672 VZE_Anzeige_VZ_1 "Das Signal spiegelt eines der Verkehrszeichen: Geschwindigkeitsgebot, Überholverbot, Aufhebungszeichen wider.

Wertebereich lt. Hashtabelle";
CM_ SG_ 2463978672 VZE_Anzeige_VZ_2 "Das Signal spiegelt eines der Verkehrszeichen: Geschwindigkeitsgebot, Überholverbot, Aufhebungszeichen wider.

Wertebereich lt. Hashtabelle";
CM_ SG_ 2463978672 VZE_Anzeige_VZ_3 "Das Signal spiegelt eines der Verkehrszeichen: Geschwindigkeitsgebot, Überholverbot, Aufhebungszeichen wider.

Wertebereich lt. Hashtabelle";
CM_ SG_ 2463978672 VZE_Anzeige_ZS_1 "Zusatzsschild, das zu Verkehrszeichen 1 angezeigt werden soll.

Wertebereich lt. Hashtabelle";
CM_ SG_ 2463978672 VZE_Anzeige_ZS_2 "Zusatzsschild, das zu Verkehrszeichen 1 angezeigt werden soll.

Wertebereich lt. Hashtabelle";
CM_ SG_ 2463978672 VZE_Anzeige_ZS_3 "Zusatzsschild, das zu Verkehrszeichen 1 angezeigt werden soll.

Wertebereich lt. Hashtabelle";
CM_ SG_ 2463978672 VZE_FoD_Status "Status der VZE für FoD";
CM_ SG_ 2463978672 VZE_Hinweistext_03 "Über Index wird ein Hinweistext beschrieben, der durch das Kombi dargestellte werden soll.

Wertebereich lt. Hashtabelle";
CM_ SG_ 2463978672 VZE_Land "Steuert die verschiedenen Möglichkeiten der Anzeige.";
CM_ SG_ 2463978672 VZE_Warnung_VZ_1 "Ist das Signal gesetzt, so ist für das Verkehrszeichen 1 eine Warnung auszugeben.";
CM_ SG_ 2463978672 VZE_Warnung_VZ_2 "Ist das Signal gesetzt, so ist für das Verkehrszeichen 1 eine Warnung auszugeben.";
CM_ SG_ 2463978672 VZE_Warnung_VZ_3 "Ist das Signal gesetzt, so ist für das Verkehrszeichen 1 eine Warnung auszugeben.";

CM_ SG_ 181 Waehlhebel_04_CRC "Für MLB:
'Berechnung siehe Lastenheft 'Kommunikationsabsicherung für FlexRay und CAN''

Ab MQB und MLBevo:
'Berechnung siehe Lastenheft 'End-to-End Kommunikationsabsicherung''

Endwerte siehe Begleitdokument 'S-PDU Kennungsfolgen'";
CM_ SG_ 181 WH_Ende_N_Haltephase "Signalisiert dem Getriebe/ASG das Ende der N-Haltephase, damit die Parksperre eingelegt werden kann.";
CM_ SG_ 181 WH_Entsperrtaste_02 "Das Bit zeigt den entprellten Status der Entsperrtaste am Wählhebel an, inklusive Fehler- und Init-Zuständen.";
CM_ SG_ 181 WH_Fahrstufe "Fahrstufenwunsch der Schaltbetätigung (berechnet aus Fahreraktion am Bedienelement)";
CM_ SG_ 181 WH_gespeicherte_Fahrstufe "Kurzzeit-Fahrstufenspeicherung in Abhängigkeit von GE_Ist_Fahrstufe.";
CM_ SG_ 181 WH_Initialisierung "Das Bit zeigt dem Empfänger an, dass der Wählhebel in der Initialisierung ist (z.B. Reset). Das Signal steht für maximal 500ms ab Sendebeginn auf 1, danach dauerhaft auf 0.";
CM_ SG_ 181 WH_Ist_Haltemagnet "Status der Ansteuerung des Parksperren - Haltemagneten im Waehlhebel";
CM_ SG_ 181 WH_P_Taste "Das Signal zeigt den Status der P-Taste an.";
CM_ SG_ 181 WH_SensorPos_roh "Zustand Wählhebelposition. Wird das Signal WH_Variante nicht bedient, ist die Signalcodierung 
wie im MQB zu verwenden.

MQB:
0=Init
1=Position_1
2=Position_2
3=Position_3
4=nicht_betaetigt
5=Position_D
6=Position_N
7=Position_R
8=Position_P
";
CM_ SG_ 181 WH_SensorPos_roh_inv "Zustand Wählhebelposition. Wird das Signal WH_Variante nicht bedient, ist die Signalcodierung 
wie im MQB zu verwenden.

MQB:
0=Fehler
1=Position_Tipp_Gasse
2=Position_L
3=Position_S
4=Position_Tipp_-
5=Position_Tipp_+
6=Position_N_ohne_Spotausl";
CM_ SG_ 181 WH_Status_Shiftlock "Status des Hardware-Shiftlocks (die Schaltbetätigung kann in P oder N gesperrt werden)";
CM_ SG_ 181 WH_Test_Aktiv "Das Bit wird auf 1 gesetzt, wenn ein gültiges Testergebnis (Antwort) gesendet wird.";
CM_ SG_ 181 WH_Testergebnis "Ergebnis (Antwort) des Controllertests initiert durch Test Freigabe Flag
und Testparameter 1 + 2";
CM_ SG_ 181 WH_Variante "Verwendete Schaltungs-Variante im Fahrzeug
Beschreibung:

Rastierter Wählhebel
Übermittlung Absolutpositionen P,R,N,D,S,M

Tasten:
Übermittlung Absolutpositionen P,R,N,D

Monostabil_2x2:
Übermittlung Relativpositionen, Entsperrtaste und P-Taste";

CM_ SG_ 2589283476 WH_Warnung_02 "Warnmeldungen vom Waehlhebel an das Kombi";
CM_ SG_ 2589283476 WH_Warnung_03 "Warnungen des CGS im Lambo Urus";

CM_ SG_ 916 GE_Sollgang "Signalisiert den Sollgang, in den getippt werden soll. Abhängig vom Signal 'WBA_eing_Gang_02' und dem Sollgang kann dann das Kombi die Hochschaltempfehlung in Tip darstellen.";
CM_ SG_ 916 GE_Stoppverbot_Anz_01 "Dieses Signal gibt die detaillierte Begründung für ein Stoppverbot vom Getriebesteuergerät an.";
CM_ SG_ 916 GE_Stoppverbot_Anz_02 "Dieses Signal gibt die detaillierte Begründung für ein Stoppverbot vom Getriebesteuergerät an.";
CM_ SG_ 916 GE_Stoppverbot_Anz_03 "Dieses Signal gibt die detaillierte Begründung für ein Stoppverbot vom Getriebesteuergerät an.";
CM_ SG_ 916 GE_Stoppverbot_Anz_04 "Dieses Signal gibt die detaillierte Begründung für ein Stoppverbot vom Getriebesteuergerät an.";
CM_ SG_ 916 GE_Stoppverbot_Anz_05 "Dieses Signal gibt die detaillierte Begründung für ein Stoppverbot vom Getriebesteuergerät an.";
CM_ SG_ 916 GE_Stoppverbot_Anz_06 "Dieses Signal gibt die detaillierte Begründung für ein Stoppverbot vom Getriebesteuergerät an.";
CM_ SG_ 916 GE_Stoppverbot_Anz_07 "Dieses Signal gibt die detaillierte Begründung für ein Stoppverbot vom Getriebesteuergerät an.";
CM_ SG_ 916 GE_Stoppverbot_Anz_Std "Dieses Signal gibt die detaillierte Begründung für ein Stoppverbot vom Getriebesteuergerät an.";
CM_ SG_ 916 GE_Tipschaltempf_verfuegbar "Signalisierung, ob eine Hochschaltempfehlung im Tipmodus verfügbar ist oder nicht.";
CM_ SG_ 916 GE_Wiederstart_Anz_Std "Dieses Signal gibt die detaillierte Begründung für einen Wiederstart vom Getriebesteuergerät an. ";
CM_ SG_ 916 WBA_03_CRC "Für MLB:
'Berechnung siehe Lastenheft 'Kommunikationsabsicherung für FlexRay und CAN''

Ab MQB und MLBevo:
'Berechnung siehe Lastenheft 'End-to-End Kommunikationsabsicherung''

Endwerte siehe Begleitdokument 'S-PDU Kennungsfolgen'";
CM_ SG_ 916 WBA_Blinken "Dieses Bit steuert die Fehlerlampe an oder wird zum Blinken der WBA-Anzeige genutzt - nur falls WBA_Senderkennung = 00 (GSG)
";
CM_ SG_ 916 WBA_eing_Gang_02 "Das Automatikgetriebe gibt den aktuell eingelegten Gang aus.
Besonderheiten:
0x0 = marktabhängig wird auf Ganganzeige zur Fahrstufe komplett verzichtet
0xA = kurzzeitige Unterdrückung der Ganganzeige (z. B. Segeln, Zwischenstellung, etc.)";
CM_ SG_ 916 WBA_Fahrstufe_02 "Bei Automatgetrieben wird in diesem Signal die aktuelle anzuzeigende Fahrstufe ausgegeben.

Die Signalkodierungen 0x9, 0xA und 0xB werden im MSS-R8NF und MQB-A1/B/A2 verwendet.

Die Signalkodierungen 0xC und 0xD werden nur im MQB-A1/B/A2 verwendet.
";
CM_ SG_ 916 WBA_GE_Texte "Fahrerhinweise für das Kombi";
CM_ SG_ 916 WBA_GE_Texte_02 "Fahrerhinweise für das Kombi";
CM_ SG_ 916 WBA_GE_Texte_03 "Launch control functionality stauts (performance strategy and smoke stratgey)";
CM_ SG_ 916 WBA_GE_Warnung_02 "Prioritätswarnungen Getriebe";
CM_ SG_ 916 WBA_GE_Zusatzwarnungen "Prioritaetswarnungen Getriebe an Kombi
Audi MLB Wertebereich 0 bis 3
VW MQB Projekte verwenden nur den Wertebereich 0 bis 2
VW MQB Getriebefehler werden über das Signal  GE_Warnungen_02 gesendet.";
CM_ SG_ 916 WBA_Schaltschema "Bei Automatikgetrieben wird in diesem Signal die aktuelle, eingelegte Fahrstufe (=Wählhebelposition) ausgegeben.";
CM_ SG_ 916 WBA_Segeln_aktiv "Getriebe geht in den Segelbetrieb";
CM_ SG_ 916 WBA_ZielFahrstufe "Zielfahrprogramm (Darstellung), für getipptes S/E/M mit neuem Wählhebel im MQB";

CM_ SG_ 2527679839 WCU_PrctVolWaRem "Restmenge im Tank in Prozent";
CM_ SG_ 2527679839 WCU_StTankWa "Status des Mediums";
CM_ SG_ 2527679839 WCU_VolWaRefill "Maximale Befuellmenge";
CM_ SG_ 2527679839 WCU_VolWaRem "Restmenge im Tank gefiltert";
CM_ SG_ 2527679839 WCU_VolWaRemRaw "Restmenge im Tank ungefiltert";

CM_ SG_ 1361 WFS_Betrieb_Lesespule "Schlüsselkommunikation über die Lesespule";
CM_ SG_ 1361 WFS_ELV_authorisiert "Authorisierung der elektrischen Lenkungsverriegelung an der WFS";
CM_ SG_ 1361 WFS_Fahrerhinweise "Meldungen, Fahrer- und Warnhinweise der Wegfahrsperre";
CM_ SG_ 1361 WFS_ID_Geb_autorisiert "Authorisierung Schluessel (ID-Geber)";
CM_ SG_ 1361 WFS_ID_Geb_autorisiert_in_Kl15 "Authorisierung des Schlüssels im aktiven Klemme-15-Zyklus";
CM_ SG_ 1361 WFS_ID_Geb_steckt "Schluessel (ID-Geber) im Zuendschloss
";
CM_ SG_ 1361 WFS_Klemmenfreigabe "Freigabe von der WFS zum Einschalten der Klemme 15 und Klemme S";
CM_ SG_ 1361 WFS_LF_Aktiv "LF Schluesselkommunikation
";
CM_ SG_ 1361 WFS_LZ "Anforderung aus Lastenheft WFS V
";
CM_ SG_ 1361 WFS_Parken_Status "Schnittstelle zwischen WFS und ZFAS für das Pilotierte Parken um in Richtung ZFAS den Status der WFS im BCM2 zu kommunizieren";
CM_ SG_ 1361 WFS_Safe "Status WFS";
CM_ SG_ 1361 WFS_Schluessel_Fahrberecht "Schlüsselnummer Fahrberechtigung
0 = ungueltig, xxxx = Schluessel-Nr.";
CM_ SG_ 1361 WFS_Schluessel_Ist "Istwert der gelernten Schluessel";
CM_ SG_ 1361 WFS_Schluessel_Soll "Sollwert der zu lernenden Schluessel";

CM_ SG_ 1702 BCM1_SRA_aktiv "Status Scheinwerferreinigungsanlage";
CM_ SG_ 1702 Heckwischer_Anforderung "Das Signal beschreibt die Anforderung an den Signalausgang im BCM2 zur Ansteuerung des Heckwischers.";
CM_ SG_ 1702 Waschen_vorne_aktiv "Status: Waschen vorne aktiv";
CM_ SG_ 1702 Wischer1_Wischgeschwindigkeit "aktuelle, durch Sensorik gemessene Wischgeschwindigkeit";
CM_ SG_ 1702 Wischer_Anzeigetext "Das Signal fordert einen Kombi-Pop-Up mit entsprechenden Texten an";
CM_ SG_ 1702 Wischer_vorne_aktiv "Status: Wischer vorne";
CM_ SG_ 1702 Wischer_vorne_blockiert "Blockade Wischer vorne (z.B. durch Schnee)";
CM_ SG_ 1702 Wischer_vorne_defekt "Fehlerstatus Wischer vorne (Anzeige im Kombi)";
CM_ SG_ 1702 Wischer_vorne_Normal "Wischer Front normal aktiv";
CM_ SG_ 1702 Wischer_vorne_Parklage "Wischer Front in Parklage";
CM_ SG_ 1702 Wischer_vorne_Schnell "Wischer vorne schnell aktiv";
CM_ SG_ 1702 WWSs_01_upd "Update-Bit für die LIN-Botschaft WWSs_01.

Betroffene Signale:

Wischer_vorne_aktiv
Wischer1_Wischgeschwindigkeit";

CM_ SG_ 2527679496 WIV_Russindex_02 "Nur für Diesel, Rußwert, bei Otto Wert = 0";
CM_ SG_ 2527679496 WIV_Russindex_Ueberlauf "Der motorsteuergeräteinterne Zähler für den Russindex ist mindestens einmal übergelaufen. Dieses Bit wird genutzt, um erkennen zu können, daß das Motorsteuergerät aus dem Reset-Zustand hochläuft.";
CM_ SG_ 2527679496 WIV_t_max "Maximales Wartungsintervall für WIV in Monaten";
CM_ SG_ 2527679496 WIV_t_min "Minimales Wartungsintervall für WIV in Monaten";
CM_ SG_ 2527679496 WIV_Verschleissindex_02 "Bei Otto Verbrauch, bei Diesel Verschleiss";
CM_ SG_ 2527679496 WIV_Verschleissindex_Ueberlauf "Der motorsteuergeräteinterne Zähler für den Verschleissindex (Diesel) bzw. Verbrauchsindex (Otto) ist mindestens einmal übergelaufen. Dieses Bit wird genutzt, um erkennen zu können, daß das Motorsteuergerät aus dem Reset-Zustand hochläuft.";
CM_ SG_ 2527679496 WIV_W_max "Maximales Wartungsintervall für WIV in km";
CM_ SG_ 2527679496 WIV_W_min "Minimales Wartungsintervall für WIV in km";

CM_ SG_ 2527679655 MMI_StartupAnimation "Synchronisierung der Startupanimation zwischen MMI und Kombi";
CM_ SG_ 2527679655 ZR_SOC_Weiterfahrt "SOC auf den an der Ladesäule am nächsten geplanten Ladestopp geladen werden soll.";

CM_ SG_ 2463978613 ZFAS_01_BZ "Botschaftszaehler";
CM_ SG_ 2463978613 ZFAS_01_CRC "Ab MQB und MLBevo:
'Berechnung siehe Lastenheft 'End-to-End Kommunikationsabsicherung''

Endwerte siehe Begleitdokument 'S-PDU Kennungsfolgen'";
CM_ SG_ 2463978613 zFAS_Blinker_li "Anforderung seitens zFAS für 'Links blinken'";
CM_ SG_ 2463978613 zFAS_Blinker_re "Anforderung seitens zFAS für 'Rechts blinken'";
CM_ SG_ 2463978613 zFAS_Pilottaster_LED_Farbe_Anf "Farbanforderung seitens zFAS für die Korona um den Fahrtaster.";
CM_ SG_ 2463978613 zFAS_Pilottaster_LED_Modus_Anf "Anforderung seitens zFAS für den Sondermodus „Blinken/Pulsieren“ der Korona um den Fahrtaster.";

CM_ SG_ 1411 BCM_FH_Freigabe "Funktionsfreigabe Fensterheber";
CM_ SG_ 1411 BCM_HSK_Freigabe "Handschuhkastenfreigabe";
CM_ SG_ 1411 BCM_Komfortfkt_Freigabe "globale Freigabe der Komfortfunktion";
CM_ SG_ 1411 BCM_Tankklappensteller_Fehler "Fehler: nicht Funktionalität des Tankklappenstellers";
CM_ SG_ 1411 BCM_Verdeck_Freigabe "Freigabe Verdeckbetrieb
";
CM_ SG_ 1411 DWA_aktiv "Status DWA  aktiv";
CM_ SG_ 1411 FBS_Warn_Schluessel_Batt "Kombi Prio Warnung Schluessel Batterie
'Bitte Schlüsselbatterie wechseln!'";
CM_ SG_ 1411 FFB_CarFinder "Car Finder Funktion (Blinken ohne zu entriegeln)";
CM_ SG_ 1411 FFB_Komfortoeffnen "Komfortoeffnen Funk
";
CM_ SG_ 1411 FFB_Komfortschliessen "Komfortschliessen Funk
";
CM_ SG_ 1411 HBFS_gesafet "HBFS Tuer gesafet.
Im Zustand Safe wird auch das Signal HBFS_verriegelt = 1 gesendet.";
CM_ SG_ 1411 HBFS_verriegelt "Verriegelungsstatus Tür";
CM_ SG_ 1411 HD_Hauptraste "SBL-Schloss (MQB/MLBevo): Drehfalle Heckdeckel
sonst (MQB): Hauptraste Heckdeckel";
CM_ SG_ 1411 HD_Vorraste "SBL_Schloss (MQB/MLBevo): Sperrklinke Heckdeckel
sonst (MQB): Vorraste Heckdeckel";
CM_ SG_ 1411 HFS_gesafet "HFS Tuer gesafet.
Im Zustand Safe wird auch das Signal HFS_verriegelt = 1 gesendet.";
CM_ SG_ 1411 HFS_verriegelt "HFS Tuer verriegelt";
CM_ SG_ 1411 IRUE_aktiv "Status Innenraumüberwachung
";
CM_ SG_ 1411 IRUE_Taster_Fkts_LED "Anforderung Funktions-LED IRUE-Taster (LED wird vom TSG angesteuert)
MQB: Bei Verbau eines einzelnen Taster zur Deaktivierung von IRUE und NGS wird dieses Signal zur Ansteuerung der Funktions-LED gesendet.";
CM_ SG_ 1411 ZV_BT_offen "gespiegeltes Bit BT_Tuer_geoeffnet TSG_BT_1 Botschaft";
CM_ SG_ 1411 ZV_Einzeltuerentriegelung "Einzeltürentriegelung ZV
";
CM_ SG_ 1411 ZV_FT_offen "gespiegeltes Bit FT_Tuer_geoeffnet TSG_FT_1 Botschaft";
CM_ SG_ 1411 ZV_gesafet_extern_ist "Istzustand: Fahrzeug aussen gesafet
";
CM_ SG_ 1411 ZV_gesafet_extern_soll "Sollzustand: Fahrzeug gesafet extern
";
CM_ SG_ 1411 ZV_HBFS_offen "gespiegeltes Bit HBFS_Tuer_geoeffnet TSG_HBFS_1 Botschaft";
CM_ SG_ 1411 ZV_HD_offen "Status Heckdeckel
";
CM_ SG_ 1411 ZV_Heckeinzelentriegelung "Heckdeckeleinzelentriegelung";
CM_ SG_ 1411 ZV_HFS_offen "gespiegeltes Bit HFS_Tuer_geoeffnet TSG_HFS_1 Botschaft";
CM_ SG_ 1411 ZV_HS_offen "Status Heckscheibe
";
CM_ SG_ 1411 ZV_ist_Zustand_verfuegbar "Verfügbarkeit IST-Zustand ZV

";
CM_ SG_ 1411 ZV_Oeffnungsmodus "Konfigurierter Oeffnungsmodus fuer ZV:
0 = globale Oeffnung (alle Tueren)
1 = ZV mit Einzeltuerentriegelung (FFB - nur Fahrertuer, Kessy - nur bediente Tuer)
2 = ZV individuell selektive Oeffnung (FFB - Fahrerseite, Kessy - bediente Tuer + Fahrertuer)";
CM_ SG_ 1411 ZV_Rollo_auf "Komfortöffnen des Dachrollos";
CM_ SG_ 1411 ZV_Rollo_zu "Komfortschließen des Dachrollos";
CM_ SG_ 1411 ZV_SAD_auf "Komfortöffnen des Schiebeausstelldaches";
CM_ SG_ 1411 ZV_SAD_zu "Komfortschließen des Schiebeausstelldaches";
CM_ SG_ 1411 ZV_SafeFunktion_aktiv "Statusübermittlung ob die Safe Funktion im Fzg. aktiv ist. Das Kombi benötigt das Signal, um den Text Safelock aktiv anzuzeigen. ";
CM_ SG_ 1411 ZV_Schluessel_Zugang "aktuelle Funkschlüsselnummer";
CM_ SG_ 1411 ZV_Tankklappe_offen "Öffnungsstatus der Tankklappe";
CM_ SG_ 1411 ZV_verriegelt_extern_ist "Istzustand: Verriegelung Fahrzeug aussen
";
CM_ SG_ 1411 ZV_verriegelt_extern_soll "Sollzustand: Verriegelung Fahrzeug aussen
";
CM_ SG_ 1411 ZV_verriegelt_intern_ist "Istzustand: Verriegelung Fahrzeug innen
";
CM_ SG_ 1411 ZV_verriegelt_intern_soll "Sollzustand: Verriegelung Fahrzeug innen
";
CM_ SG_ 1411 ZV_verriegelt_soll "Fahrzeug Gesamtverriegelungsstatus Sollzustand für Ladestecker- und Ladeklappenverriegelung. ";
BA_DEF_REL_ BU_SG_REL_  "GenSigTimeoutTime" INT 0 65535;
BA_DEF_ BO_  "DiagRequest" ENUM "No", "Yes";
BA_DEF_ BO_  "DiagResponse" ENUM "No", "Yes";
BA_DEF_ BO_  "DiagState" ENUM "No", "Yes";
BA_DEF_ BO_  "GenMsgChkConstant" HEX 0 4095;
BA_DEF_ BO_  "GenMsgCycleTime" INT 0 65535;
BA_DEF_ BO_  "GenMsgCycleTimeFast" INT 0 65535;
BA_DEF_ BO_  "GenMsgDelayTime" INT 0 100000;
BA_DEF_ BO_  "GenMsgILSupport" ENUM "No", "Yes";
BA_DEF_ BO_  "GenMsgNrOfRepetition" INT 0 100;
BA_DEF_ BO_  "GenMsgPDUConstants" STRING;
BA_DEF_ BO_  "GenMsgSendType" ENUM "Cyclic", "not_used", "not_used", "not_used", "not_used", "not_used", "not_used", "IfActive", "NoMsgSendType";
BA_DEF_ BO_  "GenMsgStartDelayTime" INT 0 100000;
BA_DEF_ BO_  "NmMessage" ENUM "No", "Yes";
BA_DEF_ BO_  "NmhMessage" ENUM "No", "Yes";
BA_DEF_ BO_  "MsgType" ENUM "Application", "NM ", "NMH", "TP2.0", "ISO-TP ", "BAP", "EID", "KS", "XCP_PRE_CONFIGURED", "XCP_RUNTIME_CONFIGURED";
BA_DEF_ BO_  "VAGTP20_API" HEX 0 255;
BA_DEF_ BO_  "VAGTP20_DynConnection" ENUM "No", "Yes";
BA_DEF_ BO_  "VAGTP20_DynSetup" ENUM "No", "Yes";
BA_DEF_ BO_  "VAGTP20_StatConnection" ENUM "No", "Yes";
BA_DEF_ SG_  "GenSigActiveRepetitions" INT -2147483648 2147483647;
BA_DEF_ SG_  "GenSigInactiveValue" INT -2147483648 2147483647;
BA_DEF_ SG_  "GenSigSendType" ENUM "Cyclic", "OnWrite", "OnWriteWithRepetition", "OnChange", "OnChangeWithRepetition", "IfActive", "IfActiveWithRepetition", "NoSigSendType", "OnChangeAndIfActive", "OnChangeAndIfActiveWithRepetition";
BA_DEF_ SG_  "GenSigStartValue" INT -2147483648 2147483647;
BA_DEF_ SG_  "NWM-WakeupAllowed" ENUM "No", "Yes";
BA_DEF_ SG_  "GenSigFuncType" ENUM "NoFunction", "MsgCounter", "CRC-8", "XOR", "XOR-2", "DatedBit", "SW-Kl15", "CHK", "Constant", "Protocol", "CRC-8-SAE_J1850", "CRC-32", "DataLength", "DataID", "MsgCounter16", "SOK-Signatur", "Cluster";
BA_DEF_ SG_  "GenSigSwitchedByIgnition" ENUM "No", "Yes";
BA_DEF_ SG_  "Fehlerwert" HEX 0 2147483647;
BA_DEF_ SG_  "GenSigMissingSourceValue" HEX 0 2147483647;
BA_DEF_DEF_REL_  "GenSigTimeoutTime" 0;
BA_DEF_DEF_  "DiagRequest" "No";
BA_DEF_DEF_  "DiagResponse" "No";
BA_DEF_DEF_  "DiagState" "No";
BA_DEF_DEF_  "GenMsgChkConstant" 0;
BA_DEF_DEF_  "GenMsgCycleTime" 0;
BA_DEF_DEF_  "GenMsgCycleTimeFast" 0;
BA_DEF_DEF_  "GenMsgDelayTime" 0;
BA_DEF_DEF_  "GenMsgILSupport" "No";
BA_DEF_DEF_  "GenMsgNrOfRepetition" 0;
BA_DEF_DEF_  "GenMsgPDUConstants" "";
BA_DEF_DEF_  "GenMsgSendType" "NoMsgSendType";
BA_DEF_DEF_  "GenMsgStartDelayTime" 0;
BA_DEF_DEF_  "NmMessage" "No";
BA_DEF_DEF_  "NmhMessage" "No";
BA_DEF_DEF_  "MsgType" "Application";
BA_DEF_DEF_  "VAGTP20_API" 0;
BA_DEF_DEF_  "VAGTP20_DynConnection" "No";
BA_DEF_DEF_  "VAGTP20_DynSetup" "No";
BA_DEF_DEF_  "VAGTP20_StatConnection" "No";
BA_DEF_DEF_  "GenSigActiveRepetitions" 0;
BA_DEF_DEF_  "GenSigInactiveValue" 0;
BA_DEF_DEF_  "GenSigSendType" "NoSigSendType";
BA_DEF_DEF_  "GenSigStartValue" 0;
BA_DEF_DEF_  "NWM-WakeupAllowed" "No";
BA_DEF_DEF_  "GenSigFuncType" "NoFunction";
BA_DEF_DEF_  "GenSigSwitchedByIgnition" "Yes";
BA_DEF_DEF_  "Fehlerwert" 0;
BA_DEF_DEF_  "GenSigMissingSourceValue" 0;
BA_ "GenMsgCycleTime" BO_ 974 500;
BA_ "GenMsgDelayTime" BO_ 974 100;
BA_ "GenMsgILSupport" BO_ 974 1;
BA_ "GenMsgSendType" BO_ 974 0;
BA_ "GenMsgCycleTime" BO_ 288 100;
BA_ "GenMsgILSupport" BO_ 288 1;
BA_ "GenMsgPDUConstants" BO_ 288 "0xc4,0xe2,0x4f,0xe4,0xf8,0x2f,0x56,0x81,0x9f,0xe5,0x83,0x44,0x05,0x3f,0x97,0xdf";
BA_ "GenMsgSendType" BO_ 288 0;
BA_ "GenMsgCycleTime" BO_ 798 40;
BA_ "GenMsgILSupport" BO_ 798 1;
BA_ "GenMsgPDUConstants" BO_ 798 "0x78,0x68,0x3a,0x31,0x16,0x08,0x4f,0xde,0xf7,0x35,0x19,0xe6,0x28,0x2f,0x59,0x82";
BA_ "GenMsgSendType" BO_ 798 0;
BA_ "GenMsgCycleTime" BO_ 563 40;
BA_ "GenMsgILSupport" BO_ 563 1;
BA_ "GenMsgSendType" BO_ 563 0;
BA_ "GenMsgCycleTime" BO_ 1718 1000;
BA_ "GenMsgILSupport" BO_ 1718 1;
BA_ "GenMsgSendType" BO_ 1718 0;
BA_ "GenMsgCycleTime" BO_ 618 1000;
BA_ "GenMsgDelayTime" BO_ 618 100;
BA_ "GenMsgILSupport" BO_ 618 1;
BA_ "GenMsgSendType" BO_ 618 0;
BA_ "GenMsgCycleTime" BO_ 2463978633 100;
BA_ "GenMsgDelayTime" BO_ 2463978633 50;
BA_ "GenMsgILSupport" BO_ 2463978633 1;
BA_ "GenMsgPDUConstants" BO_ 2463978633 "0x81,0xad,0x54,0x1d,0x28,0xac,0x6c,0x8e,0xd4,0x6e,0xeb,0x58,0x4a,0x71,0x5a,0x3b";
BA_ "GenMsgSendType" BO_ 2463978633 0;
BA_ "GenMsgCycleTime" BO_ 995 100;
BA_ "GenMsgCycleTimeFast" BO_ 995 50;
BA_ "GenMsgDelayTime" BO_ 995 50;
BA_ "GenMsgILSupport" BO_ 995 1;
BA_ "GenMsgNrOfRepetition" BO_ 995 5;
BA_ "GenMsgPDUConstants" BO_ 995 "0xad,0x1d,0xac,0x8e,0x6e,0x58,0x71,0x3b,0xce,0xc6,0x27,0x4f,0x06,0xca,0x65,0x84";
BA_ "GenMsgSendType" BO_ 995 0;
BA_ "GenMsgCycleTime" BO_ 1716 200;
BA_ "GenMsgILSupport" BO_ 1716 1;
BA_ "GenMsgSendType" BO_ 1716 0;
BA_ "GenMsgCycleTime" BO_ 385 200;
BA_ "GenMsgDelayTime" BO_ 385 40;
BA_ "GenMsgILSupport" BO_ 385 1;
BA_ "GenMsgSendType" BO_ 385 0;
BA_ "GenMsgCycleTime" BO_ 668 200;
BA_ "GenMsgDelayTime" BO_ 668 40;
BA_ "GenMsgILSupport" BO_ 668 1;
BA_ "GenMsgSendType" BO_ 668 0;
BA_ "GenMsgCycleTime" BO_ 2463978672 200;
BA_ "GenMsgDelayTime" BO_ 2463978672 40;
BA_ "GenMsgILSupport" BO_ 2463978672 1;
BA_ "GenMsgSendType" BO_ 2463978672 0;
BA_ "GenMsgChkConstant" BO_ 181 228;
BA_ "GenMsgCycleTime" BO_ 181 10;
BA_ "GenMsgILSupport" BO_ 181 1;
BA_ "GenMsgPDUConstants" BO_ 181 "0xe4,0xe4,0xe4,0xe4,0xe4,0xe4,0xe4,0xe4,0xe4,0xe4,0xe4,0xe4,0xe4,0xe4,0xe4,0xe4";
BA_ "GenMsgSendType" BO_ 181 0;
BA_ "GenMsgCycleTime" BO_ 2589283476 1000;
BA_ "GenMsgDelayTime" BO_ 2589283476 100;
BA_ "GenMsgILSupport" BO_ 2589283476 1;
BA_ "GenMsgSendType" BO_ 2589283476 0;
BA_ "GenMsgCycleTime" BO_ 916 160;
BA_ "GenMsgDelayTime" BO_ 916 10;
BA_ "GenMsgILSupport" BO_ 916 1;
BA_ "GenMsgPDUConstants" BO_ 916 "0x47,0x94,0x92,0x6a,0x67,0xb5,0x0d,0x38,0xe3,0x8a,0x5d,0xb4,0x54,0xab,0xae,0x27";
BA_ "GenMsgSendType" BO_ 916 0;
BA_ "GenMsgCycleTime" BO_ 2527679839 500;
BA_ "GenMsgDelayTime" BO_ 2527679839 200;
BA_ "GenMsgILSupport" BO_ 2527679839 1;
BA_ "GenMsgSendType" BO_ 2527679839 0;
BA_ "GenMsgCycleTime" BO_ 1361 200;
BA_ "GenMsgDelayTime" BO_ 1361 50;
BA_ "GenMsgILSupport" BO_ 1361 1;
BA_ "GenMsgSendType" BO_ 1361 0;
BA_ "GenMsgCycleTime" BO_ 1702 500;
BA_ "GenMsgCycleTimeFast" BO_ 1702 100;
BA_ "GenMsgDelayTime" BO_ 1702 50;
BA_ "GenMsgILSupport" BO_ 1702 1;
BA_ "GenMsgNrOfRepetition" BO_ 1702 3;
BA_ "GenMsgSendType" BO_ 1702 0;
BA_ "GenMsgCycleTime" BO_ 2527679496 320;
BA_ "GenMsgILSupport" BO_ 2527679496 1;
BA_ "GenMsgSendType" BO_ 2527679496 0;
BA_ "MsgType" BO_ 2617040384 8;
BA_ "MsgType" BO_ 2617040385 9;
BA_ "MsgType" BO_ 2617026048 6;
BA_ "MsgType" BO_ 2617026049 6;
BA_ "MsgType" BO_ 2617155072 6;
BA_ "MsgType" BO_ 2617155073 6;
BA_ "GenMsgCycleTime" BO_ 2527679655 1000;
BA_ "GenMsgDelayTime" BO_ 2527679655 50;
BA_ "GenMsgILSupport" BO_ 2527679655 1;
BA_ "GenMsgSendType" BO_ 2527679655 0;
BA_ "GenMsgCycleTime" BO_ 2463978613 320;
BA_ "GenMsgCycleTimeFast" BO_ 2463978613 80;
BA_ "GenMsgDelayTime" BO_ 2463978613 80;
BA_ "GenMsgILSupport" BO_ 2463978613 1;
BA_ "GenMsgPDUConstants" BO_ 2463978613 "0x91,0x3a,0x38,0x23,0x8e,0x5b,0xa6,0x6f,0xdf,0x3b,0xc2,0x12,0x0e,0x4b,0x4f,0xb5";
BA_ "GenMsgSendType" BO_ 2463978613 0;
BA_ "GenMsgCycleTime" BO_ 1411 200;
BA_ "GenMsgCycleTimeFast" BO_ 1411 50;
BA_ "GenMsgDelayTime" BO_ 1411 50;
BA_ "GenMsgILSupport" BO_ 1411 1;
BA_ "GenMsgNrOfRepetition" BO_ 1411 5;
BA_ "GenMsgSendType" BO_ 1411 0;
BA_ "GenSigSendType" SG_ 974 ASW_Warnung_aktiv_HFS 0;
BA_ "GenSigSwitchedByIgnition" SG_ 974 ASW_Warnung_aktiv_HFS 0;
BA_ "GenSigSendType" SG_ 974 HFS_FH_Bew_hoch 0;
BA_ "GenSigSwitchedByIgnition" SG_ 974 HFS_FH_Bew_hoch 0;
BA_ "GenSigSendType" SG_ 974 HFS_FH_Bew_tief 0;
BA_ "GenSigSwitchedByIgnition" SG_ 974 HFS_FH_Bew_tief 0;
BA_ "GenSigSendType" SG_ 974 HFS_FH_Block 0;
BA_ "GenSigSwitchedByIgnition" SG_ 974 HFS_FH_Block 0;
BA_ "GenSigSendType" SG_ 974 HFS_FH_Fang 0;
BA_ "GenSigSwitchedByIgnition" SG_ 974 HFS_FH_Fang 0;
BA_ "GenSigSendType" SG_ 974 HFS_FH_normiert 0;
BA_ "GenSigSwitchedByIgnition" SG_ 974 HFS_FH_normiert 0;
BA_ "GenSigSendType" SG_ 974 HFS_FH_Oeffnung 3;
BA_ "GenSigSwitchedByIgnition" SG_ 974 HFS_FH_Oeffnung 0;
BA_ "GenSigSendType" SG_ 974 HFS_FH_S_AutoHoch 0;
BA_ "GenSigSwitchedByIgnition" SG_ 974 HFS_FH_S_AutoHoch 0;
BA_ "GenSigSendType" SG_ 974 HFS_FH_S_AutoTief 0;
BA_ "GenSigSwitchedByIgnition" SG_ 974 HFS_FH_S_AutoTief 0;
BA_ "GenSigSendType" SG_ 974 HFS_FH_S_HBFS_AutoHoch 0;
BA_ "GenSigSwitchedByIgnition" SG_ 974 HFS_FH_S_HBFS_AutoHoch 0;
BA_ "GenSigSendType" SG_ 974 HFS_FH_S_HBFS_AutoTief 0;
BA_ "GenSigSwitchedByIgnition" SG_ 974 HFS_FH_S_HBFS_AutoTief 0;
BA_ "GenSigSendType" SG_ 974 HFS_FH_S_HBFS_ManHoch 0;
BA_ "GenSigSwitchedByIgnition" SG_ 974 HFS_FH_S_HBFS_ManHoch 0;
BA_ "GenSigSendType" SG_ 974 HFS_FH_S_HBFS_ManTief 0;
BA_ "GenSigSwitchedByIgnition" SG_ 974 HFS_FH_S_HBFS_ManTief 0;
BA_ "GenSigSendType" SG_ 974 HFS_FH_S_ManHoch 0;
BA_ "GenSigSwitchedByIgnition" SG_ 974 HFS_FH_S_ManHoch 0;
BA_ "GenSigSendType" SG_ 974 HFS_FH_S_ManTief 0;
BA_ "GenSigSwitchedByIgnition" SG_ 974 HFS_FH_S_ManTief 0;
BA_ "GenSigSendType" SG_ 974 HFS_FH_Thermo 0;
BA_ "GenSigSwitchedByIgnition" SG_ 974 HFS_FH_Thermo 0;
BA_ "GenSigSendType" SG_ 974 HFS_gesafet 0;
BA_ "GenSigSwitchedByIgnition" SG_ 974 HFS_gesafet 0;
BA_ "GenSigSendType" SG_ 974 HFS_Heckrollotaster_betaetigt 0;
BA_ "GenSigSwitchedByIgnition" SG_ 974 HFS_Heckrollotaster_betaetigt 0;
BA_ "GenSigSendType" SG_ 974 HFS_Lock_Taster 0;
BA_ "GenSigSwitchedByIgnition" SG_ 974 HFS_Lock_Taster 0;
BA_ "GenSigSendType" SG_ 974 HFS_Lock_Taster_inv 0;
BA_ "GenSigSwitchedByIgnition" SG_ 974 HFS_Lock_Taster_inv 0;
BA_ "GenSigSendType" SG_ 974 HFS_MRollo_Schalter 0;
BA_ "GenSigStartValue" SG_ 974 HFS_MRollo_Schalter 6;
BA_ "GenSigSwitchedByIgnition" SG_ 974 HFS_MRollo_Schalter 0;
BA_ "Fehlerwert" SG_ 974 HFS_MRollo_Schalter 7;
BA_ "GenSigSendType" SG_ 974 HFS_Oben_Block_erw 0;
BA_ "GenSigSwitchedByIgnition" SG_ 974 HFS_Oben_Block_erw 0;
BA_ "GenSigSendType" SG_ 974 HFS_SAD_Schalter 0;
BA_ "GenSigStartValue" SG_ 974 HFS_SAD_Schalter 14;
BA_ "GenSigSwitchedByIgnition" SG_ 974 HFS_SAD_Schalter 0;
BA_ "Fehlerwert" SG_ 974 HFS_SAD_Schalter 15;
BA_ "GenSigSendType" SG_ 974 HFS_Seitenrollo_hoch 0;
BA_ "GenSigSwitchedByIgnition" SG_ 974 HFS_Seitenrollo_hoch 0;
BA_ "GenSigSendType" SG_ 974 HFS_Seitenrollo_tief 0;
BA_ "GenSigSwitchedByIgnition" SG_ 974 HFS_Seitenrollo_tief 0;
BA_ "GenSigSendType" SG_ 974 HFS_Sperrklinke 0;
BA_ "GenSigSwitchedByIgnition" SG_ 974 HFS_Sperrklinke 0;
BA_ "GenSigSendType" SG_ 974 HFS_Status_eTAG 0;
BA_ "GenSigSwitchedByIgnition" SG_ 974 HFS_Status_eTAG 0;
BA_ "Fehlerwert" SG_ 974 HFS_Status_eTAG 3;
BA_ "GenSigSendType" SG_ 974 HFS_Status_KiSi 0;
BA_ "GenSigSwitchedByIgnition" SG_ 974 HFS_Status_KiSi 0;
BA_ "GenSigSendType" SG_ 974 HFS_TAG_betaetigt 0;
BA_ "GenSigSwitchedByIgnition" SG_ 974 HFS_TAG_betaetigt 0;
BA_ "GenSigSendType" SG_ 974 HFS_TCR_Mode_aktiv 0;
BA_ "GenSigSwitchedByIgnition" SG_ 974 HFS_TCR_Mode_aktiv 0;
BA_ "GenSigSendType" SG_ 974 HFS_TIG_betaetigt 0;
BA_ "GenSigSwitchedByIgnition" SG_ 974 HFS_TIG_betaetigt 0;
BA_ "GenSigSendType" SG_ 974 HFS_Tuer_geoeffnet 3;
BA_ "GenSigSwitchedByIgnition" SG_ 974 HFS_Tuer_geoeffnet 0;
BA_ "GenSigSendType" SG_ 974 HFS_Tuer_Status 0;
BA_ "GenSigSwitchedByIgnition" SG_ 974 HFS_Tuer_Status 0;
BA_ "Fehlerwert" SG_ 974 HFS_Tuer_Status 3;
BA_ "GenSigSendType" SG_ 974 HFS_Tuer_Status_QBit 0;
BA_ "GenSigSwitchedByIgnition" SG_ 974 HFS_Tuer_Status_QBit 0;
BA_ "GenSigSendType" SG_ 974 HFS_Tueroeffnen_Warnung 3;
BA_ "GenSigSwitchedByIgnition" SG_ 974 HFS_Tueroeffnen_Warnung 0;
BA_ "GenSigSendType" SG_ 974 HFS_Tuerschloss_defekt 3;
BA_ "GenSigSwitchedByIgnition" SG_ 974 HFS_Tuerschloss_defekt 0;
BA_ "GenSigSendType" SG_ 974 HFS_UEKB_aktiviert 0;
BA_ "GenSigSwitchedByIgnition" SG_ 974 HFS_UEKB_aktiviert 0;
BA_ "GenSigSendType" SG_ 974 HFS_Unlock_Taster 0;
BA_ "GenSigSwitchedByIgnition" SG_ 974 HFS_Unlock_Taster 0;
BA_ "GenSigSendType" SG_ 974 HFS_Unten_Block_erw 0;
BA_ "GenSigSwitchedByIgnition" SG_ 974 HFS_Unten_Block_erw 0;
BA_ "GenSigSendType" SG_ 974 HFS_verriegelt 0;
BA_ "GenSigSwitchedByIgnition" SG_ 974 HFS_verriegelt 0;
BA_ "GenSigSendType" SG_ 974 HFS_Zuziehhilfe_aktiv 0;
BA_ "GenSigSwitchedByIgnition" SG_ 974 HFS_Zuziehhilfe_aktiv 0;
BA_ "GenSigSendType" SG_ 974 MTHFS_M_Taste 0;
BA_ "GenSigSwitchedByIgnition" SG_ 974 MTHFS_M_Taste 0;
BA_ "GenSigSendType" SG_ 974 MTHFS_Pos1 0;
BA_ "GenSigSwitchedByIgnition" SG_ 974 MTHFS_Pos1 0;
BA_ "GenSigSendType" SG_ 974 MTHFS_Pos2 0;
BA_ "GenSigSwitchedByIgnition" SG_ 974 MTHFS_Pos2 0;
BA_ "GenSigSendType" SG_ 974 MTHFS_Pos3 0;
BA_ "GenSigSwitchedByIgnition" SG_ 974 MTHFS_Pos3 0;
BA_ "GenSigSendType" SG_ 974 SSR_HFS_Pos_Unten 0;
BA_ "GenSigSwitchedByIgnition" SG_ 974 SSR_HFS_Pos_Unten 0;
BA_ "GenSigSendType" SG_ 288 TSK_06_BZ 0;
BA_ "GenSigFuncType" SG_ 288 TSK_06_BZ 1;
BA_ "GenSigSwitchedByIgnition" SG_ 288 TSK_06_BZ 0;
BA_ "GenSigSendType" SG_ 288 TSK_06_CRC 0;
BA_ "GenSigFuncType" SG_ 288 TSK_06_CRC 2;
BA_ "GenSigSwitchedByIgnition" SG_ 288 TSK_06_CRC 0;
BA_ "GenSigSendType" SG_ 288 TSK_ax_Getriebe_02 0;
BA_ "GenSigStartValue" SG_ 288 TSK_ax_Getriebe_02 511;
BA_ "GenSigSwitchedByIgnition" SG_ 288 TSK_ax_Getriebe_02 0;
BA_ "GenSigSendType" SG_ 288 TSK_Freig_Verzoeg_Anf 0;
BA_ "GenSigSwitchedByIgnition" SG_ 288 TSK_Freig_Verzoeg_Anf 0;
BA_ "GenSigSendType" SG_ 288 TSK_Freig_WU 0;
BA_ "GenSigSwitchedByIgnition" SG_ 288 TSK_Freig_WU 0;
BA_ "GenSigSendType" SG_ 288 TSK_Hauptschalter_GRA_ACC 0;
BA_ "GenSigSwitchedByIgnition" SG_ 288 TSK_Hauptschalter_GRA_ACC 0;
BA_ "Fehlerwert" SG_ 288 TSK_Hauptschalter_GRA_ACC 3;
BA_ "GenSigSendType" SG_ 288 TSK_Limiter_ausgewaehlt 0;
BA_ "GenSigSwitchedByIgnition" SG_ 288 TSK_Limiter_ausgewaehlt 0;
BA_ "GenSigSendType" SG_ 288 TSK_Radbremsmom 0;
BA_ "GenSigSwitchedByIgnition" SG_ 288 TSK_Radbremsmom 0;
BA_ "GenSigSendType" SG_ 288 TSK_SRBM_Anf_ASIL 0;
BA_ "GenSigSwitchedByIgnition" SG_ 288 TSK_SRBM_Anf_ASIL 0;
BA_ "GenSigSendType" SG_ 288 TSK_Standby_Anf_ESP 0;
BA_ "GenSigSwitchedByIgnition" SG_ 288 TSK_Standby_Anf_ESP 0;
BA_ "GenSigSendType" SG_ 288 TSK_Status 0;
BA_ "GenSigStartValue" SG_ 288 TSK_Status 1;
BA_ "GenSigSwitchedByIgnition" SG_ 288 TSK_Status 0;
BA_ "GenSigSendType" SG_ 288 TSK_v_Begrenzung_aktiv 0;
BA_ "GenSigSwitchedByIgnition" SG_ 288 TSK_v_Begrenzung_aktiv 0;
BA_ "GenSigSendType" SG_ 288 TSK_Wunsch_Uebersetz 0;
BA_ "GenSigSwitchedByIgnition" SG_ 288 TSK_Wunsch_Uebersetz 0;
BA_ "GenSigSendType" SG_ 288 TSK_zul_Regelabw 0;
BA_ "GenSigSwitchedByIgnition" SG_ 288 TSK_zul_Regelabw 0;
BA_ "GenSigSendType" SG_ 288 TSK_Zwangszusch_ESP 0;
BA_ "GenSigSwitchedByIgnition" SG_ 288 TSK_Zwangszusch_ESP 0;
BA_ "GenSigSendType" SG_ 798 MO_Motorlaufwarnung 0;
BA_ "GenSigSwitchedByIgnition" SG_ 798 MO_Motorlaufwarnung 0;
BA_ "GenSigSendType" SG_ 798 MO_Verlassenswarnung 0;
BA_ "GenSigSwitchedByIgnition" SG_ 798 MO_Verlassenswarnung 0;
BA_ "GenSigSendType" SG_ 798 TSK_07_BZ 0;
BA_ "GenSigFuncType" SG_ 798 TSK_07_BZ 1;
BA_ "GenSigSwitchedByIgnition" SG_ 798 TSK_07_BZ 0;
BA_ "GenSigSendType" SG_ 798 TSK_07_CRC 0;
BA_ "GenSigFuncType" SG_ 798 TSK_07_CRC 2;
BA_ "GenSigSwitchedByIgnition" SG_ 798 TSK_07_CRC 0;
BA_ "GenSigSendType" SG_ 798 TSK_Akustik 0;
BA_ "GenSigSwitchedByIgnition" SG_ 798 TSK_Akustik 0;
BA_ "GenSigSendType" SG_ 798 TSK_Fahrzeugstatus_GRA 0;
BA_ "GenSigSwitchedByIgnition" SG_ 798 TSK_Fahrzeugstatus_GRA 0;
BA_ "GenSigSendType" SG_ 798 TSK_Fahrzeugstatus_Limiter 0;
BA_ "GenSigSwitchedByIgnition" SG_ 798 TSK_Fahrzeugstatus_Limiter 0;
BA_ "GenSigSendType" SG_ 798 TSK_Fahrzeugstatus_praed_Fkt 0;
BA_ "GenSigSwitchedByIgnition" SG_ 798 TSK_Fahrzeugstatus_praed_Fkt 0;
BA_ "GenSigSendType" SG_ 798 TSK_Limiter_Anzeige 0;
BA_ "GenSigSwitchedByIgnition" SG_ 798 TSK_Limiter_Anzeige 0;
BA_ "GenSigSendType" SG_ 798 TSK_Limiter_Fahrerinfo 0;
BA_ "GenSigSwitchedByIgnition" SG_ 798 TSK_Limiter_Fahrerinfo 0;
BA_ "GenSigSendType" SG_ 798 TSK_naechstes_Event 0;
BA_ "GenSigSwitchedByIgnition" SG_ 798 TSK_naechstes_Event 0;
BA_ "GenSigSendType" SG_ 798 TSK_naechstes_Event_Einheit 0;
BA_ "GenSigSwitchedByIgnition" SG_ 798 TSK_naechstes_Event_Einheit 0;
BA_ "GenSigSendType" SG_ 798 TSK_praediktiver_Automode 0;
BA_ "GenSigSwitchedByIgnition" SG_ 798 TSK_praediktiver_Automode 0;
BA_ "GenSigSendType" SG_ 798 TSK_praediktiver_Hinweis 0;
BA_ "GenSigSwitchedByIgnition" SG_ 798 TSK_praediktiver_Hinweis 0;
BA_ "GenSigSendType" SG_ 798 TSK_Status_Anzeige 0;
BA_ "GenSigStartValue" SG_ 798 TSK_Status_Anzeige 1;
BA_ "GenSigSwitchedByIgnition" SG_ 798 TSK_Status_Anzeige 0;
BA_ "GenSigSendType" SG_ 798 TSK_Texte 0;
BA_ "GenSigSwitchedByIgnition" SG_ 798 TSK_Texte 0;
BA_ "GenSigSendType" SG_ 798 TSK_Texte_Primaeranz 0;
BA_ "GenSigSwitchedByIgnition" SG_ 798 TSK_Texte_Primaeranz 0;
BA_ "GenSigSendType" SG_ 798 TSK_Wunschgeschw 0;
BA_ "GenSigSwitchedByIgnition" SG_ 798 TSK_Wunschgeschw 0;
BA_ "GenSigSendType" SG_ 563 TSK_praed_Wunschgeschw 0;
BA_ "GenSigStartValue" SG_ 563 TSK_praed_Wunschgeschw 1022;
BA_ "GenSigSwitchedByIgnition" SG_ 563 TSK_praed_Wunschgeschw 0;
BA_ "GenSigSendType" SG_ 1718 UH_DLS 0;
BA_ "GenSigSwitchedByIgnition" SG_ 1718 UH_DLS 0;
BA_ "GenSigSendType" SG_ 1718 UH_Jahr 0;
BA_ "GenSigSwitchedByIgnition" SG_ 1718 UH_Jahr 0;
BA_ "GenSigSendType" SG_ 1718 UH_Minute 0;
BA_ "GenSigSwitchedByIgnition" SG_ 1718 UH_Minute 0;
BA_ "GenSigSendType" SG_ 1718 UH_Monat 0;
BA_ "GenSigSwitchedByIgnition" SG_ 1718 UH_Monat 0;
BA_ "Fehlerwert" SG_ 1718 UH_Monat 15;
BA_ "GenSigSendType" SG_ 1718 UH_Sekunde 0;
BA_ "GenSigSwitchedByIgnition" SG_ 1718 UH_Sekunde 0;
BA_ "GenSigSendType" SG_ 1718 UH_Stunde 0;
BA_ "GenSigSwitchedByIgnition" SG_ 1718 UH_Stunde 0;
BA_ "GenSigSendType" SG_ 1718 UH_Tag 0;
BA_ "GenSigSwitchedByIgnition" SG_ 1718 UH_Tag 0;
BA_ "GenSigSendType" SG_ 1718 UH_Typ 0;
BA_ "GenSigFuncType" SG_ 1718 UH_Typ 8;
BA_ "GenSigSwitchedByIgnition" SG_ 1718 UH_Typ 0;
BA_ "GenSigSendType" SG_ 618 USS_Fahrer_Texte 3;
BA_ "GenSigSwitchedByIgnition" SG_ 618 USS_Fahrer_Texte 0;
BA_ "GenSigSendType" SG_ 618 USS_Fahrzeit_seit_Pause 0;
BA_ "GenSigStartValue" SG_ 618 USS_Fahrzeit_seit_Pause 1022;
BA_ "GenSigSwitchedByIgnition" SG_ 618 USS_Fahrzeit_seit_Pause 0;
BA_ "Fehlerwert" SG_ 618 USS_Fahrzeit_seit_Pause 1023;
BA_ "GenSigSendType" SG_ 618 USS_MKE_Index 0;
BA_ "GenSigStartValue" SG_ 618 USS_MKE_Index 126;
BA_ "GenSigSwitchedByIgnition" SG_ 618 USS_MKE_Index 0;
BA_ "Fehlerwert" SG_ 618 USS_MKE_Index 127;
BA_ "GenSigSendType" SG_ 618 USS_MKE_Index_Anstieg 0;
BA_ "GenSigStartValue" SG_ 618 USS_MKE_Index_Anstieg 5;
BA_ "GenSigSwitchedByIgnition" SG_ 618 USS_MKE_Index_Anstieg 0;
BA_ "GenSigSendType" SG_ 618 USS_MKE_Index_Quelle_Biometrisch 0;
BA_ "GenSigSwitchedByIgnition" SG_ 618 USS_MKE_Index_Quelle_Biometrisch 0;
BA_ "GenSigSendType" SG_ 618 USS_MKE_Index_Quelle_FBK 0;
BA_ "GenSigSwitchedByIgnition" SG_ 618 USS_MKE_Index_Quelle_FBK 0;
BA_ "GenSigSendType" SG_ 618 USS_MKE_Index_Quelle_LWS_Basis 0;
BA_ "GenSigSwitchedByIgnition" SG_ 618 USS_MKE_Index_Quelle_LWS_Basis 0;
BA_ "GenSigSendType" SG_ 618 USS_MKE_Index_Quelle_LWS_Plus 0;
BA_ "GenSigSwitchedByIgnition" SG_ 618 USS_MKE_Index_Quelle_LWS_Plus 0;
BA_ "GenSigSendType" SG_ 618 USS_MKE_Index_Quelle_MFK 0;
BA_ "GenSigSwitchedByIgnition" SG_ 618 USS_MKE_Index_Quelle_MFK 0;
BA_ "GenSigSendType" SG_ 618 USS_MKE_Risiko 0;
BA_ "GenSigStartValue" SG_ 618 USS_MKE_Risiko 3;
BA_ "GenSigSwitchedByIgnition" SG_ 618 USS_MKE_Risiko 0;
BA_ "GenSigSendType" SG_ 2463978633 VAS_L_01_BZ 0;
BA_ "GenSigFuncType" SG_ 2463978633 VAS_L_01_BZ 1;
BA_ "GenSigSwitchedByIgnition" SG_ 2463978633 VAS_L_01_BZ 0;
BA_ "GenSigSendType" SG_ 2463978633 VAS_L_01_CRC 0;
BA_ "GenSigFuncType" SG_ 2463978633 VAS_L_01_CRC 2;
BA_ "GenSigSwitchedByIgnition" SG_ 2463978633 VAS_L_01_CRC 0;
BA_ "GenSigSendType" SG_ 2463978633 VAS_L_Autobahnview_aktiv 3;
BA_ "GenSigSwitchedByIgnition" SG_ 2463978633 VAS_L_Autobahnview_aktiv 0;
BA_ "GenSigSendType" SG_ 2463978633 VAS_L_Bedien_Master 3;
BA_ "GenSigSwitchedByIgnition" SG_ 2463978633 VAS_L_Bedien_Master 0;
BA_ "GenSigSendType" SG_ 2463978633 VAS_L_Heizung_Aktiv 3;
BA_ "GenSigSwitchedByIgnition" SG_ 2463978633 VAS_L_Heizung_Aktiv 0;
BA_ "Fehlerwert" SG_ 2463978633 VAS_L_Heizung_Aktiv 127;
BA_ "GenSigSendType" SG_ 2463978633 VAS_L_HMI_Aktiv 3;
BA_ "GenSigSwitchedByIgnition" SG_ 2463978633 VAS_L_HMI_Aktiv 0;
BA_ "GenSigSendType" SG_ 2463978633 VAS_L_Parkview_aktiv 3;
BA_ "GenSigSwitchedByIgnition" SG_ 2463978633 VAS_L_Parkview_aktiv 0;
BA_ "GenSigSendType" SG_ 2463978633 VAS_L_Spiegelauswahl 3;
BA_ "GenSigSwitchedByIgnition" SG_ 2463978633 VAS_L_Spiegelauswahl 0;
BA_ "GenSigSendType" SG_ 2463978633 VAS_L_SWA_HMI_Diagnose 0;
BA_ "GenSigSwitchedByIgnition" SG_ 2463978633 VAS_L_SWA_HMI_Diagnose 0;
BA_ "GenSigSendType" SG_ 2463978633 VAS_L_Texte 3;
BA_ "GenSigStartValue" SG_ 2463978633 VAS_L_Texte 7;
BA_ "GenSigSwitchedByIgnition" SG_ 2463978633 VAS_L_Texte 0;
BA_ "GenSigSendType" SG_ 2463978633 VAS_L_Turnview_aktiv 3;
BA_ "GenSigSwitchedByIgnition" SG_ 2463978633 VAS_L_Turnview_aktiv 0;
BA_ "GenSigSendType" SG_ 2463978633 VAS_L_Verstell_Pos_X 3;
BA_ "GenSigSwitchedByIgnition" SG_ 2463978633 VAS_L_Verstell_Pos_X 0;
BA_ "Fehlerwert" SG_ 2463978633 VAS_L_Verstell_Pos_X 511;
BA_ "GenSigSendType" SG_ 2463978633 VAS_L_Verstell_Pos_Y 3;
BA_ "GenSigSwitchedByIgnition" SG_ 2463978633 VAS_L_Verstell_Pos_Y 0;
BA_ "Fehlerwert" SG_ 2463978633 VAS_L_Verstell_Pos_Y 511;
BA_ "GenSigSendType" SG_ 2463978633 VAS_L_Zoom_Level 3;
BA_ "GenSigSwitchedByIgnition" SG_ 2463978633 VAS_L_Zoom_Level 0;
BA_ "Fehlerwert" SG_ 2463978633 VAS_L_Zoom_Level 127;
BA_ "GenSigSendType" SG_ 995 VD_SpannungsAnf 3;
BA_ "GenSigSwitchedByIgnition" SG_ 995 VD_SpannungsAnf 0;
BA_ "GenSigSendType" SG_ 995 Verdeck_01_BZ 0;
BA_ "GenSigFuncType" SG_ 995 Verdeck_01_BZ 1;
BA_ "GenSigSwitchedByIgnition" SG_ 995 Verdeck_01_BZ 0;
BA_ "GenSigSendType" SG_ 995 Verdeck_01_CRC 0;
BA_ "GenSigFuncType" SG_ 995 Verdeck_01_CRC 2;
BA_ "GenSigActiveRepetitions" SG_ 995 VS_BFS_AutoHoch 5;
BA_ "GenSigSendType" SG_ 995 VS_BFS_AutoHoch 4;
BA_ "GenSigSwitchedByIgnition" SG_ 995 VS_BFS_AutoHoch 0;
BA_ "GenSigActiveRepetitions" SG_ 995 VS_BFS_AutoTief 5;
BA_ "GenSigSendType" SG_ 995 VS_BFS_AutoTief 4;
BA_ "GenSigSwitchedByIgnition" SG_ 995 VS_BFS_AutoTief 0;
BA_ "GenSigActiveRepetitions" SG_ 995 VS_BFS_ManHoch 5;
BA_ "GenSigSendType" SG_ 995 VS_BFS_ManHoch 4;
BA_ "GenSigSwitchedByIgnition" SG_ 995 VS_BFS_ManHoch 0;
BA_ "GenSigActiveRepetitions" SG_ 995 VS_BFS_ManTief 5;
BA_ "GenSigSendType" SG_ 995 VS_BFS_ManTief 4;
BA_ "GenSigSwitchedByIgnition" SG_ 995 VS_BFS_ManTief 0;
BA_ "GenSigSendType" SG_ 995 VS_Buzzer 3;
BA_ "GenSigSwitchedByIgnition" SG_ 995 VS_Buzzer 0;
BA_ "GenSigSendType" SG_ 995 VS_FH_BT_Langhub 3;
BA_ "GenSigSwitchedByIgnition" SG_ 995 VS_FH_BT_Langhub 0;
BA_ "GenSigSendType" SG_ 995 VS_FH_FT_Langhub 3;
BA_ "GenSigSwitchedByIgnition" SG_ 995 VS_FH_FT_Langhub 0;
BA_ "GenSigSendType" SG_ 995 VS_FH_HBFS_Langhub 3;
BA_ "GenSigSwitchedByIgnition" SG_ 995 VS_FH_HBFS_Langhub 0;
BA_ "GenSigSendType" SG_ 995 VS_FH_HFS_Langhub 3;
BA_ "GenSigSwitchedByIgnition" SG_ 995 VS_FH_HFS_Langhub 0;
BA_ "GenSigActiveRepetitions" SG_ 995 VS_FS_AutoHoch 5;
BA_ "GenSigSendType" SG_ 995 VS_FS_AutoHoch 4;
BA_ "GenSigSwitchedByIgnition" SG_ 995 VS_FS_AutoHoch 0;
BA_ "GenSigActiveRepetitions" SG_ 995 VS_FS_AutoTief 5;
BA_ "GenSigSendType" SG_ 995 VS_FS_AutoTief 4;
BA_ "GenSigSwitchedByIgnition" SG_ 995 VS_FS_AutoTief 0;
BA_ "GenSigActiveRepetitions" SG_ 995 VS_FS_ManHoch 5;
BA_ "GenSigSendType" SG_ 995 VS_FS_ManHoch 4;
BA_ "GenSigSwitchedByIgnition" SG_ 995 VS_FS_ManHoch 0;
BA_ "GenSigActiveRepetitions" SG_ 995 VS_FS_ManTief 5;
BA_ "GenSigSendType" SG_ 995 VS_FS_ManTief 4;
BA_ "GenSigSwitchedByIgnition" SG_ 995 VS_FS_ManTief 0;
BA_ "GenSigSendType" SG_ 995 VS_Hardtop 3;
BA_ "GenSigSwitchedByIgnition" SG_ 995 VS_Hardtop 0;
BA_ "GenSigActiveRepetitions" SG_ 995 VS_HBFS_AutoHoch 5;
BA_ "GenSigSendType" SG_ 995 VS_HBFS_AutoHoch 4;
BA_ "GenSigSwitchedByIgnition" SG_ 995 VS_HBFS_AutoHoch 0;
BA_ "GenSigActiveRepetitions" SG_ 995 VS_HBFS_AutoTief 5;
BA_ "GenSigSendType" SG_ 995 VS_HBFS_AutoTief 4;
BA_ "GenSigSwitchedByIgnition" SG_ 995 VS_HBFS_AutoTief 0;
BA_ "GenSigActiveRepetitions" SG_ 995 VS_HBFS_ManHoch 5;
BA_ "GenSigSendType" SG_ 995 VS_HBFS_ManHoch 4;
BA_ "GenSigSwitchedByIgnition" SG_ 995 VS_HBFS_ManHoch 0;
BA_ "GenSigActiveRepetitions" SG_ 995 VS_HBFS_ManTief 5;
BA_ "GenSigSendType" SG_ 995 VS_HBFS_ManTief 4;
BA_ "GenSigSwitchedByIgnition" SG_ 995 VS_HBFS_ManTief 0;
BA_ "GenSigSendType" SG_ 995 VS_HD_sperren 3;
BA_ "GenSigSwitchedByIgnition" SG_ 995 VS_HD_sperren 0;
BA_ "GenSigSendType" SG_ 995 VS_Heckschloss_auf 3;
BA_ "GenSigSwitchedByIgnition" SG_ 995 VS_Heckschloss_auf 0;
BA_ "GenSigActiveRepetitions" SG_ 995 VS_HFS_AutoHoch 5;
BA_ "GenSigSendType" SG_ 995 VS_HFS_AutoHoch 4;
BA_ "GenSigSwitchedByIgnition" SG_ 995 VS_HFS_AutoHoch 0;
BA_ "GenSigActiveRepetitions" SG_ 995 VS_HFS_AutoTief 5;
BA_ "GenSigSendType" SG_ 995 VS_HFS_AutoTief 4;
BA_ "GenSigSwitchedByIgnition" SG_ 995 VS_HFS_AutoTief 0;
BA_ "GenSigActiveRepetitions" SG_ 995 VS_HFS_ManHoch 5;
BA_ "GenSigSendType" SG_ 995 VS_HFS_ManHoch 4;
BA_ "GenSigSwitchedByIgnition" SG_ 995 VS_HFS_ManHoch 0;
BA_ "GenSigActiveRepetitions" SG_ 995 VS_HFS_ManTief 5;
BA_ "GenSigSendType" SG_ 995 VS_HFS_ManTief 4;
BA_ "GenSigSwitchedByIgnition" SG_ 995 VS_HFS_ManTief 0;
BA_ "GenSigSendType" SG_ 995 VS_HHS_enable 3;
BA_ "GenSigSwitchedByIgnition" SG_ 995 VS_HHS_enable 0;
BA_ "GenSigSendType" SG_ 995 VS_Lampe_Blk 3;
BA_ "GenSigSwitchedByIgnition" SG_ 995 VS_Lampe_Blk 0;
BA_ "GenSigSendType" SG_ 995 VS_StartStopp_Info 3;
BA_ "GenSigSwitchedByIgnition" SG_ 995 VS_StartStopp_Info 0;
BA_ "Fehlerwert" SG_ 995 VS_StartStopp_Info 3;
BA_ "GenSigSendType" SG_ 995 VS_VD_Bew_auf 3;
BA_ "GenSigSwitchedByIgnition" SG_ 995 VS_VD_Bew_auf 0;
BA_ "GenSigSendType" SG_ 995 VS_VD_Bew_zu 3;
BA_ "GenSigSwitchedByIgnition" SG_ 995 VS_VD_Bew_zu 0;
BA_ "GenSigSendType" SG_ 995 VS_VD_entriegelt 3;
BA_ "GenSigSwitchedByIgnition" SG_ 995 VS_VD_entriegelt 0;
BA_ "GenSigSendType" SG_ 995 VS_VD_Fehler 3;
BA_ "GenSigSwitchedByIgnition" SG_ 995 VS_VD_Fehler 0;
BA_ "GenSigSendType" SG_ 995 VS_VD_offen_ver 3;
BA_ "GenSigSwitchedByIgnition" SG_ 995 VS_VD_offen_ver 0;
BA_ "GenSigSendType" SG_ 995 VS_VD_zu_ver 3;
BA_ "GenSigSwitchedByIgnition" SG_ 995 VS_VD_zu_ver 0;
BA_ "GenSigSendType" SG_ 995 VS_VD_Zwischenposition 3;
BA_ "GenSigSwitchedByIgnition" SG_ 995 VS_VD_Zwischenposition 0;
BA_ "GenSigSendType" SG_ 995 VS_VDKD_auf 3;
BA_ "GenSigSwitchedByIgnition" SG_ 995 VS_VDKD_auf 0;
BA_ "GenSigSendType" SG_ 995 VS_Verdeck_Anf 3;
BA_ "GenSigSwitchedByIgnition" SG_ 995 VS_Verdeck_Anf 0;
BA_ "GenSigSendType" SG_ 995 VS_Windschott_nicht_abgelegt 3;
BA_ "GenSigSwitchedByIgnition" SG_ 995 VS_Windschott_nicht_abgelegt 0;
BA_ "GenSigSendType" SG_ 995 VSG_Meldungen 3;
BA_ "GenSigSwitchedByIgnition" SG_ 995 VSG_Meldungen 0;
BA_ "GenSigSwitchedByIgnition" SG_ 1716 KS_Geheimnis_1 0;
BA_ "GenSigSwitchedByIgnition" SG_ 1716 KS_Geheimnis_2 0;
BA_ "GenSigSwitchedByIgnition" SG_ 1716 KS_Geheimnis_3 0;
BA_ "GenSigSwitchedByIgnition" SG_ 1716 KS_Geheimnis_4 0;
BA_ "GenSigSendType" SG_ 1716 VIN_01_MUX 0;
BA_ "GenSigSwitchedByIgnition" SG_ 1716 VIN_01_MUX 0;
BA_ "GenSigStartValue" SG_ 1716 VIN_1 45;
BA_ "GenSigSwitchedByIgnition" SG_ 1716 VIN_1 0;
BA_ "GenSigStartValue" SG_ 1716 VIN_10 45;
BA_ "GenSigSwitchedByIgnition" SG_ 1716 VIN_10 0;
BA_ "GenSigStartValue" SG_ 1716 VIN_11 45;
BA_ "GenSigSwitchedByIgnition" SG_ 1716 VIN_11 0;
BA_ "GenSigStartValue" SG_ 1716 VIN_12 45;
BA_ "GenSigSwitchedByIgnition" SG_ 1716 VIN_12 0;
BA_ "GenSigStartValue" SG_ 1716 VIN_13 45;
BA_ "GenSigSwitchedByIgnition" SG_ 1716 VIN_13 0;
BA_ "GenSigStartValue" SG_ 1716 VIN_14 45;
BA_ "GenSigSwitchedByIgnition" SG_ 1716 VIN_14 0;
BA_ "GenSigStartValue" SG_ 1716 VIN_15 45;
BA_ "GenSigSwitchedByIgnition" SG_ 1716 VIN_15 0;
BA_ "GenSigStartValue" SG_ 1716 VIN_16 45;
BA_ "GenSigSwitchedByIgnition" SG_ 1716 VIN_16 0;
BA_ "GenSigStartValue" SG_ 1716 VIN_17 45;
BA_ "GenSigSwitchedByIgnition" SG_ 1716 VIN_17 0;
BA_ "GenSigStartValue" SG_ 1716 VIN_2 45;
BA_ "GenSigSwitchedByIgnition" SG_ 1716 VIN_2 0;
BA_ "GenSigStartValue" SG_ 1716 VIN_3 45;
BA_ "GenSigSwitchedByIgnition" SG_ 1716 VIN_3 0;
BA_ "GenSigStartValue" SG_ 1716 VIN_4 45;
BA_ "GenSigSwitchedByIgnition" SG_ 1716 VIN_4 0;
BA_ "GenSigStartValue" SG_ 1716 VIN_5 45;
BA_ "GenSigSwitchedByIgnition" SG_ 1716 VIN_5 0;
BA_ "GenSigStartValue" SG_ 1716 VIN_6 45;
BA_ "GenSigSwitchedByIgnition" SG_ 1716 VIN_6 0;
BA_ "GenSigStartValue" SG_ 1716 VIN_7 45;
BA_ "GenSigSwitchedByIgnition" SG_ 1716 VIN_7 0;
BA_ "GenSigStartValue" SG_ 1716 VIN_8 45;
BA_ "GenSigSwitchedByIgnition" SG_ 1716 VIN_8 0;
BA_ "GenSigStartValue" SG_ 1716 VIN_9 45;
BA_ "GenSigSwitchedByIgnition" SG_ 1716 VIN_9 0;
BA_ "GenSigSendType" SG_ 385 VZE_Akustik_Limitwechsel 3;
BA_ "GenSigSwitchedByIgnition" SG_ 385 VZE_Akustik_Limitwechsel 0;
BA_ "GenSigSendType" SG_ 385 VZE_Anzeigemodus 3;
BA_ "GenSigSendType" SG_ 385 VZE_Anzeigeunterdrueck_Zeichen_1 3;
BA_ "GenSigSendType" SG_ 385 VZE_Anzeigeunterdrueck_Zeichen_2 3;
BA_ "GenSigSendType" SG_ 385 VZE_Anzeigeunterdrueck_Zeichen_3 3;
BA_ "GenSigSendType" SG_ 385 VZE_Gong 0;
BA_ "GenSigSendType" SG_ 385 VZE_Hinweistext 3;
BA_ "GenSigSendType" SG_ 385 VZE_Modus_OptischeWarnung 3;
BA_ "GenSigSwitchedByIgnition" SG_ 385 VZE_Modus_OptischeWarnung 0;
BA_ "GenSigSendType" SG_ 385 VZE_Verkehrszeichen_1 3;
BA_ "GenSigSendType" SG_ 385 VZE_Verkehrszeichen_2 3;
BA_ "GenSigSendType" SG_ 385 VZE_Verkehrszeichen_3 3;
BA_ "GenSigSendType" SG_ 385 VZE_Verkehrszeichen_Einheit 3;
BA_ "GenSigSwitchedByIgnition" SG_ 385 VZE_Verkehrszeichen_Einheit 0;
BA_ "GenSigSendType" SG_ 385 VZE_Warnung_Verkehrszeichen_1 3;
BA_ "GenSigSendType" SG_ 385 VZE_Warnung_Verkehrszeichen_2 3;
BA_ "GenSigSendType" SG_ 385 VZE_Warnung_Verkehrszeichen_3 3;
BA_ "GenSigSendType" SG_ 385 VZE_Zeichen_01_Gesetz 0;
BA_ "GenSigSendType" SG_ 385 VZE_Zeichen_01_Kamera 0;
BA_ "GenSigSendType" SG_ 385 VZE_Zeichen_01_KameraWied 0;
BA_ "GenSigSendType" SG_ 385 VZE_Zeichen_01_Karte 0;
BA_ "GenSigSendType" SG_ 385 VZE_Zeichen_02_Gesetz 0;
BA_ "GenSigSendType" SG_ 385 VZE_Zeichen_02_Kamera 0;
BA_ "GenSigSendType" SG_ 385 VZE_Zeichen_02_KameraWied 0;
BA_ "GenSigSendType" SG_ 385 VZE_Zeichen_02_Karte 0;
BA_ "GenSigSendType" SG_ 385 VZE_Zeichen_03_Gesetz 0;
BA_ "GenSigSendType" SG_ 385 VZE_Zeichen_03_Kamera 0;
BA_ "GenSigSendType" SG_ 385 VZE_Zeichen_03_KameraWied 0;
BA_ "GenSigSendType" SG_ 385 VZE_Zeichen_03_Karte 0;
BA_ "GenSigSendType" SG_ 385 VZE_Zusatzschild_1 3;
BA_ "GenSigSendType" SG_ 385 VZE_Zusatzschild_2 3;
BA_ "GenSigSendType" SG_ 385 VZE_Zusatzschild_3 3;
BA_ "GenSigSendType" SG_ 668 VZE_Akustik_Limitwechsel_Status 3;
BA_ "GenSigSwitchedByIgnition" SG_ 668 VZE_Akustik_Limitwechsel_Status 0;
BA_ "GenSigSendType" SG_ 668 VZE_Anhaenger_Vmax 3;
BA_ "GenSigStartValue" SG_ 668 VZE_Anhaenger_Vmax 14;
BA_ "Fehlerwert" SG_ 668 VZE_Anhaenger_Vmax 15;
BA_ "GenSigSendType" SG_ 668 VZE_Anzeigeunterdrueck_Zeichen_4 3;
BA_ "GenSigSendType" SG_ 668 VZE_Anzeigeunterdrueck_Zeichen_5 3;
BA_ "GenSigSendType" SG_ 668 VZE_Baustelle 0;
BA_ "GenSigSendType" SG_ 668 VZE_SLWF_Status 3;
BA_ "GenSigSwitchedByIgnition" SG_ 668 VZE_SLWF_Status 0;
BA_ "GenSigSendType" SG_ 668 VZE_Verkehrszeichen_4 3;
BA_ "GenSigSendType" SG_ 668 VZE_Verkehrszeichen_5 3;
BA_ "GenSigSendType" SG_ 668 VZE_Warnung_Verkehrszeichen_4 3;
BA_ "GenSigSendType" SG_ 668 VZE_Warnung_Verkehrszeichen_5 3;
BA_ "GenSigSendType" SG_ 668 VZE_Zeichen_04_Gesetz 0;
BA_ "GenSigSendType" SG_ 668 VZE_Zeichen_04_Kamera 0;
BA_ "GenSigSendType" SG_ 668 VZE_Zeichen_04_KameraWied 0;
BA_ "GenSigSendType" SG_ 668 VZE_Zeichen_04_Karte 0;
BA_ "GenSigSendType" SG_ 668 VZE_Zeichen_05_Entfernung 0;
BA_ "GenSigSendType" SG_ 668 VZE_Zeichen_05_Entfernung_StdA 0;
BA_ "GenSigSendType" SG_ 668 VZE_Zeichen_05_Gesetz 0;
BA_ "GenSigSendType" SG_ 668 VZE_Zeichen_05_Kamera 0;
BA_ "GenSigSendType" SG_ 668 VZE_Zeichen_05_KameraWied 0;
BA_ "GenSigSendType" SG_ 668 VZE_Zeichen_05_Karte 0;
BA_ "GenSigSendType" SG_ 668 VZE_Zusatzschild_4 3;
BA_ "GenSigSendType" SG_ 668 VZE_Zusatzschild_5 3;
BA_ "GenSigSendType" SG_ 2463978672 VZE_Anzeige_VZ_1 3;
BA_ "GenSigSwitchedByIgnition" SG_ 2463978672 VZE_Anzeige_VZ_1 0;
BA_ "GenSigSendType" SG_ 2463978672 VZE_Anzeige_VZ_2 3;
BA_ "GenSigSwitchedByIgnition" SG_ 2463978672 VZE_Anzeige_VZ_2 0;
BA_ "GenSigSendType" SG_ 2463978672 VZE_Anzeige_VZ_3 3;
BA_ "GenSigSwitchedByIgnition" SG_ 2463978672 VZE_Anzeige_VZ_3 0;
BA_ "GenSigSendType" SG_ 2463978672 VZE_Anzeige_ZS_1 3;
BA_ "GenSigSwitchedByIgnition" SG_ 2463978672 VZE_Anzeige_ZS_1 0;
BA_ "GenSigSendType" SG_ 2463978672 VZE_Anzeige_ZS_2 3;
BA_ "GenSigSwitchedByIgnition" SG_ 2463978672 VZE_Anzeige_ZS_2 0;
BA_ "GenSigSendType" SG_ 2463978672 VZE_Anzeige_ZS_3 3;
BA_ "GenSigSwitchedByIgnition" SG_ 2463978672 VZE_Anzeige_ZS_3 0;
BA_ "GenSigSendType" SG_ 2463978672 VZE_FoD_Status 3;
BA_ "GenSigSwitchedByIgnition" SG_ 2463978672 VZE_FoD_Status 0;
BA_ "GenSigSendType" SG_ 2463978672 VZE_Hinweistext_03 3;
BA_ "GenSigSwitchedByIgnition" SG_ 2463978672 VZE_Hinweistext_03 0;
BA_ "GenSigSendType" SG_ 2463978672 VZE_Land 3;
BA_ "GenSigSwitchedByIgnition" SG_ 2463978672 VZE_Land 0;
BA_ "GenSigSendType" SG_ 2463978672 VZE_Warnung_VZ_1 3;
BA_ "GenSigSwitchedByIgnition" SG_ 2463978672 VZE_Warnung_VZ_1 0;
BA_ "GenSigSendType" SG_ 2463978672 VZE_Warnung_VZ_2 3;
BA_ "GenSigSwitchedByIgnition" SG_ 2463978672 VZE_Warnung_VZ_2 0;
BA_ "GenSigSendType" SG_ 2463978672 VZE_Warnung_VZ_3 3;
BA_ "GenSigSwitchedByIgnition" SG_ 2463978672 VZE_Warnung_VZ_3 0;
BA_ "GenSigSendType" SG_ 181 Waehlhebel_04_BZ 0;
BA_ "GenSigFuncType" SG_ 181 Waehlhebel_04_BZ 1;
BA_ "GenSigSwitchedByIgnition" SG_ 181 Waehlhebel_04_BZ 0;
BA_ "GenSigSendType" SG_ 181 Waehlhebel_04_CRC 0;
BA_ "GenSigFuncType" SG_ 181 Waehlhebel_04_CRC 2;
BA_ "GenSigSwitchedByIgnition" SG_ 181 Waehlhebel_04_CRC 0;
BA_ "GenSigSendType" SG_ 181 WH_Ende_N_Haltephase 0;
BA_ "GenSigSwitchedByIgnition" SG_ 181 WH_Ende_N_Haltephase 0;
BA_ "GenSigSendType" SG_ 181 WH_Entsperrtaste_02 0;
BA_ "GenSigSwitchedByIgnition" SG_ 181 WH_Entsperrtaste_02 0;
BA_ "Fehlerwert" SG_ 181 WH_Entsperrtaste_02 3;
BA_ "GenSigSendType" SG_ 181 WH_Fahrstufe 0;
BA_ "GenSigSwitchedByIgnition" SG_ 181 WH_Fahrstufe 0;
BA_ "Fehlerwert" SG_ 181 WH_Fahrstufe 15;
BA_ "GenSigSendType" SG_ 181 WH_gespeicherte_Fahrstufe 0;
BA_ "GenSigSwitchedByIgnition" SG_ 181 WH_gespeicherte_Fahrstufe 0;
BA_ "GenSigSendType" SG_ 181 WH_Initialisierung 0;
BA_ "GenSigStartValue" SG_ 181 WH_Initialisierung 1;
BA_ "GenSigSwitchedByIgnition" SG_ 181 WH_Initialisierung 0;
BA_ "GenSigSendType" SG_ 181 WH_Ist_Haltemagnet 0;
BA_ "GenSigSwitchedByIgnition" SG_ 181 WH_Ist_Haltemagnet 0;
BA_ "Fehlerwert" SG_ 181 WH_Ist_Haltemagnet 3;
BA_ "GenSigSendType" SG_ 181 WH_P_Taste 0;
BA_ "GenSigSwitchedByIgnition" SG_ 181 WH_P_Taste 0;
BA_ "Fehlerwert" SG_ 181 WH_P_Taste 3;
BA_ "GenSigSendType" SG_ 181 WH_SensorPos_roh 0;
BA_ "GenSigSwitchedByIgnition" SG_ 181 WH_SensorPos_roh 0;
BA_ "Fehlerwert" SG_ 181 WH_SensorPos_roh 15;
BA_ "GenSigSendType" SG_ 181 WH_SensorPos_roh_inv 0;
BA_ "GenSigStartValue" SG_ 181 WH_SensorPos_roh_inv 15;
BA_ "GenSigSwitchedByIgnition" SG_ 181 WH_SensorPos_roh_inv 0;
BA_ "GenSigSendType" SG_ 181 WH_Status_Shiftlock 0;
BA_ "GenSigSwitchedByIgnition" SG_ 181 WH_Status_Shiftlock 0;
BA_ "Fehlerwert" SG_ 181 WH_Status_Shiftlock 7;
BA_ "GenSigSendType" SG_ 181 WH_Test_Aktiv 0;
BA_ "GenSigSwitchedByIgnition" SG_ 181 WH_Test_Aktiv 0;
BA_ "GenSigSendType" SG_ 181 WH_Testergebnis 0;
BA_ "GenSigSwitchedByIgnition" SG_ 181 WH_Testergebnis 0;
BA_ "GenSigSendType" SG_ 181 WH_Variante 0;
BA_ "GenSigSwitchedByIgnition" SG_ 181 WH_Variante 0;
BA_ "GenSigSendType" SG_ 2589283476 WH_Warnung_02 3;
BA_ "GenSigSwitchedByIgnition" SG_ 2589283476 WH_Warnung_02 0;
BA_ "GenSigSendType" SG_ 2589283476 WH_Warnung_03 3;
BA_ "GenSigSwitchedByIgnition" SG_ 2589283476 WH_Warnung_03 0;
BA_ "GenSigSendType" SG_ 916 GE_Sollgang 3;
BA_ "GenSigSwitchedByIgnition" SG_ 916 GE_Sollgang 0;
BA_ "GenSigSendType" SG_ 916 GE_Stoppverbot_Anz_01 3;
BA_ "GenSigSwitchedByIgnition" SG_ 916 GE_Stoppverbot_Anz_01 0;
BA_ "GenSigSendType" SG_ 916 GE_Stoppverbot_Anz_02 3;
BA_ "GenSigSwitchedByIgnition" SG_ 916 GE_Stoppverbot_Anz_02 0;
BA_ "GenSigSendType" SG_ 916 GE_Stoppverbot_Anz_03 3;
BA_ "GenSigSwitchedByIgnition" SG_ 916 GE_Stoppverbot_Anz_03 0;
BA_ "GenSigSendType" SG_ 916 GE_Stoppverbot_Anz_04 3;
BA_ "GenSigSwitchedByIgnition" SG_ 916 GE_Stoppverbot_Anz_04 0;
BA_ "GenSigSendType" SG_ 916 GE_Stoppverbot_Anz_05 3;
BA_ "GenSigSwitchedByIgnition" SG_ 916 GE_Stoppverbot_Anz_05 0;
BA_ "GenSigSendType" SG_ 916 GE_Stoppverbot_Anz_06 3;
BA_ "GenSigSwitchedByIgnition" SG_ 916 GE_Stoppverbot_Anz_06 0;
BA_ "GenSigSendType" SG_ 916 GE_Stoppverbot_Anz_07 3;
BA_ "GenSigSwitchedByIgnition" SG_ 916 GE_Stoppverbot_Anz_07 0;
BA_ "GenSigSendType" SG_ 916 GE_Stoppverbot_Anz_Std 3;
BA_ "GenSigSwitchedByIgnition" SG_ 916 GE_Stoppverbot_Anz_Std 0;
BA_ "GenSigSendType" SG_ 916 GE_Tipschaltempf_verfuegbar 3;
BA_ "GenSigFuncType" SG_ 916 GE_Tipschaltempf_verfuegbar 8;
BA_ "GenSigSwitchedByIgnition" SG_ 916 GE_Tipschaltempf_verfuegbar 0;
BA_ "GenSigSendType" SG_ 916 GE_Wiederstart_Anz_Std 3;
BA_ "GenSigSwitchedByIgnition" SG_ 916 GE_Wiederstart_Anz_Std 0;
BA_ "GenSigSendType" SG_ 916 WBA_03_BZ 0;
BA_ "GenSigFuncType" SG_ 916 WBA_03_BZ 1;
BA_ "GenSigSwitchedByIgnition" SG_ 916 WBA_03_BZ 0;
BA_ "GenSigSendType" SG_ 916 WBA_03_CRC 0;
BA_ "GenSigFuncType" SG_ 916 WBA_03_CRC 2;
BA_ "GenSigSwitchedByIgnition" SG_ 916 WBA_03_CRC 0;
BA_ "GenSigSendType" SG_ 916 WBA_Blinken 3;
BA_ "GenSigSwitchedByIgnition" SG_ 916 WBA_Blinken 0;
BA_ "GenSigSendType" SG_ 916 WBA_eing_Gang_02 3;
BA_ "GenSigSwitchedByIgnition" SG_ 916 WBA_eing_Gang_02 0;
BA_ "GenSigSendType" SG_ 916 WBA_Fahrstufe_02 3;
BA_ "GenSigSwitchedByIgnition" SG_ 916 WBA_Fahrstufe_02 0;
BA_ "GenSigSendType" SG_ 916 WBA_GE_Texte 3;
BA_ "GenSigSwitchedByIgnition" SG_ 916 WBA_GE_Texte 0;
BA_ "GenSigSendType" SG_ 916 WBA_GE_Texte_02 3;
BA_ "GenSigSwitchedByIgnition" SG_ 916 WBA_GE_Texte_02 0;
BA_ "GenSigSendType" SG_ 916 WBA_GE_Texte_03 0;
BA_ "Fehlerwert" SG_ 916 WBA_GE_Texte_03 15;
BA_ "GenSigSendType" SG_ 916 WBA_GE_Warnung_02 3;
BA_ "GenSigSwitchedByIgnition" SG_ 916 WBA_GE_Warnung_02 0;
BA_ "GenSigSendType" SG_ 916 WBA_GE_Zusatzwarnungen 3;
BA_ "GenSigSwitchedByIgnition" SG_ 916 WBA_GE_Zusatzwarnungen 0;
BA_ "GenSigSendType" SG_ 916 WBA_Schaltschema 3;
BA_ "GenSigSwitchedByIgnition" SG_ 916 WBA_Schaltschema 0;
BA_ "GenSigSendType" SG_ 916 WBA_Segeln_aktiv 3;
BA_ "GenSigSwitchedByIgnition" SG_ 916 WBA_Segeln_aktiv 0;
BA_ "GenSigSendType" SG_ 916 WBA_ZielFahrstufe 3;
BA_ "GenSigSwitchedByIgnition" SG_ 916 WBA_ZielFahrstufe 0;
BA_ "GenSigSendType" SG_ 2527679839 WCU_PrctVolWaRem 3;
BA_ "GenSigStartValue" SG_ 2527679839 WCU_PrctVolWaRem 126;
BA_ "GenSigSwitchedByIgnition" SG_ 2527679839 WCU_PrctVolWaRem 0;
BA_ "Fehlerwert" SG_ 2527679839 WCU_PrctVolWaRem 127;
BA_ "GenSigSendType" SG_ 2527679839 WCU_StTankWa 3;
BA_ "GenSigStartValue" SG_ 2527679839 WCU_StTankWa 14;
BA_ "GenSigSwitchedByIgnition" SG_ 2527679839 WCU_StTankWa 0;
BA_ "Fehlerwert" SG_ 2527679839 WCU_StTankWa 15;
BA_ "GenSigSendType" SG_ 2527679839 WCU_VolWaRefill 0;
BA_ "GenSigStartValue" SG_ 2527679839 WCU_VolWaRefill 126;
BA_ "GenSigSwitchedByIgnition" SG_ 2527679839 WCU_VolWaRefill 0;
BA_ "Fehlerwert" SG_ 2527679839 WCU_VolWaRefill 127;
BA_ "GenSigSendType" SG_ 2527679839 WCU_VolWaRem 0;
BA_ "GenSigStartValue" SG_ 2527679839 WCU_VolWaRem 510;
BA_ "GenSigSwitchedByIgnition" SG_ 2527679839 WCU_VolWaRem 0;
BA_ "Fehlerwert" SG_ 2527679839 WCU_VolWaRem 511;
BA_ "GenSigSendType" SG_ 2527679839 WCU_VolWaRemRaw 0;
BA_ "GenSigStartValue" SG_ 2527679839 WCU_VolWaRemRaw 510;
BA_ "GenSigSwitchedByIgnition" SG_ 2527679839 WCU_VolWaRemRaw 0;
BA_ "Fehlerwert" SG_ 2527679839 WCU_VolWaRemRaw 511;
BA_ "GenSigSendType" SG_ 1361 WFS_Betrieb_Lesespule 3;
BA_ "GenSigSwitchedByIgnition" SG_ 1361 WFS_Betrieb_Lesespule 0;
BA_ "GenSigSendType" SG_ 1361 WFS_ELV_authorisiert 3;
BA_ "GenSigSwitchedByIgnition" SG_ 1361 WFS_ELV_authorisiert 0;
BA_ "GenSigSendType" SG_ 1361 WFS_Fahrerhinweise 3;
BA_ "GenSigSwitchedByIgnition" SG_ 1361 WFS_Fahrerhinweise 0;
BA_ "GenSigSendType" SG_ 1361 WFS_ID_Geb_autorisiert 3;
BA_ "GenSigSwitchedByIgnition" SG_ 1361 WFS_ID_Geb_autorisiert 0;
BA_ "GenSigSendType" SG_ 1361 WFS_ID_Geb_autorisiert_in_Kl15 3;
BA_ "GenSigSwitchedByIgnition" SG_ 1361 WFS_ID_Geb_autorisiert_in_Kl15 0;
BA_ "GenSigSendType" SG_ 1361 WFS_ID_Geb_steckt 3;
BA_ "GenSigSwitchedByIgnition" SG_ 1361 WFS_ID_Geb_steckt 0;
BA_ "GenSigSendType" SG_ 1361 WFS_Klemmenfreigabe 3;
BA_ "GenSigSwitchedByIgnition" SG_ 1361 WFS_Klemmenfreigabe 0;
BA_ "GenSigSendType" SG_ 1361 WFS_LF_Aktiv 3;
BA_ "GenSigSwitchedByIgnition" SG_ 1361 WFS_LF_Aktiv 0;
BA_ "GenSigSendType" SG_ 1361 WFS_LZ 3;
BA_ "GenSigSwitchedByIgnition" SG_ 1361 WFS_LZ 0;
BA_ "GenSigSendType" SG_ 1361 WFS_Parken_Status 3;
BA_ "GenSigSwitchedByIgnition" SG_ 1361 WFS_Parken_Status 0;
BA_ "GenSigSendType" SG_ 1361 WFS_Safe 3;
BA_ "GenSigSwitchedByIgnition" SG_ 1361 WFS_Safe 0;
BA_ "GenSigSendType" SG_ 1361 WFS_Schluessel_Fahrberecht 0;
BA_ "GenSigSwitchedByIgnition" SG_ 1361 WFS_Schluessel_Fahrberecht 0;
BA_ "GenSigSendType" SG_ 1361 WFS_Schluessel_Ist 3;
BA_ "GenSigSwitchedByIgnition" SG_ 1361 WFS_Schluessel_Ist 0;
BA_ "GenSigSendType" SG_ 1361 WFS_Schluessel_Soll 3;
BA_ "GenSigSwitchedByIgnition" SG_ 1361 WFS_Schluessel_Soll 0;
BA_ "GenSigSendType" SG_ 1702 BCM1_SRA_aktiv 3;
BA_ "GenSigSwitchedByIgnition" SG_ 1702 BCM1_SRA_aktiv 0;
BA_ "GenSigActiveRepetitions" SG_ 1702 Heckwischer_Anforderung 3;
BA_ "GenSigSendType" SG_ 1702 Heckwischer_Anforderung 4;
BA_ "GenSigSwitchedByIgnition" SG_ 1702 Heckwischer_Anforderung 0;
BA_ "GenSigSendType" SG_ 1702 Waschen_vorne_aktiv 3;
BA_ "GenSigSwitchedByIgnition" SG_ 1702 Waschen_vorne_aktiv 0;
BA_ "GenSigSendType" SG_ 1702 Wischer1_Wischgeschwindigkeit 0;
BA_ "GenSigStartValue" SG_ 1702 Wischer1_Wischgeschwindigkeit 62;
BA_ "GenSigSwitchedByIgnition" SG_ 1702 Wischer1_Wischgeschwindigkeit 0;
BA_ "Fehlerwert" SG_ 1702 Wischer1_Wischgeschwindigkeit 63;
BA_ "GenSigSendType" SG_ 1702 Wischer_Anzeigetext 3;
BA_ "GenSigSwitchedByIgnition" SG_ 1702 Wischer_Anzeigetext 0;
BA_ "GenSigSendType" SG_ 1702 Wischer_vorne_aktiv 3;
BA_ "GenSigSwitchedByIgnition" SG_ 1702 Wischer_vorne_aktiv 0;
BA_ "GenSigSendType" SG_ 1702 Wischer_vorne_blockiert 3;
BA_ "GenSigSwitchedByIgnition" SG_ 1702 Wischer_vorne_blockiert 0;
BA_ "GenSigSendType" SG_ 1702 Wischer_vorne_defekt 3;
BA_ "GenSigSwitchedByIgnition" SG_ 1702 Wischer_vorne_defekt 0;
BA_ "GenSigSendType" SG_ 1702 Wischer_vorne_Normal 3;
BA_ "GenSigSwitchedByIgnition" SG_ 1702 Wischer_vorne_Normal 0;
BA_ "GenSigSendType" SG_ 1702 Wischer_vorne_Parklage 3;
BA_ "GenSigStartValue" SG_ 1702 Wischer_vorne_Parklage 1;
BA_ "GenSigSwitchedByIgnition" SG_ 1702 Wischer_vorne_Parklage 0;
BA_ "GenSigSendType" SG_ 1702 Wischer_vorne_Schnell 3;
BA_ "GenSigSwitchedByIgnition" SG_ 1702 Wischer_vorne_Schnell 0;
BA_ "GenSigSendType" SG_ 1702 WWSs_01_upd 0;
BA_ "GenSigFuncType" SG_ 1702 WWSs_01_upd 5;
BA_ "GenSigSwitchedByIgnition" SG_ 1702 WWSs_01_upd 0;
BA_ "GenSigSendType" SG_ 2527679496 WIV_Russindex_02 0;
BA_ "GenSigSwitchedByIgnition" SG_ 2527679496 WIV_Russindex_02 0;
BA_ "GenSigSendType" SG_ 2527679496 WIV_Russindex_Ueberlauf 0;
BA_ "GenSigSwitchedByIgnition" SG_ 2527679496 WIV_Russindex_Ueberlauf 0;
BA_ "GenSigSendType" SG_ 2527679496 WIV_t_max 0;
BA_ "GenSigStartValue" SG_ 2527679496 WIV_t_max 24;
BA_ "GenSigSwitchedByIgnition" SG_ 2527679496 WIV_t_max 0;
BA_ "GenSigSendType" SG_ 2527679496 WIV_t_min 0;
BA_ "GenSigStartValue" SG_ 2527679496 WIV_t_min 12;
BA_ "GenSigSwitchedByIgnition" SG_ 2527679496 WIV_t_min 0;
BA_ "GenSigSendType" SG_ 2527679496 WIV_Verschleissindex_02 0;
BA_ "GenSigSwitchedByIgnition" SG_ 2527679496 WIV_Verschleissindex_02 0;
BA_ "GenSigSendType" SG_ 2527679496 WIV_Verschleissindex_Ueberlauf 0;
BA_ "GenSigSwitchedByIgnition" SG_ 2527679496 WIV_Verschleissindex_Ueberlauf 0;
BA_ "GenSigSendType" SG_ 2527679496 WIV_W_max 0;
BA_ "GenSigStartValue" SG_ 2527679496 WIV_W_max 31;
BA_ "GenSigSwitchedByIgnition" SG_ 2527679496 WIV_W_max 0;
BA_ "GenSigSendType" SG_ 2527679496 WIV_W_min 0;
BA_ "GenSigStartValue" SG_ 2527679496 WIV_W_min 17;
BA_ "GenSigSwitchedByIgnition" SG_ 2527679496 WIV_W_min 0;
BA_ "GenSigSwitchedByIgnition" SG_ 2617040384 XCP_HUD_CRO_01_Data 0;
BA_ "GenSigSwitchedByIgnition" SG_ 2617040385 XCP_HUD_DTO_01_Data 0;
BA_ "GenSigSwitchedByIgnition" SG_ 2617026048 XCP_Kombi_CRO_01_Data 0;
BA_ "GenSigSwitchedByIgnition" SG_ 2617026049 XCP_Kombi_DTO_01_Data 0;
BA_ "GenSigSwitchedByIgnition" SG_ 2617155072 XCP_Waehlhebel_CRO_01_Data 0;
BA_ "GenSigSwitchedByIgnition" SG_ 2617155073 XCP_Waehlhebel_DTO_01_Data 0;
BA_ "GenSigSendType" SG_ 2527679655 MMI_StartupAnimation 3;
BA_ "GenSigSwitchedByIgnition" SG_ 2527679655 MMI_StartupAnimation 0;
BA_ "GenSigSendType" SG_ 2527679655 ZR_SOC_Weiterfahrt 3;
BA_ "GenSigSwitchedByIgnition" SG_ 2527679655 ZR_SOC_Weiterfahrt 0;
BA_ "GenSigSendType" SG_ 2463978613 ZFAS_01_BZ 0;
BA_ "GenSigFuncType" SG_ 2463978613 ZFAS_01_BZ 1;
BA_ "GenSigSwitchedByIgnition" SG_ 2463978613 ZFAS_01_BZ 0;
BA_ "GenSigSendType" SG_ 2463978613 ZFAS_01_CRC 0;
BA_ "GenSigFuncType" SG_ 2463978613 ZFAS_01_CRC 2;
BA_ "GenSigSwitchedByIgnition" SG_ 2463978613 ZFAS_01_CRC 0;
BA_ "GenSigSendType" SG_ 2463978613 zFAS_Blinker_li 5;
BA_ "GenSigSwitchedByIgnition" SG_ 2463978613 zFAS_Blinker_li 0;
BA_ "GenSigSendType" SG_ 2463978613 zFAS_Blinker_re 5;
BA_ "GenSigSwitchedByIgnition" SG_ 2463978613 zFAS_Blinker_re 0;
BA_ "GenSigActiveRepetitions" SG_ 2463978613 zFAS_Pilottaster_LED_Farbe_Anf 5;
BA_ "GenSigSendType" SG_ 2463978613 zFAS_Pilottaster_LED_Farbe_Anf 4;
BA_ "GenSigActiveRepetitions" SG_ 2463978613 zFAS_Pilottaster_LED_Modus_Anf 5;
BA_ "GenSigSendType" SG_ 2463978613 zFAS_Pilottaster_LED_Modus_Anf 4;
BA_ "GenSigSendType" SG_ 1411 BCM_FH_Freigabe 3;
BA_ "GenSigSwitchedByIgnition" SG_ 1411 BCM_FH_Freigabe 0;
BA_ "GenSigSendType" SG_ 1411 BCM_HSK_Freigabe 3;
BA_ "GenSigSwitchedByIgnition" SG_ 1411 BCM_HSK_Freigabe 0;
BA_ "GenSigSendType" SG_ 1411 BCM_Komfortfkt_Freigabe 3;
BA_ "GenSigSwitchedByIgnition" SG_ 1411 BCM_Komfortfkt_Freigabe 0;
BA_ "GenSigSendType" SG_ 1411 BCM_Tankklappensteller_Fehler 0;
BA_ "GenSigSwitchedByIgnition" SG_ 1411 BCM_Tankklappensteller_Fehler 0;
BA_ "Fehlerwert" SG_ 1411 BCM_Tankklappensteller_Fehler 1;
BA_ "GenSigSendType" SG_ 1411 BCM_Verdeck_Freigabe 3;
BA_ "GenSigSwitchedByIgnition" SG_ 1411 BCM_Verdeck_Freigabe 0;
BA_ "GenSigSendType" SG_ 1411 DWA_aktiv 3;
BA_ "GenSigSwitchedByIgnition" SG_ 1411 DWA_aktiv 0;
BA_ "GenSigSendType" SG_ 1411 FBS_Warn_Schluessel_Batt 3;
BA_ "GenSigSwitchedByIgnition" SG_ 1411 FBS_Warn_Schluessel_Batt 0;
BA_ "GenSigActiveRepetitions" SG_ 1411 FFB_CarFinder 5;
BA_ "GenSigSendType" SG_ 1411 FFB_CarFinder 2;
BA_ "GenSigSwitchedByIgnition" SG_ 1411 FFB_CarFinder 0;
BA_ "GenSigActiveRepetitions" SG_ 1411 FFB_Komfortoeffnen 5;
BA_ "GenSigSendType" SG_ 1411 FFB_Komfortoeffnen 2;
BA_ "GenSigSwitchedByIgnition" SG_ 1411 FFB_Komfortoeffnen 0;
BA_ "GenSigActiveRepetitions" SG_ 1411 FFB_Komfortschliessen 5;
BA_ "GenSigSendType" SG_ 1411 FFB_Komfortschliessen 2;
BA_ "GenSigSwitchedByIgnition" SG_ 1411 FFB_Komfortschliessen 0;
BA_ "GenSigSendType" SG_ 1411 HBFS_gesafet 3;
BA_ "GenSigSwitchedByIgnition" SG_ 1411 HBFS_gesafet 0;
BA_ "GenSigSendType" SG_ 1411 HBFS_verriegelt 3;
BA_ "GenSigSwitchedByIgnition" SG_ 1411 HBFS_verriegelt 0;
BA_ "GenSigSendType" SG_ 1411 HD_Hauptraste 3;
BA_ "GenSigSwitchedByIgnition" SG_ 1411 HD_Hauptraste 0;
BA_ "GenSigSendType" SG_ 1411 HD_Vorraste 3;
BA_ "GenSigSwitchedByIgnition" SG_ 1411 HD_Vorraste 0;
BA_ "GenSigSendType" SG_ 1411 HFS_gesafet 3;
BA_ "GenSigSwitchedByIgnition" SG_ 1411 HFS_gesafet 0;
BA_ "GenSigSendType" SG_ 1411 HFS_verriegelt 3;
BA_ "GenSigSwitchedByIgnition" SG_ 1411 HFS_verriegelt 0;
BA_ "GenSigSendType" SG_ 1411 IRUE_aktiv 3;
BA_ "GenSigSwitchedByIgnition" SG_ 1411 IRUE_aktiv 0;
BA_ "GenSigSendType" SG_ 1411 IRUE_Taster_Fkts_LED 3;
BA_ "GenSigSwitchedByIgnition" SG_ 1411 IRUE_Taster_Fkts_LED 0;
BA_ "GenSigSendType" SG_ 1411 ZV_BT_offen 3;
BA_ "GenSigSwitchedByIgnition" SG_ 1411 ZV_BT_offen 0;
BA_ "GenSigSendType" SG_ 1411 ZV_Einzeltuerentriegelung 3;
BA_ "GenSigSwitchedByIgnition" SG_ 1411 ZV_Einzeltuerentriegelung 0;
BA_ "GenSigSendType" SG_ 1411 ZV_FT_offen 3;
BA_ "GenSigSwitchedByIgnition" SG_ 1411 ZV_FT_offen 0;
BA_ "GenSigSendType" SG_ 1411 ZV_gesafet_extern_ist 3;
BA_ "GenSigSwitchedByIgnition" SG_ 1411 ZV_gesafet_extern_ist 0;
BA_ "GenSigSendType" SG_ 1411 ZV_gesafet_extern_soll 3;
BA_ "GenSigSwitchedByIgnition" SG_ 1411 ZV_gesafet_extern_soll 0;
BA_ "GenSigSendType" SG_ 1411 ZV_HBFS_offen 3;
BA_ "GenSigSwitchedByIgnition" SG_ 1411 ZV_HBFS_offen 0;
BA_ "GenSigSendType" SG_ 1411 ZV_HD_offen 3;
BA_ "GenSigSwitchedByIgnition" SG_ 1411 ZV_HD_offen 0;
BA_ "GenSigSendType" SG_ 1411 ZV_Heckeinzelentriegelung 3;
BA_ "GenSigSwitchedByIgnition" SG_ 1411 ZV_Heckeinzelentriegelung 0;
BA_ "GenSigSendType" SG_ 1411 ZV_HFS_offen 3;
BA_ "GenSigSwitchedByIgnition" SG_ 1411 ZV_HFS_offen 0;
BA_ "GenSigSendType" SG_ 1411 ZV_HS_offen 3;
BA_ "GenSigSwitchedByIgnition" SG_ 1411 ZV_HS_offen 0;
BA_ "GenSigSendType" SG_ 1411 ZV_ist_Zustand_verfuegbar 3;
BA_ "GenSigSwitchedByIgnition" SG_ 1411 ZV_ist_Zustand_verfuegbar 0;
BA_ "GenSigSendType" SG_ 1411 ZV_Oeffnungsmodus 3;
BA_ "GenSigSwitchedByIgnition" SG_ 1411 ZV_Oeffnungsmodus 0;
BA_ "GenSigSendType" SG_ 1411 ZV_Rollo_auf 3;
BA_ "GenSigSwitchedByIgnition" SG_ 1411 ZV_Rollo_auf 0;
BA_ "GenSigSendType" SG_ 1411 ZV_Rollo_zu 3;
BA_ "GenSigSwitchedByIgnition" SG_ 1411 ZV_Rollo_zu 0;
BA_ "GenSigSendType" SG_ 1411 ZV_SAD_auf 3;
BA_ "GenSigSwitchedByIgnition" SG_ 1411 ZV_SAD_auf 0;
BA_ "GenSigSendType" SG_ 1411 ZV_SAD_zu 3;
BA_ "GenSigSwitchedByIgnition" SG_ 1411 ZV_SAD_zu 0;
BA_ "GenSigSendType" SG_ 1411 ZV_SafeFunktion_aktiv 3;
BA_ "GenSigSwitchedByIgnition" SG_ 1411 ZV_SafeFunktion_aktiv 0;
BA_ "GenSigActiveRepetitions" SG_ 1411 ZV_Schluessel_Zugang 5;
BA_ "GenSigSendType" SG_ 1411 ZV_Schluessel_Zugang 4;
BA_ "GenSigSwitchedByIgnition" SG_ 1411 ZV_Schluessel_Zugang 0;
BA_ "GenSigSendType" SG_ 1411 ZV_Tankklappe_offen 0;
BA_ "GenSigSwitchedByIgnition" SG_ 1411 ZV_Tankklappe_offen 0;
BA_ "GenSigSendType" SG_ 1411 ZV_verriegelt_extern_ist 3;
BA_ "GenSigSwitchedByIgnition" SG_ 1411 ZV_verriegelt_extern_ist 0;
BA_ "GenSigSendType" SG_ 1411 ZV_verriegelt_extern_soll 3;
BA_ "GenSigSwitchedByIgnition" SG_ 1411 ZV_verriegelt_extern_soll 0;
BA_ "GenSigSendType" SG_ 1411 ZV_verriegelt_intern_ist 3;
BA_ "GenSigSwitchedByIgnition" SG_ 1411 ZV_verriegelt_intern_ist 0;
BA_ "GenSigSendType" SG_ 1411 ZV_verriegelt_intern_soll 3;
BA_ "GenSigSwitchedByIgnition" SG_ 1411 ZV_verriegelt_intern_soll 0;
BA_ "GenSigSendType" SG_ 1411 ZV_verriegelt_soll 3;
BA_ "GenSigSwitchedByIgnition" SG_ 1411 ZV_verriegelt_soll 0;
BA_REL_ "GenSigTimeoutTime" BU_SG_REL_ Gateway SG_ 1718 UH_Typ 5000;
BA_REL_ "GenSigTimeoutTime" BU_SG_REL_ Gateway SG_ 1718 UH_DLS 5000;
BA_REL_ "GenSigTimeoutTime" BU_SG_REL_ Gateway SG_ 1718 UH_Monat 5000;
BA_REL_ "GenSigTimeoutTime" BU_SG_REL_ Gateway SG_ 1718 UH_Jahr 5000;
BA_REL_ "GenSigTimeoutTime" BU_SG_REL_ Gateway SG_ 1718 UH_Tag 5000;
BA_REL_ "GenSigTimeoutTime" BU_SG_REL_ Gateway SG_ 1718 UH_Stunde 5000;
BA_REL_ "GenSigTimeoutTime" BU_SG_REL_ Gateway SG_ 1718 UH_Minute 5000;
BA_REL_ "GenSigTimeoutTime" BU_SG_REL_ Gateway SG_ 1718 UH_Sekunde 5000;
BA_REL_ "GenSigTimeoutTime" BU_SG_REL_ Gateway_PAG SG_ 1718 UH_Typ 5000;
BA_REL_ "GenSigTimeoutTime" BU_SG_REL_ Gateway_PAG SG_ 1718 UH_DLS 5000;
BA_REL_ "GenSigTimeoutTime" BU_SG_REL_ Gateway_PAG SG_ 1718 UH_Monat 5000;
BA_REL_ "GenSigTimeoutTime" BU_SG_REL_ Gateway_PAG SG_ 1718 UH_Jahr 5000;
BA_REL_ "GenSigTimeoutTime" BU_SG_REL_ Gateway_PAG SG_ 1718 UH_Tag 5000;
BA_REL_ "GenSigTimeoutTime" BU_SG_REL_ Gateway_PAG SG_ 1718 UH_Stunde 5000;
BA_REL_ "GenSigTimeoutTime" BU_SG_REL_ Gateway_PAG SG_ 1718 UH_Minute 5000;
BA_REL_ "GenSigTimeoutTime" BU_SG_REL_ Gateway_PAG SG_ 1718 UH_Sekunde 5000;
BA_REL_ "GenSigTimeoutTime" BU_SG_REL_ HUD SG_ 798 TSK_Wunschgeschw 500;
BA_REL_ "GenSigTimeoutTime" BU_SG_REL_ HUD SG_ 798 TSK_praediktiver_Hinweis 500;
BA_REL_ "GenSigTimeoutTime" BU_SG_REL_ HUD SG_ 798 TSK_naechstes_Event 500;
BA_REL_ "GenSigTimeoutTime" BU_SG_REL_ HUD SG_ 798 TSK_Fahrzeugstatus_praed_Fkt 500;
BA_REL_ "GenSigTimeoutTime" BU_SG_REL_ HUD SG_ 798 TSK_praediktiver_Automode 500;
BA_REL_ "GenSigTimeoutTime" BU_SG_REL_ HUD SG_ 798 TSK_Texte_Primaeranz 500;
BA_REL_ "GenSigTimeoutTime" BU_SG_REL_ HUD SG_ 798 TSK_Limiter_Fahrerinfo 500;
BA_REL_ "GenSigTimeoutTime" BU_SG_REL_ HUD SG_ 798 TSK_Limiter_Anzeige 500;
BA_REL_ "GenSigTimeoutTime" BU_SG_REL_ HUD SG_ 798 TSK_Status_Anzeige 500;
BA_REL_ "GenSigTimeoutTime" BU_SG_REL_ HUD SG_ 563 TSK_praed_Wunschgeschw 500;
BA_REL_ "GenSigTimeoutTime" BU_SG_REL_ HUD SG_ 385 VZE_Anzeigemodus 2000;
BA_REL_ "GenSigTimeoutTime" BU_SG_REL_ HUD SG_ 385 VZE_Modus_OptischeWarnung 2000;
BA_REL_ "GenSigTimeoutTime" BU_SG_REL_ HUD SG_ 385 VZE_Verkehrszeichen_Einheit 2000;
BA_REL_ "GenSigTimeoutTime" BU_SG_REL_ HUD SG_ 385 VZE_Anzeigeunterdrueck_Zeichen_3 2000;
BA_REL_ "GenSigTimeoutTime" BU_SG_REL_ HUD SG_ 385 VZE_Anzeigeunterdrueck_Zeichen_2 2000;
BA_REL_ "GenSigTimeoutTime" BU_SG_REL_ HUD SG_ 385 VZE_Verkehrszeichen_1 2000;
BA_REL_ "GenSigTimeoutTime" BU_SG_REL_ HUD SG_ 385 VZE_Verkehrszeichen_2 2000;
BA_REL_ "GenSigTimeoutTime" BU_SG_REL_ HUD SG_ 385 VZE_Verkehrszeichen_3 2000;
BA_REL_ "GenSigTimeoutTime" BU_SG_REL_ HUD SG_ 385 VZE_Warnung_Verkehrszeichen_1 2000;
BA_REL_ "GenSigTimeoutTime" BU_SG_REL_ HUD SG_ 385 VZE_Warnung_Verkehrszeichen_2 2000;
BA_REL_ "GenSigTimeoutTime" BU_SG_REL_ HUD SG_ 385 VZE_Warnung_Verkehrszeichen_3 2000;
BA_REL_ "GenSigTimeoutTime" BU_SG_REL_ HUD SG_ 385 VZE_Zusatzschild_1 2000;
BA_REL_ "GenSigTimeoutTime" BU_SG_REL_ HUD SG_ 385 VZE_Zusatzschild_2 2000;
BA_REL_ "GenSigTimeoutTime" BU_SG_REL_ HUD SG_ 385 VZE_Zusatzschild_3 2000;
BA_REL_ "GenSigTimeoutTime" BU_SG_REL_ HUD SG_ 385 VZE_Anzeigeunterdrueck_Zeichen_1 2000;
BA_REL_ "GenSigTimeoutTime" BU_SG_REL_ HUD SG_ 668 VZE_Anzeigeunterdrueck_Zeichen_5 2000;
BA_REL_ "GenSigTimeoutTime" BU_SG_REL_ HUD SG_ 668 VZE_Verkehrszeichen_4 2000;
BA_REL_ "GenSigTimeoutTime" BU_SG_REL_ HUD SG_ 668 VZE_Verkehrszeichen_5 2000;
BA_REL_ "GenSigTimeoutTime" BU_SG_REL_ HUD SG_ 668 VZE_Warnung_Verkehrszeichen_4 2000;
BA_REL_ "GenSigTimeoutTime" BU_SG_REL_ HUD SG_ 668 VZE_Warnung_Verkehrszeichen_5 2000;
BA_REL_ "GenSigTimeoutTime" BU_SG_REL_ HUD SG_ 668 VZE_Zusatzschild_4 2000;
BA_REL_ "GenSigTimeoutTime" BU_SG_REL_ HUD SG_ 668 VZE_Zusatzschild_5 2000;
BA_REL_ "GenSigTimeoutTime" BU_SG_REL_ HUD SG_ 668 VZE_Anzeigeunterdrueck_Zeichen_4 2000;
BA_REL_ "GenSigTimeoutTime" BU_SG_REL_ HUD SG_ 2463978672 VZE_FoD_Status 2000;
BA_REL_ "GenSigTimeoutTime" BU_SG_REL_ HUD SG_ 2463978672 VZE_Anzeige_ZS_1 2000;
BA_REL_ "GenSigTimeoutTime" BU_SG_REL_ HUD SG_ 2463978672 VZE_Anzeige_ZS_2 2000;
BA_REL_ "GenSigTimeoutTime" BU_SG_REL_ HUD SG_ 2463978672 VZE_Anzeige_ZS_3 2000;
BA_REL_ "GenSigTimeoutTime" BU_SG_REL_ HUD SG_ 2463978672 VZE_Hinweistext_03 2000;
BA_REL_ "GenSigTimeoutTime" BU_SG_REL_ HUD SG_ 2463978672 VZE_Land 2000;
BA_REL_ "GenSigTimeoutTime" BU_SG_REL_ HUD SG_ 2463978672 VZE_Warnung_VZ_1 2000;
BA_REL_ "GenSigTimeoutTime" BU_SG_REL_ HUD SG_ 2463978672 VZE_Warnung_VZ_2 2000;
BA_REL_ "GenSigTimeoutTime" BU_SG_REL_ HUD SG_ 2463978672 VZE_Warnung_VZ_3 2000;
BA_REL_ "GenSigTimeoutTime" BU_SG_REL_ HUD SG_ 2463978672 VZE_Anzeige_VZ_1 2000;
BA_REL_ "GenSigTimeoutTime" BU_SG_REL_ HUD SG_ 2463978672 VZE_Anzeige_VZ_2 2000;
BA_REL_ "GenSigTimeoutTime" BU_SG_REL_ HUD SG_ 2463978672 VZE_Anzeige_VZ_3 2000;
BA_REL_ "GenSigTimeoutTime" BU_SG_REL_ HUD SG_ 916 WBA_Fahrstufe_02 1600;
BA_REL_ "GenSigTimeoutTime" BU_SG_REL_ HUD SG_ 916 WBA_eing_Gang_02 1600;
BA_REL_ "GenSigTimeoutTime" BU_SG_REL_ HUD SG_ 916 WBA_GE_Texte_02 1600;
BA_REL_ "GenSigTimeoutTime" BU_SG_REL_ HUD SG_ 916 WBA_Blinken 1600;
BA_REL_ "GenSigTimeoutTime" BU_SG_REL_ Kombi SG_ 974 HFS_Tuerschloss_defekt 5000;
BA_REL_ "GenSigTimeoutTime" BU_SG_REL_ Kombi SG_ 974 HFS_Tueroeffnen_Warnung 5000;
BA_REL_ "GenSigTimeoutTime" BU_SG_REL_ Kombi SG_ 974 ASW_Warnung_aktiv_HFS 5000;
BA_REL_ "GenSigTimeoutTime" BU_SG_REL_ Kombi SG_ 288 TSK_Hauptschalter_GRA_ACC 1000;
BA_REL_ "GenSigTimeoutTime" BU_SG_REL_ Kombi SG_ 798 TSK_07_CRC 500;
BA_REL_ "GenSigTimeoutTime" BU_SG_REL_ Kombi SG_ 798 TSK_07_BZ 500;
BA_REL_ "GenSigTimeoutTime" BU_SG_REL_ Kombi SG_ 798 TSK_Wunschgeschw 500;
BA_REL_ "GenSigTimeoutTime" BU_SG_REL_ Kombi SG_ 798 TSK_praediktiver_Hinweis 500;
BA_REL_ "GenSigTimeoutTime" BU_SG_REL_ Kombi SG_ 798 TSK_naechstes_Event 500;
BA_REL_ "GenSigTimeoutTime" BU_SG_REL_ Kombi SG_ 798 TSK_Fahrzeugstatus_praed_Fkt 500;
BA_REL_ "GenSigTimeoutTime" BU_SG_REL_ Kombi SG_ 798 TSK_praediktiver_Automode 500;
BA_REL_ "GenSigTimeoutTime" BU_SG_REL_ Kombi SG_ 798 TSK_Texte 500;
BA_REL_ "GenSigTimeoutTime" BU_SG_REL_ Kombi SG_ 798 TSK_Akustik 500;
BA_REL_ "GenSigTimeoutTime" BU_SG_REL_ Kombi SG_ 798 TSK_Texte_Primaeranz 500;
BA_REL_ "GenSigTimeoutTime" BU_SG_REL_ Kombi SG_ 798 TSK_Limiter_Fahrerinfo 500;
BA_REL_ "GenSigTimeoutTime" BU_SG_REL_ Kombi SG_ 798 TSK_Limiter_Anzeige 500;
BA_REL_ "GenSigTimeoutTime" BU_SG_REL_ Kombi SG_ 798 TSK_Fahrzeugstatus_GRA 500;
BA_REL_ "GenSigTimeoutTime" BU_SG_REL_ Kombi SG_ 798 TSK_Fahrzeugstatus_Limiter 500;
BA_REL_ "GenSigTimeoutTime" BU_SG_REL_ Kombi SG_ 798 MO_Motorlaufwarnung 500;
BA_REL_ "GenSigTimeoutTime" BU_SG_REL_ Kombi SG_ 798 MO_Verlassenswarnung 500;
BA_REL_ "GenSigTimeoutTime" BU_SG_REL_ Kombi SG_ 798 TSK_naechstes_Event_Einheit 500;
BA_REL_ "GenSigTimeoutTime" BU_SG_REL_ Kombi SG_ 798 TSK_Status_Anzeige 500;
BA_REL_ "GenSigTimeoutTime" BU_SG_REL_ Kombi SG_ 563 TSK_praed_Wunschgeschw 500;
BA_REL_ "GenSigTimeoutTime" BU_SG_REL_ Kombi SG_ 618 USS_Fahrer_Texte 5000;
BA_REL_ "GenSigTimeoutTime" BU_SG_REL_ Kombi SG_ 2463978633 VAS_L_01_CRC 1000;
BA_REL_ "GenSigTimeoutTime" BU_SG_REL_ Kombi SG_ 2463978633 VAS_L_01_BZ 1000;
BA_REL_ "GenSigTimeoutTime" BU_SG_REL_ Kombi SG_ 2463978633 VAS_L_Texte 1000;
BA_REL_ "GenSigTimeoutTime" BU_SG_REL_ Kombi SG_ 995 VS_VD_zu_ver 1000;
BA_REL_ "GenSigTimeoutTime" BU_SG_REL_ Kombi SG_ 995 VS_VD_offen_ver 1000;
BA_REL_ "GenSigTimeoutTime" BU_SG_REL_ Kombi SG_ 995 VS_Lampe_Blk 1000;
BA_REL_ "GenSigTimeoutTime" BU_SG_REL_ Kombi SG_ 995 VS_Buzzer 1000;
BA_REL_ "GenSigTimeoutTime" BU_SG_REL_ Kombi SG_ 995 VSG_Meldungen 1000;
BA_REL_ "GenSigTimeoutTime" BU_SG_REL_ Kombi SG_ 1716 VIN_01_MUX 2000;
BA_REL_ "GenSigTimeoutTime" BU_SG_REL_ Kombi SG_ 1716 VIN_4 2000;
BA_REL_ "GenSigTimeoutTime" BU_SG_REL_ Kombi SG_ 1716 VIN_11 2000;
BA_REL_ "GenSigTimeoutTime" BU_SG_REL_ Kombi SG_ 1716 VIN_5 2000;
BA_REL_ "GenSigTimeoutTime" BU_SG_REL_ Kombi SG_ 1716 VIN_12 2000;
BA_REL_ "GenSigTimeoutTime" BU_SG_REL_ Kombi SG_ 1716 VIN_6 2000;
BA_REL_ "GenSigTimeoutTime" BU_SG_REL_ Kombi SG_ 1716 VIN_13 2000;
BA_REL_ "GenSigTimeoutTime" BU_SG_REL_ Kombi SG_ 1716 VIN_7 2000;
BA_REL_ "GenSigTimeoutTime" BU_SG_REL_ Kombi SG_ 1716 VIN_14 2000;
BA_REL_ "GenSigTimeoutTime" BU_SG_REL_ Kombi SG_ 1716 VIN_1 2000;
BA_REL_ "GenSigTimeoutTime" BU_SG_REL_ Kombi SG_ 1716 VIN_8 2000;
BA_REL_ "GenSigTimeoutTime" BU_SG_REL_ Kombi SG_ 1716 VIN_15 2000;
BA_REL_ "GenSigTimeoutTime" BU_SG_REL_ Kombi SG_ 1716 VIN_2 2000;
BA_REL_ "GenSigTimeoutTime" BU_SG_REL_ Kombi SG_ 1716 VIN_9 2000;
BA_REL_ "GenSigTimeoutTime" BU_SG_REL_ Kombi SG_ 1716 VIN_16 2000;
BA_REL_ "GenSigTimeoutTime" BU_SG_REL_ Kombi SG_ 1716 VIN_3 2000;
BA_REL_ "GenSigTimeoutTime" BU_SG_REL_ Kombi SG_ 1716 VIN_10 2000;
BA_REL_ "GenSigTimeoutTime" BU_SG_REL_ Kombi SG_ 1716 VIN_17 2000;
BA_REL_ "GenSigTimeoutTime" BU_SG_REL_ Kombi SG_ 385 VZE_Anzeigemodus 2000;
BA_REL_ "GenSigTimeoutTime" BU_SG_REL_ Kombi SG_ 385 VZE_Hinweistext 2000;
BA_REL_ "GenSigTimeoutTime" BU_SG_REL_ Kombi SG_ 385 VZE_Akustik_Limitwechsel 2000;
BA_REL_ "GenSigTimeoutTime" BU_SG_REL_ Kombi SG_ 385 VZE_Modus_OptischeWarnung 2000;
BA_REL_ "GenSigTimeoutTime" BU_SG_REL_ Kombi SG_ 385 VZE_Anzeigeunterdrueck_Zeichen_3 2000;
BA_REL_ "GenSigTimeoutTime" BU_SG_REL_ Kombi SG_ 385 VZE_Anzeigeunterdrueck_Zeichen_2 2000;
BA_REL_ "GenSigTimeoutTime" BU_SG_REL_ Kombi SG_ 385 VZE_Verkehrszeichen_1 2000;
BA_REL_ "GenSigTimeoutTime" BU_SG_REL_ Kombi SG_ 385 VZE_Verkehrszeichen_2 2000;
BA_REL_ "GenSigTimeoutTime" BU_SG_REL_ Kombi SG_ 385 VZE_Verkehrszeichen_3 2000;
BA_REL_ "GenSigTimeoutTime" BU_SG_REL_ Kombi SG_ 385 VZE_Warnung_Verkehrszeichen_1 2000;
BA_REL_ "GenSigTimeoutTime" BU_SG_REL_ Kombi SG_ 385 VZE_Warnung_Verkehrszeichen_2 2000;
BA_REL_ "GenSigTimeoutTime" BU_SG_REL_ Kombi SG_ 385 VZE_Warnung_Verkehrszeichen_3 2000;
BA_REL_ "GenSigTimeoutTime" BU_SG_REL_ Kombi SG_ 385 VZE_Zusatzschild_1 2000;
BA_REL_ "GenSigTimeoutTime" BU_SG_REL_ Kombi SG_ 385 VZE_Zusatzschild_2 2000;
BA_REL_ "GenSigTimeoutTime" BU_SG_REL_ Kombi SG_ 385 VZE_Zusatzschild_3 2000;
BA_REL_ "GenSigTimeoutTime" BU_SG_REL_ Kombi SG_ 385 VZE_Anzeigeunterdrueck_Zeichen_1 2000;
BA_REL_ "GenSigTimeoutTime" BU_SG_REL_ Kombi SG_ 385 VZE_Gong 2000;
BA_REL_ "GenSigTimeoutTime" BU_SG_REL_ Kombi SG_ 668 VZE_SLWF_Status 2000;
BA_REL_ "GenSigTimeoutTime" BU_SG_REL_ Kombi SG_ 668 VZE_Anzeigeunterdrueck_Zeichen_5 2000;
BA_REL_ "GenSigTimeoutTime" BU_SG_REL_ Kombi SG_ 668 VZE_Verkehrszeichen_4 2000;
BA_REL_ "GenSigTimeoutTime" BU_SG_REL_ Kombi SG_ 668 VZE_Verkehrszeichen_5 2000;
BA_REL_ "GenSigTimeoutTime" BU_SG_REL_ Kombi SG_ 668 VZE_Warnung_Verkehrszeichen_4 2000;
BA_REL_ "GenSigTimeoutTime" BU_SG_REL_ Kombi SG_ 668 VZE_Warnung_Verkehrszeichen_5 2000;
BA_REL_ "GenSigTimeoutTime" BU_SG_REL_ Kombi SG_ 668 VZE_Zusatzschild_4 2000;
BA_REL_ "GenSigTimeoutTime" BU_SG_REL_ Kombi SG_ 668 VZE_Zusatzschild_5 2000;
BA_REL_ "GenSigTimeoutTime" BU_SG_REL_ Kombi SG_ 668 VZE_Anzeigeunterdrueck_Zeichen_4 2000;
BA_REL_ "GenSigTimeoutTime" BU_SG_REL_ Kombi SG_ 2463978672 VZE_FoD_Status 2000;
BA_REL_ "GenSigTimeoutTime" BU_SG_REL_ Kombi SG_ 2463978672 VZE_Anzeige_ZS_1 2000;
BA_REL_ "GenSigTimeoutTime" BU_SG_REL_ Kombi SG_ 2463978672 VZE_Anzeige_ZS_2 2000;
BA_REL_ "GenSigTimeoutTime" BU_SG_REL_ Kombi SG_ 2463978672 VZE_Anzeige_ZS_3 2000;
BA_REL_ "GenSigTimeoutTime" BU_SG_REL_ Kombi SG_ 2463978672 VZE_Hinweistext_03 2000;
BA_REL_ "GenSigTimeoutTime" BU_SG_REL_ Kombi SG_ 2463978672 VZE_Land 2000;
BA_REL_ "GenSigTimeoutTime" BU_SG_REL_ Kombi SG_ 2463978672 VZE_Warnung_VZ_1 2000;
BA_REL_ "GenSigTimeoutTime" BU_SG_REL_ Kombi SG_ 2463978672 VZE_Warnung_VZ_2 2000;
BA_REL_ "GenSigTimeoutTime" BU_SG_REL_ Kombi SG_ 2463978672 VZE_Warnung_VZ_3 2000;
BA_REL_ "GenSigTimeoutTime" BU_SG_REL_ Kombi SG_ 2463978672 VZE_Anzeige_VZ_1 2000;
BA_REL_ "GenSigTimeoutTime" BU_SG_REL_ Kombi SG_ 2463978672 VZE_Anzeige_VZ_2 2000;
BA_REL_ "GenSigTimeoutTime" BU_SG_REL_ Kombi SG_ 2463978672 VZE_Anzeige_VZ_3 2000;
BA_REL_ "GenSigTimeoutTime" BU_SG_REL_ Kombi SG_ 181 WH_Variante 500;
BA_REL_ "GenSigTimeoutTime" BU_SG_REL_ Kombi SG_ 2589283476 WH_Warnung_02 5000;
BA_REL_ "GenSigTimeoutTime" BU_SG_REL_ Kombi SG_ 2589283476 WH_Warnung_03 5000;
BA_REL_ "GenSigTimeoutTime" BU_SG_REL_ Kombi SG_ 916 WBA_03_CRC 1600;
BA_REL_ "GenSigTimeoutTime" BU_SG_REL_ Kombi SG_ 916 WBA_03_BZ 1600;
BA_REL_ "GenSigTimeoutTime" BU_SG_REL_ Kombi SG_ 916 WBA_Fahrstufe_02 1600;
BA_REL_ "GenSigTimeoutTime" BU_SG_REL_ Kombi SG_ 916 WBA_GE_Warnung_02 1600;
BA_REL_ "GenSigTimeoutTime" BU_SG_REL_ Kombi SG_ 916 WBA_eing_Gang_02 1600;
BA_REL_ "GenSigTimeoutTime" BU_SG_REL_ Kombi SG_ 916 WBA_GE_Texte 1600;
BA_REL_ "GenSigTimeoutTime" BU_SG_REL_ Kombi SG_ 916 WBA_Segeln_aktiv 1600;
BA_REL_ "GenSigTimeoutTime" BU_SG_REL_ Kombi SG_ 916 WBA_GE_Zusatzwarnungen 1600;
BA_REL_ "GenSigTimeoutTime" BU_SG_REL_ Kombi SG_ 916 GE_Sollgang 1600;
BA_REL_ "GenSigTimeoutTime" BU_SG_REL_ Kombi SG_ 916 GE_Tipschaltempf_verfuegbar 1600;
BA_REL_ "GenSigTimeoutTime" BU_SG_REL_ Kombi SG_ 916 WBA_GE_Texte_02 1600;
BA_REL_ "GenSigTimeoutTime" BU_SG_REL_ Kombi SG_ 916 WBA_Blinken 1600;
BA_REL_ "GenSigTimeoutTime" BU_SG_REL_ Kombi SG_ 2527679839 WCU_StTankWa 5000;
BA_REL_ "GenSigTimeoutTime" BU_SG_REL_ Kombi SG_ 2527679839 WCU_VolWaRefill 5000;
BA_REL_ "GenSigTimeoutTime" BU_SG_REL_ Kombi SG_ 2527679839 WCU_VolWaRem 5000;
BA_REL_ "GenSigTimeoutTime" BU_SG_REL_ Kombi SG_ 2527679839 WCU_VolWaRemRaw 5000;
BA_REL_ "GenSigTimeoutTime" BU_SG_REL_ Kombi SG_ 2527679839 WCU_PrctVolWaRem 5000;
BA_REL_ "GenSigTimeoutTime" BU_SG_REL_ Kombi SG_ 1361 WFS_Schluessel_Soll 2000;
BA_REL_ "GenSigTimeoutTime" BU_SG_REL_ Kombi SG_ 1361 WFS_Schluessel_Ist 2000;
BA_REL_ "GenSigTimeoutTime" BU_SG_REL_ Kombi SG_ 1361 WFS_Safe 2000;
BA_REL_ "GenSigTimeoutTime" BU_SG_REL_ Kombi SG_ 1361 WFS_LZ 2000;
BA_REL_ "GenSigTimeoutTime" BU_SG_REL_ Kombi SG_ 1361 WFS_Fahrerhinweise 2000;
BA_REL_ "GenSigTimeoutTime" BU_SG_REL_ Kombi SG_ 1702 Wischer_vorne_defekt 5000;
BA_REL_ "GenSigTimeoutTime" BU_SG_REL_ Kombi SG_ 1702 Wischer_Anzeigetext 5000;
BA_REL_ "GenSigTimeoutTime" BU_SG_REL_ Kombi SG_ 2527679496 WIV_Verschleissindex_02 3200;
BA_REL_ "GenSigTimeoutTime" BU_SG_REL_ Kombi SG_ 2527679496 WIV_Verschleissindex_Ueberlauf 3200;
BA_REL_ "GenSigTimeoutTime" BU_SG_REL_ Kombi SG_ 2527679496 WIV_Russindex_02 3200;
BA_REL_ "GenSigTimeoutTime" BU_SG_REL_ Kombi SG_ 2527679496 WIV_Russindex_Ueberlauf 3200;
BA_REL_ "GenSigTimeoutTime" BU_SG_REL_ Kombi SG_ 2527679496 WIV_t_min 3200;
BA_REL_ "GenSigTimeoutTime" BU_SG_REL_ Kombi SG_ 2527679496 WIV_t_max 3200;
BA_REL_ "GenSigTimeoutTime" BU_SG_REL_ Kombi SG_ 2527679496 WIV_W_min 3200;
BA_REL_ "GenSigTimeoutTime" BU_SG_REL_ Kombi SG_ 2527679496 WIV_W_max 3200;
BA_REL_ "GenSigTimeoutTime" BU_SG_REL_ Kombi SG_ 2527679655 MMI_StartupAnimation 5000;
BA_REL_ "GenSigTimeoutTime" BU_SG_REL_ Kombi SG_ 1411 ZV_verriegelt_extern_ist 2000;
BA_REL_ "GenSigTimeoutTime" BU_SG_REL_ Kombi SG_ 1411 ZV_FT_offen 2000;
BA_REL_ "GenSigTimeoutTime" BU_SG_REL_ Kombi SG_ 1411 ZV_BT_offen 2000;
BA_REL_ "GenSigTimeoutTime" BU_SG_REL_ Kombi SG_ 1411 ZV_HFS_offen 2000;
BA_REL_ "GenSigTimeoutTime" BU_SG_REL_ Kombi SG_ 1411 ZV_HBFS_offen 2000;
BA_REL_ "GenSigTimeoutTime" BU_SG_REL_ Kombi SG_ 1411 ZV_HD_offen 2000;
BA_REL_ "GenSigTimeoutTime" BU_SG_REL_ Kombi SG_ 1411 ZV_SafeFunktion_aktiv 2000;
BA_REL_ "GenSigTimeoutTime" BU_SG_REL_ Kombi SG_ 1411 ZV_Tankklappe_offen 2000;
BA_REL_ "GenSigTimeoutTime" BU_SG_REL_ Kombi_LB SG_ 974 HFS_Tuerschloss_defekt 5000;
BA_REL_ "GenSigTimeoutTime" BU_SG_REL_ Kombi_LB SG_ 974 HFS_Tueroeffnen_Warnung 5000;
BA_REL_ "GenSigTimeoutTime" BU_SG_REL_ Kombi_LB SG_ 974 ASW_Warnung_aktiv_HFS 5000;
BA_REL_ "GenSigTimeoutTime" BU_SG_REL_ Kombi_LB SG_ 288 TSK_Hauptschalter_GRA_ACC 1000;
BA_REL_ "GenSigTimeoutTime" BU_SG_REL_ Kombi_LB SG_ 798 TSK_07_CRC 500;
BA_REL_ "GenSigTimeoutTime" BU_SG_REL_ Kombi_LB SG_ 798 TSK_07_BZ 500;
BA_REL_ "GenSigTimeoutTime" BU_SG_REL_ Kombi_LB SG_ 798 TSK_Wunschgeschw 500;
BA_REL_ "GenSigTimeoutTime" BU_SG_REL_ Kombi_LB SG_ 798 TSK_Texte 500;
BA_REL_ "GenSigTimeoutTime" BU_SG_REL_ Kombi_LB SG_ 798 TSK_Akustik 500;
BA_REL_ "GenSigTimeoutTime" BU_SG_REL_ Kombi_LB SG_ 798 TSK_Texte_Primaeranz 500;
BA_REL_ "GenSigTimeoutTime" BU_SG_REL_ Kombi_LB SG_ 798 TSK_Limiter_Fahrerinfo 500;
BA_REL_ "GenSigTimeoutTime" BU_SG_REL_ Kombi_LB SG_ 798 TSK_Limiter_Anzeige 500;
BA_REL_ "GenSigTimeoutTime" BU_SG_REL_ Kombi_LB SG_ 798 TSK_Fahrzeugstatus_GRA 500;
BA_REL_ "GenSigTimeoutTime" BU_SG_REL_ Kombi_LB SG_ 798 TSK_Fahrzeugstatus_Limiter 500;
BA_REL_ "GenSigTimeoutTime" BU_SG_REL_ Kombi_LB SG_ 798 MO_Motorlaufwarnung 500;
BA_REL_ "GenSigTimeoutTime" BU_SG_REL_ Kombi_LB SG_ 798 MO_Verlassenswarnung 500;
BA_REL_ "GenSigTimeoutTime" BU_SG_REL_ Kombi_LB SG_ 798 TSK_Status_Anzeige 500;
BA_REL_ "GenSigTimeoutTime" BU_SG_REL_ Kombi_LB SG_ 618 USS_Fahrer_Texte 5000;
BA_REL_ "GenSigTimeoutTime" BU_SG_REL_ Kombi_LB SG_ 2463978633 VAS_L_01_CRC 1000;
BA_REL_ "GenSigTimeoutTime" BU_SG_REL_ Kombi_LB SG_ 2463978633 VAS_L_01_BZ 1000;
BA_REL_ "GenSigTimeoutTime" BU_SG_REL_ Kombi_LB SG_ 1716 VIN_01_MUX 2000;
BA_REL_ "GenSigTimeoutTime" BU_SG_REL_ Kombi_LB SG_ 1716 VIN_1 2000;
BA_REL_ "GenSigTimeoutTime" BU_SG_REL_ Kombi_LB SG_ 1716 VIN_2 2000;
BA_REL_ "GenSigTimeoutTime" BU_SG_REL_ Kombi_LB SG_ 1716 VIN_3 2000;
BA_REL_ "GenSigTimeoutTime" BU_SG_REL_ Kombi_LB SG_ 385 VZE_Anzeigemodus 2000;
BA_REL_ "GenSigTimeoutTime" BU_SG_REL_ Kombi_LB SG_ 385 VZE_Hinweistext 2000;
BA_REL_ "GenSigTimeoutTime" BU_SG_REL_ Kombi_LB SG_ 385 VZE_Akustik_Limitwechsel 2000;
BA_REL_ "GenSigTimeoutTime" BU_SG_REL_ Kombi_LB SG_ 385 VZE_Modus_OptischeWarnung 2000;
BA_REL_ "GenSigTimeoutTime" BU_SG_REL_ Kombi_LB SG_ 385 VZE_Anzeigeunterdrueck_Zeichen_3 2000;
BA_REL_ "GenSigTimeoutTime" BU_SG_REL_ Kombi_LB SG_ 385 VZE_Anzeigeunterdrueck_Zeichen_2 2000;
BA_REL_ "GenSigTimeoutTime" BU_SG_REL_ Kombi_LB SG_ 385 VZE_Verkehrszeichen_1 2000;
BA_REL_ "GenSigTimeoutTime" BU_SG_REL_ Kombi_LB SG_ 385 VZE_Verkehrszeichen_2 2000;
BA_REL_ "GenSigTimeoutTime" BU_SG_REL_ Kombi_LB SG_ 385 VZE_Verkehrszeichen_3 2000;
BA_REL_ "GenSigTimeoutTime" BU_SG_REL_ Kombi_LB SG_ 385 VZE_Warnung_Verkehrszeichen_1 2000;
BA_REL_ "GenSigTimeoutTime" BU_SG_REL_ Kombi_LB SG_ 385 VZE_Warnung_Verkehrszeichen_2 2000;
BA_REL_ "GenSigTimeoutTime" BU_SG_REL_ Kombi_LB SG_ 385 VZE_Warnung_Verkehrszeichen_3 2000;
BA_REL_ "GenSigTimeoutTime" BU_SG_REL_ Kombi_LB SG_ 385 VZE_Zusatzschild_1 2000;
BA_REL_ "GenSigTimeoutTime" BU_SG_REL_ Kombi_LB SG_ 385 VZE_Zusatzschild_2 2000;
BA_REL_ "GenSigTimeoutTime" BU_SG_REL_ Kombi_LB SG_ 385 VZE_Zusatzschild_3 2000;
BA_REL_ "GenSigTimeoutTime" BU_SG_REL_ Kombi_LB SG_ 385 VZE_Anzeigeunterdrueck_Zeichen_1 2000;
BA_REL_ "GenSigTimeoutTime" BU_SG_REL_ Kombi_LB SG_ 385 VZE_Gong 2000;
BA_REL_ "GenSigTimeoutTime" BU_SG_REL_ Kombi_LB SG_ 668 VZE_SLWF_Status 2000;
BA_REL_ "GenSigTimeoutTime" BU_SG_REL_ Kombi_LB SG_ 668 VZE_Anzeigeunterdrueck_Zeichen_5 2000;
BA_REL_ "GenSigTimeoutTime" BU_SG_REL_ Kombi_LB SG_ 668 VZE_Verkehrszeichen_4 2000;
BA_REL_ "GenSigTimeoutTime" BU_SG_REL_ Kombi_LB SG_ 668 VZE_Verkehrszeichen_5 2000;
BA_REL_ "GenSigTimeoutTime" BU_SG_REL_ Kombi_LB SG_ 668 VZE_Warnung_Verkehrszeichen_4 2000;
BA_REL_ "GenSigTimeoutTime" BU_SG_REL_ Kombi_LB SG_ 668 VZE_Warnung_Verkehrszeichen_5 2000;
BA_REL_ "GenSigTimeoutTime" BU_SG_REL_ Kombi_LB SG_ 668 VZE_Zusatzschild_4 2000;
BA_REL_ "GenSigTimeoutTime" BU_SG_REL_ Kombi_LB SG_ 668 VZE_Zusatzschild_5 2000;
BA_REL_ "GenSigTimeoutTime" BU_SG_REL_ Kombi_LB SG_ 668 VZE_Anzeigeunterdrueck_Zeichen_4 2000;
BA_REL_ "GenSigTimeoutTime" BU_SG_REL_ Kombi_LB SG_ 2463978672 VZE_FoD_Status 2000;
BA_REL_ "GenSigTimeoutTime" BU_SG_REL_ Kombi_LB SG_ 2463978672 VZE_Anzeige_ZS_1 2000;
BA_REL_ "GenSigTimeoutTime" BU_SG_REL_ Kombi_LB SG_ 2463978672 VZE_Anzeige_ZS_2 2000;
BA_REL_ "GenSigTimeoutTime" BU_SG_REL_ Kombi_LB SG_ 2463978672 VZE_Anzeige_ZS_3 2000;
BA_REL_ "GenSigTimeoutTime" BU_SG_REL_ Kombi_LB SG_ 2463978672 VZE_Hinweistext_03 2000;
BA_REL_ "GenSigTimeoutTime" BU_SG_REL_ Kombi_LB SG_ 2463978672 VZE_Land 2000;
BA_REL_ "GenSigTimeoutTime" BU_SG_REL_ Kombi_LB SG_ 2463978672 VZE_Warnung_VZ_1 2000;
BA_REL_ "GenSigTimeoutTime" BU_SG_REL_ Kombi_LB SG_ 2463978672 VZE_Warnung_VZ_2 2000;
BA_REL_ "GenSigTimeoutTime" BU_SG_REL_ Kombi_LB SG_ 2463978672 VZE_Warnung_VZ_3 2000;
BA_REL_ "GenSigTimeoutTime" BU_SG_REL_ Kombi_LB SG_ 2463978672 VZE_Anzeige_VZ_1 2000;
BA_REL_ "GenSigTimeoutTime" BU_SG_REL_ Kombi_LB SG_ 2463978672 VZE_Anzeige_VZ_2 2000;
BA_REL_ "GenSigTimeoutTime" BU_SG_REL_ Kombi_LB SG_ 2463978672 VZE_Anzeige_VZ_3 2000;
BA_REL_ "GenSigTimeoutTime" BU_SG_REL_ Kombi_LB SG_ 181 WH_Variante 500;
BA_REL_ "GenSigTimeoutTime" BU_SG_REL_ Kombi_LB SG_ 2589283476 WH_Warnung_02 5000;
BA_REL_ "GenSigTimeoutTime" BU_SG_REL_ Kombi_LB SG_ 2589283476 WH_Warnung_03 5000;
BA_REL_ "GenSigTimeoutTime" BU_SG_REL_ Kombi_LB SG_ 916 WBA_03_CRC 1600;
BA_REL_ "GenSigTimeoutTime" BU_SG_REL_ Kombi_LB SG_ 916 WBA_03_BZ 1600;
BA_REL_ "GenSigTimeoutTime" BU_SG_REL_ Kombi_LB SG_ 916 WBA_Fahrstufe_02 1600;
BA_REL_ "GenSigTimeoutTime" BU_SG_REL_ Kombi_LB SG_ 916 WBA_GE_Warnung_02 1600;
BA_REL_ "GenSigTimeoutTime" BU_SG_REL_ Kombi_LB SG_ 916 WBA_eing_Gang_02 1600;
BA_REL_ "GenSigTimeoutTime" BU_SG_REL_ Kombi_LB SG_ 916 WBA_GE_Texte 1600;
BA_REL_ "GenSigTimeoutTime" BU_SG_REL_ Kombi_LB SG_ 916 WBA_Segeln_aktiv 1600;
BA_REL_ "GenSigTimeoutTime" BU_SG_REL_ Kombi_LB SG_ 916 WBA_GE_Zusatzwarnungen 1600;
BA_REL_ "GenSigTimeoutTime" BU_SG_REL_ Kombi_LB SG_ 916 GE_Sollgang 1600;
BA_REL_ "GenSigTimeoutTime" BU_SG_REL_ Kombi_LB SG_ 916 GE_Tipschaltempf_verfuegbar 1600;
BA_REL_ "GenSigTimeoutTime" BU_SG_REL_ Kombi_LB SG_ 916 WBA_GE_Texte_02 1600;
BA_REL_ "GenSigTimeoutTime" BU_SG_REL_ Kombi_LB SG_ 916 WBA_Blinken 1600;
BA_REL_ "GenSigTimeoutTime" BU_SG_REL_ Kombi_LB SG_ 1361 WFS_Schluessel_Soll 2000;
BA_REL_ "GenSigTimeoutTime" BU_SG_REL_ Kombi_LB SG_ 1361 WFS_Schluessel_Ist 2000;
BA_REL_ "GenSigTimeoutTime" BU_SG_REL_ Kombi_LB SG_ 1361 WFS_Safe 2000;
BA_REL_ "GenSigTimeoutTime" BU_SG_REL_ Kombi_LB SG_ 1361 WFS_LZ 2000;
BA_REL_ "GenSigTimeoutTime" BU_SG_REL_ Kombi_LB SG_ 1361 WFS_Fahrerhinweise 2000;
BA_REL_ "GenSigTimeoutTime" BU_SG_REL_ Kombi_LB SG_ 1702 Wischer_vorne_defekt 5000;
BA_REL_ "GenSigTimeoutTime" BU_SG_REL_ Kombi_LB SG_ 1702 Wischer_Anzeigetext 5000;
BA_REL_ "GenSigTimeoutTime" BU_SG_REL_ Kombi_LB SG_ 2527679496 WIV_Verschleissindex_02 3200;
BA_REL_ "GenSigTimeoutTime" BU_SG_REL_ Kombi_LB SG_ 2527679496 WIV_Verschleissindex_Ueberlauf 3200;
BA_REL_ "GenSigTimeoutTime" BU_SG_REL_ Kombi_LB SG_ 2527679496 WIV_Russindex_02 3200;
BA_REL_ "GenSigTimeoutTime" BU_SG_REL_ Kombi_LB SG_ 2527679496 WIV_Russindex_Ueberlauf 3200;
BA_REL_ "GenSigTimeoutTime" BU_SG_REL_ Kombi_LB SG_ 2527679496 WIV_t_min 3200;
BA_REL_ "GenSigTimeoutTime" BU_SG_REL_ Kombi_LB SG_ 2527679496 WIV_t_max 3200;
BA_REL_ "GenSigTimeoutTime" BU_SG_REL_ Kombi_LB SG_ 2527679496 WIV_W_min 3200;
BA_REL_ "GenSigTimeoutTime" BU_SG_REL_ Kombi_LB SG_ 2527679496 WIV_W_max 3200;
BA_REL_ "GenSigTimeoutTime" BU_SG_REL_ Kombi_LB SG_ 2527679655 MMI_StartupAnimation 5000;
BA_REL_ "GenSigTimeoutTime" BU_SG_REL_ Kombi_LB SG_ 1411 ZV_verriegelt_extern_ist 2000;
BA_REL_ "GenSigTimeoutTime" BU_SG_REL_ Kombi_LB SG_ 1411 ZV_FT_offen 2000;
BA_REL_ "GenSigTimeoutTime" BU_SG_REL_ Kombi_LB SG_ 1411 ZV_BT_offen 2000;
BA_REL_ "GenSigTimeoutTime" BU_SG_REL_ Kombi_LB SG_ 1411 ZV_HFS_offen 2000;
BA_REL_ "GenSigTimeoutTime" BU_SG_REL_ Kombi_LB SG_ 1411 ZV_HBFS_offen 2000;
BA_REL_ "GenSigTimeoutTime" BU_SG_REL_ Kombi_LB SG_ 1411 ZV_HD_offen 2000;
BA_REL_ "GenSigTimeoutTime" BU_SG_REL_ Kombi_LB SG_ 1411 ZV_SafeFunktion_aktiv 2000;
BA_REL_ "GenSigTimeoutTime" BU_SG_REL_ Kombi_LB SG_ 1411 ZV_Tankklappe_offen 2000;
BA_REL_ "GenSigTimeoutTime" BU_SG_REL_ Kombi_PAG SG_ 974 HFS_Tuerschloss_defekt 5000;
BA_REL_ "GenSigTimeoutTime" BU_SG_REL_ Kombi_PAG SG_ 974 HFS_Tuer_Status 5000;
BA_REL_ "GenSigTimeoutTime" BU_SG_REL_ Kombi_PAG SG_ 974 HFS_Tueroeffnen_Warnung 5000;
BA_REL_ "GenSigTimeoutTime" BU_SG_REL_ Kombi_PAG SG_ 974 ASW_Warnung_aktiv_HFS 5000;
BA_REL_ "GenSigTimeoutTime" BU_SG_REL_ Kombi_PAG SG_ 974 HFS_Status_KiSi 5000;
BA_REL_ "GenSigTimeoutTime" BU_SG_REL_ Kombi_PAG SG_ 974 HFS_TCR_Mode_aktiv 5000;
BA_REL_ "GenSigTimeoutTime" BU_SG_REL_ Kombi_PAG SG_ 288 TSK_Hauptschalter_GRA_ACC 1000;
BA_REL_ "GenSigTimeoutTime" BU_SG_REL_ Kombi_PAG SG_ 798 TSK_07_CRC 500;
BA_REL_ "GenSigTimeoutTime" BU_SG_REL_ Kombi_PAG SG_ 798 TSK_07_BZ 500;
BA_REL_ "GenSigTimeoutTime" BU_SG_REL_ Kombi_PAG SG_ 798 TSK_Wunschgeschw 500;
BA_REL_ "GenSigTimeoutTime" BU_SG_REL_ Kombi_PAG SG_ 798 TSK_praediktiver_Hinweis 500;
BA_REL_ "GenSigTimeoutTime" BU_SG_REL_ Kombi_PAG SG_ 798 TSK_naechstes_Event 500;
BA_REL_ "GenSigTimeoutTime" BU_SG_REL_ Kombi_PAG SG_ 798 TSK_Fahrzeugstatus_praed_Fkt 500;
BA_REL_ "GenSigTimeoutTime" BU_SG_REL_ Kombi_PAG SG_ 798 TSK_praediktiver_Automode 500;
BA_REL_ "GenSigTimeoutTime" BU_SG_REL_ Kombi_PAG SG_ 798 TSK_Texte 500;
BA_REL_ "GenSigTimeoutTime" BU_SG_REL_ Kombi_PAG SG_ 798 TSK_Akustik 500;
BA_REL_ "GenSigTimeoutTime" BU_SG_REL_ Kombi_PAG SG_ 798 TSK_Texte_Primaeranz 500;
BA_REL_ "GenSigTimeoutTime" BU_SG_REL_ Kombi_PAG SG_ 798 TSK_Limiter_Fahrerinfo 500;
BA_REL_ "GenSigTimeoutTime" BU_SG_REL_ Kombi_PAG SG_ 798 TSK_Limiter_Anzeige 500;
BA_REL_ "GenSigTimeoutTime" BU_SG_REL_ Kombi_PAG SG_ 798 TSK_Fahrzeugstatus_GRA 500;
BA_REL_ "GenSigTimeoutTime" BU_SG_REL_ Kombi_PAG SG_ 798 TSK_Fahrzeugstatus_Limiter 500;
BA_REL_ "GenSigTimeoutTime" BU_SG_REL_ Kombi_PAG SG_ 798 MO_Motorlaufwarnung 500;
BA_REL_ "GenSigTimeoutTime" BU_SG_REL_ Kombi_PAG SG_ 798 MO_Verlassenswarnung 500;
BA_REL_ "GenSigTimeoutTime" BU_SG_REL_ Kombi_PAG SG_ 798 TSK_naechstes_Event_Einheit 500;
BA_REL_ "GenSigTimeoutTime" BU_SG_REL_ Kombi_PAG SG_ 798 TSK_Status_Anzeige 500;
BA_REL_ "GenSigTimeoutTime" BU_SG_REL_ Kombi_PAG SG_ 563 TSK_praed_Wunschgeschw 500;
BA_REL_ "GenSigTimeoutTime" BU_SG_REL_ Kombi_PAG SG_ 995 VS_VD_zu_ver 1000;
BA_REL_ "GenSigTimeoutTime" BU_SG_REL_ Kombi_PAG SG_ 995 VSG_Meldungen 1000;
BA_REL_ "GenSigTimeoutTime" BU_SG_REL_ Kombi_PAG SG_ 1716 VIN_01_MUX 2000;
BA_REL_ "GenSigTimeoutTime" BU_SG_REL_ Kombi_PAG SG_ 1716 VIN_4 2000;
BA_REL_ "GenSigTimeoutTime" BU_SG_REL_ Kombi_PAG SG_ 1716 VIN_11 2000;
BA_REL_ "GenSigTimeoutTime" BU_SG_REL_ Kombi_PAG SG_ 1716 VIN_5 2000;
BA_REL_ "GenSigTimeoutTime" BU_SG_REL_ Kombi_PAG SG_ 1716 VIN_12 2000;
BA_REL_ "GenSigTimeoutTime" BU_SG_REL_ Kombi_PAG SG_ 1716 VIN_6 2000;
BA_REL_ "GenSigTimeoutTime" BU_SG_REL_ Kombi_PAG SG_ 1716 VIN_13 2000;
BA_REL_ "GenSigTimeoutTime" BU_SG_REL_ Kombi_PAG SG_ 1716 VIN_7 2000;
BA_REL_ "GenSigTimeoutTime" BU_SG_REL_ Kombi_PAG SG_ 1716 VIN_14 2000;
BA_REL_ "GenSigTimeoutTime" BU_SG_REL_ Kombi_PAG SG_ 1716 VIN_1 2000;
BA_REL_ "GenSigTimeoutTime" BU_SG_REL_ Kombi_PAG SG_ 1716 VIN_8 2000;
BA_REL_ "GenSigTimeoutTime" BU_SG_REL_ Kombi_PAG SG_ 1716 VIN_15 2000;
BA_REL_ "GenSigTimeoutTime" BU_SG_REL_ Kombi_PAG SG_ 1716 VIN_2 2000;
BA_REL_ "GenSigTimeoutTime" BU_SG_REL_ Kombi_PAG SG_ 1716 VIN_9 2000;
BA_REL_ "GenSigTimeoutTime" BU_SG_REL_ Kombi_PAG SG_ 1716 VIN_16 2000;
BA_REL_ "GenSigTimeoutTime" BU_SG_REL_ Kombi_PAG SG_ 1716 VIN_3 2000;
BA_REL_ "GenSigTimeoutTime" BU_SG_REL_ Kombi_PAG SG_ 1716 VIN_10 2000;
BA_REL_ "GenSigTimeoutTime" BU_SG_REL_ Kombi_PAG SG_ 1716 VIN_17 2000;
BA_REL_ "GenSigTimeoutTime" BU_SG_REL_ Kombi_PAG SG_ 385 VZE_Anzeigemodus 2000;
BA_REL_ "GenSigTimeoutTime" BU_SG_REL_ Kombi_PAG SG_ 385 VZE_Hinweistext 2000;
BA_REL_ "GenSigTimeoutTime" BU_SG_REL_ Kombi_PAG SG_ 385 VZE_Akustik_Limitwechsel 2000;
BA_REL_ "GenSigTimeoutTime" BU_SG_REL_ Kombi_PAG SG_ 385 VZE_Modus_OptischeWarnung 2000;
BA_REL_ "GenSigTimeoutTime" BU_SG_REL_ Kombi_PAG SG_ 385 VZE_Verkehrszeichen_Einheit 2000;
BA_REL_ "GenSigTimeoutTime" BU_SG_REL_ Kombi_PAG SG_ 385 VZE_Verkehrszeichen_1 2000;
BA_REL_ "GenSigTimeoutTime" BU_SG_REL_ Kombi_PAG SG_ 385 VZE_Verkehrszeichen_2 2000;
BA_REL_ "GenSigTimeoutTime" BU_SG_REL_ Kombi_PAG SG_ 385 VZE_Verkehrszeichen_3 2000;
BA_REL_ "GenSigTimeoutTime" BU_SG_REL_ Kombi_PAG SG_ 385 VZE_Warnung_Verkehrszeichen_1 2000;
BA_REL_ "GenSigTimeoutTime" BU_SG_REL_ Kombi_PAG SG_ 385 VZE_Warnung_Verkehrszeichen_2 2000;
BA_REL_ "GenSigTimeoutTime" BU_SG_REL_ Kombi_PAG SG_ 385 VZE_Warnung_Verkehrszeichen_3 2000;
BA_REL_ "GenSigTimeoutTime" BU_SG_REL_ Kombi_PAG SG_ 385 VZE_Zusatzschild_1 2000;
BA_REL_ "GenSigTimeoutTime" BU_SG_REL_ Kombi_PAG SG_ 385 VZE_Zusatzschild_2 2000;
BA_REL_ "GenSigTimeoutTime" BU_SG_REL_ Kombi_PAG SG_ 385 VZE_Zusatzschild_3 2000;
BA_REL_ "GenSigTimeoutTime" BU_SG_REL_ Kombi_PAG SG_ 385 VZE_Anzeigeunterdrueck_Zeichen_1 2000;
BA_REL_ "GenSigTimeoutTime" BU_SG_REL_ Kombi_PAG SG_ 385 VZE_Gong 2000;
BA_REL_ "GenSigTimeoutTime" BU_SG_REL_ Kombi_PAG SG_ 668 VZE_SLWF_Status 2000;
BA_REL_ "GenSigTimeoutTime" BU_SG_REL_ Kombi_PAG SG_ 668 VZE_Verkehrszeichen_4 2000;
BA_REL_ "GenSigTimeoutTime" BU_SG_REL_ Kombi_PAG SG_ 668 VZE_Verkehrszeichen_5 2000;
BA_REL_ "GenSigTimeoutTime" BU_SG_REL_ Kombi_PAG SG_ 668 VZE_Warnung_Verkehrszeichen_4 2000;
BA_REL_ "GenSigTimeoutTime" BU_SG_REL_ Kombi_PAG SG_ 668 VZE_Warnung_Verkehrszeichen_5 2000;
BA_REL_ "GenSigTimeoutTime" BU_SG_REL_ Kombi_PAG SG_ 668 VZE_Zusatzschild_4 2000;
BA_REL_ "GenSigTimeoutTime" BU_SG_REL_ Kombi_PAG SG_ 668 VZE_Zusatzschild_5 2000;
BA_REL_ "GenSigTimeoutTime" BU_SG_REL_ Kombi_PAG SG_ 2463978672 VZE_FoD_Status 2000;
BA_REL_ "GenSigTimeoutTime" BU_SG_REL_ Kombi_PAG SG_ 2463978672 VZE_Anzeige_ZS_1 2000;
BA_REL_ "GenSigTimeoutTime" BU_SG_REL_ Kombi_PAG SG_ 2463978672 VZE_Anzeige_ZS_2 2000;
BA_REL_ "GenSigTimeoutTime" BU_SG_REL_ Kombi_PAG SG_ 2463978672 VZE_Anzeige_ZS_3 2000;
BA_REL_ "GenSigTimeoutTime" BU_SG_REL_ Kombi_PAG SG_ 2463978672 VZE_Hinweistext_03 2000;
BA_REL_ "GenSigTimeoutTime" BU_SG_REL_ Kombi_PAG SG_ 2463978672 VZE_Land 2000;
BA_REL_ "GenSigTimeoutTime" BU_SG_REL_ Kombi_PAG SG_ 2463978672 VZE_Warnung_VZ_1 2000;
BA_REL_ "GenSigTimeoutTime" BU_SG_REL_ Kombi_PAG SG_ 2463978672 VZE_Warnung_VZ_2 2000;
BA_REL_ "GenSigTimeoutTime" BU_SG_REL_ Kombi_PAG SG_ 2463978672 VZE_Warnung_VZ_3 2000;
BA_REL_ "GenSigTimeoutTime" BU_SG_REL_ Kombi_PAG SG_ 2463978672 VZE_Anzeige_VZ_1 2000;
BA_REL_ "GenSigTimeoutTime" BU_SG_REL_ Kombi_PAG SG_ 2463978672 VZE_Anzeige_VZ_2 2000;
BA_REL_ "GenSigTimeoutTime" BU_SG_REL_ Kombi_PAG SG_ 2463978672 VZE_Anzeige_VZ_3 2000;
BA_REL_ "GenSigTimeoutTime" BU_SG_REL_ Kombi_PAG SG_ 181 WH_gespeicherte_Fahrstufe 500;
BA_REL_ "GenSigTimeoutTime" BU_SG_REL_ Kombi_PAG SG_ 181 WH_Initialisierung 500;
BA_REL_ "GenSigTimeoutTime" BU_SG_REL_ Kombi_PAG SG_ 181 WH_SensorPos_roh 500;
BA_REL_ "GenSigTimeoutTime" BU_SG_REL_ Kombi_PAG SG_ 181 WH_SensorPos_roh_inv 500;
BA_REL_ "GenSigTimeoutTime" BU_SG_REL_ Kombi_PAG SG_ 181 WH_Variante 500;
BA_REL_ "GenSigTimeoutTime" BU_SG_REL_ Kombi_PAG SG_ 2589283476 WH_Warnung_02 5000;
BA_REL_ "GenSigTimeoutTime" BU_SG_REL_ Kombi_PAG SG_ 916 WBA_03_CRC 1600;
BA_REL_ "GenSigTimeoutTime" BU_SG_REL_ Kombi_PAG SG_ 916 WBA_03_BZ 1600;
BA_REL_ "GenSigTimeoutTime" BU_SG_REL_ Kombi_PAG SG_ 916 WBA_Fahrstufe_02 1600;
BA_REL_ "GenSigTimeoutTime" BU_SG_REL_ Kombi_PAG SG_ 916 WBA_GE_Warnung_02 1600;
BA_REL_ "GenSigTimeoutTime" BU_SG_REL_ Kombi_PAG SG_ 916 WBA_eing_Gang_02 1600;
BA_REL_ "GenSigTimeoutTime" BU_SG_REL_ Kombi_PAG SG_ 916 WBA_GE_Texte 1600;
BA_REL_ "GenSigTimeoutTime" BU_SG_REL_ Kombi_PAG SG_ 916 WBA_Segeln_aktiv 1600;
BA_REL_ "GenSigTimeoutTime" BU_SG_REL_ Kombi_PAG SG_ 916 WBA_GE_Zusatzwarnungen 1600;
BA_REL_ "GenSigTimeoutTime" BU_SG_REL_ Kombi_PAG SG_ 916 GE_Sollgang 1600;
BA_REL_ "GenSigTimeoutTime" BU_SG_REL_ Kombi_PAG SG_ 916 GE_Tipschaltempf_verfuegbar 1600;
BA_REL_ "GenSigTimeoutTime" BU_SG_REL_ Kombi_PAG SG_ 916 WBA_GE_Texte_02 1600;
BA_REL_ "GenSigTimeoutTime" BU_SG_REL_ Kombi_PAG SG_ 916 WBA_Blinken 1600;
BA_REL_ "GenSigTimeoutTime" BU_SG_REL_ Kombi_PAG SG_ 2527679839 WCU_StTankWa 5000;
BA_REL_ "GenSigTimeoutTime" BU_SG_REL_ Kombi_PAG SG_ 2527679839 WCU_VolWaRefill 5000;
BA_REL_ "GenSigTimeoutTime" BU_SG_REL_ Kombi_PAG SG_ 2527679839 WCU_VolWaRem 5000;
BA_REL_ "GenSigTimeoutTime" BU_SG_REL_ Kombi_PAG SG_ 2527679839 WCU_PrctVolWaRem 5000;
BA_REL_ "GenSigTimeoutTime" BU_SG_REL_ Kombi_PAG SG_ 1361 WFS_Schluessel_Soll 2000;
BA_REL_ "GenSigTimeoutTime" BU_SG_REL_ Kombi_PAG SG_ 1361 WFS_Schluessel_Ist 2000;
BA_REL_ "GenSigTimeoutTime" BU_SG_REL_ Kombi_PAG SG_ 1361 WFS_Safe 2000;
BA_REL_ "GenSigTimeoutTime" BU_SG_REL_ Kombi_PAG SG_ 1361 WFS_LZ 2000;
BA_REL_ "GenSigTimeoutTime" BU_SG_REL_ Kombi_PAG SG_ 1361 WFS_Fahrerhinweise 2000;
BA_REL_ "GenSigTimeoutTime" BU_SG_REL_ Kombi_PAG SG_ 1702 Wischer_vorne_defekt 5000;
BA_REL_ "GenSigTimeoutTime" BU_SG_REL_ Kombi_PAG SG_ 1702 Wischer_Anzeigetext 5000;
BA_REL_ "GenSigTimeoutTime" BU_SG_REL_ Kombi_PAG SG_ 2527679496 WIV_Verschleissindex_02 3200;
BA_REL_ "GenSigTimeoutTime" BU_SG_REL_ Kombi_PAG SG_ 2527679496 WIV_Verschleissindex_Ueberlauf 3200;
BA_REL_ "GenSigTimeoutTime" BU_SG_REL_ Kombi_PAG SG_ 2527679496 WIV_Russindex_02 3200;
BA_REL_ "GenSigTimeoutTime" BU_SG_REL_ Kombi_PAG SG_ 2527679496 WIV_Russindex_Ueberlauf 3200;
BA_REL_ "GenSigTimeoutTime" BU_SG_REL_ Kombi_PAG SG_ 2527679496 WIV_t_min 3200;
BA_REL_ "GenSigTimeoutTime" BU_SG_REL_ Kombi_PAG SG_ 2527679496 WIV_t_max 3200;
BA_REL_ "GenSigTimeoutTime" BU_SG_REL_ Kombi_PAG SG_ 2527679496 WIV_W_min 3200;
BA_REL_ "GenSigTimeoutTime" BU_SG_REL_ Kombi_PAG SG_ 2527679496 WIV_W_max 3200;
BA_REL_ "GenSigTimeoutTime" BU_SG_REL_ Kombi_PAG SG_ 2527679655 MMI_StartupAnimation 5000;
BA_REL_ "GenSigTimeoutTime" BU_SG_REL_ Kombi_PAG SG_ 1411 ZV_verriegelt_extern_ist 2000;
BA_REL_ "GenSigTimeoutTime" BU_SG_REL_ Kombi_PAG SG_ 1411 ZV_FT_offen 2000;
BA_REL_ "GenSigTimeoutTime" BU_SG_REL_ Kombi_PAG SG_ 1411 ZV_BT_offen 2000;
BA_REL_ "GenSigTimeoutTime" BU_SG_REL_ Kombi_PAG SG_ 1411 ZV_HFS_offen 2000;
BA_REL_ "GenSigTimeoutTime" BU_SG_REL_ Kombi_PAG SG_ 1411 ZV_HBFS_offen 2000;
BA_REL_ "GenSigTimeoutTime" BU_SG_REL_ Kombi_PAG SG_ 1411 ZV_HD_offen 2000;
BA_REL_ "GenSigTimeoutTime" BU_SG_REL_ Kombi_PAG SG_ 1411 ZV_SafeFunktion_aktiv 2000;
BA_REL_ "GenSigTimeoutTime" BU_SG_REL_ Kombi_PAG SG_ 1411 ZV_Tankklappe_offen 2000;
BA_REL_ "GenSigTimeoutTime" BU_SG_REL_ Waehlhebel_SB SG_ 2463978613 zFAS_Pilottaster_LED_Farbe_Anf 3200;
BA_REL_ "GenSigTimeoutTime" BU_SG_REL_ Waehlhebel_SB SG_ 2463978613 zFAS_Pilottaster_LED_Modus_Anf 3200;
VAL_ 974 HFS_Tuer_geoeffnet 0 "geschlossen" 1 "offen" ;
VAL_ 974 HFS_verriegelt 0 "nicht_verriegelt" 1 "verriegelt" ;
VAL_ 974 HFS_gesafet 0 "nicht_gesafet" 1 "gesafet" ;
VAL_ 974 HFS_Heckrollotaster_betaetigt 0 "keine_Verfahranweisung_in_Richtung_Hoch" 1 "In_Richtung_Hoch_Verfahren" ;
VAL_ 974 HFS_Tuerschloss_defekt 0 "Tuerschloss_funktionsfaehig" 1 "Tuerschloss_defekt" ;
VAL_ 974 HFS_Unlock_Taster 0 "nicht_betaetigt" 1 "betaetigt" ;
VAL_ 974 HFS_Lock_Taster 0 "nicht_betaetigt" 1 "betaetigt" ;
VAL_ 974 HFS_Sperrklinke 0 "Schloss_in_Vorraste_und_Hauptraste" 1 "Tuer_auf_oder_Tuer_Position_zwischen_Vor_und_Hauptraste" ;
VAL_ 974 HFS_TAG_betaetigt 0 "nicht_betaetigt" 1 "betaetigt" ;
VAL_ 974 HFS_TIG_betaetigt 0 "nicht_betaetigt" 1 "betaetigt" ;
VAL_ 974 HFS_FH_S_HBFS_AutoHoch 0 "keine_Bedienung" 1 "Automatiklauf_Angefordert" ;
VAL_ 974 HFS_FH_S_HBFS_AutoTief 0 "keine_Bedienung" 1 "Automatiklauf_Angefordert" ;
VAL_ 974 HFS_FH_S_HBFS_ManHoch 0 "keine_Bedienung" 1 "Manueller_Lauf_Angefordert" ;
VAL_ 974 HFS_FH_S_HBFS_ManTief 0 "keine_Bedienung" 1 "Manueller_Lauf_Angefordert" ;
VAL_ 974 HFS_Tuer_Status 0 "Init" 1 "Tuer_geschlossen" 2 "Tuer_offen" 3 "Fehler" ;
VAL_ 974 HFS_SAD_Schalter 0 "nicht_betaetigt" 5 "AUF_manuell" 6 "AUF_automatik" 7 "ZU_manuell" 8 "ZU_automatik" 13 "nicht_verfuegbar" 14 "Init" 15 "Fehler" ;
VAL_ 974 HFS_FH_S_ManHoch 0 "nicht_betaetigt" 1 "betaetigt" ;
VAL_ 974 HFS_FH_S_AutoHoch 0 "nicht_betaetigt" 1 "betaetigt" ;
VAL_ 974 HFS_FH_S_ManTief 0 "nicht_betaetigt" 1 "betaetigt" ;
VAL_ 974 HFS_FH_S_AutoTief 0 "nicht_betaetigt" 1 "betaetigt" ;
VAL_ 974 HFS_FH_Bew_hoch 0 "inaktiv" 1 "aktiv" ;
VAL_ 974 HFS_FH_Bew_tief 0 "inaktiv" 1 "aktiv" ;
VAL_ 974 HFS_FH_Fang 0 "ausserhalb_Fangbereich" 1 "innerhalb_Fangbereich" ;
VAL_ 974 HFS_FH_Block 0 "inaktiv" 1 "aktiv" ;
VAL_ 974 HFS_FH_Thermo 0 "inaktiv" 1 "aktiv" ;
VAL_ 974 HFS_UEKB_aktiviert 0 "inaktiv" 1 "aktiv" ;
VAL_ 974 HFS_Tueroeffnen_Warnung 0 "Tuerwarnung_nicht_aktiv" 1 "Tuerwarnung_aktiv" ;
VAL_ 974 HFS_FH_normiert 0 "inaktiv" 1 "aktiv" ;
VAL_ 974 ASW_Warnung_aktiv_HFS 0 "nicht_angefordert" 1 "angefordert" ;
VAL_ 974 HFS_Zuziehhilfe_aktiv 0 "Init" 1 "Zuziehhilfe_aktiv" ;
VAL_ 974 HFS_Seitenrollo_hoch 0 "Init" 1 "Seitenrollo_in_Bewegung_hoch" ;
VAL_ 974 HFS_Seitenrollo_tief 0 "Init" 1 "Seitenrollo_in_Bewegung_tief" ;
VAL_ 974 HFS_Status_KiSi 0 "inaktiv" 1 "aktiv" ;
VAL_ 974 SSR_HFS_Pos_Unten 0 "SSR_Oben" 1 "SSR_Unten" ;
VAL_ 974 HFS_Oben_Block_erw 0 "Fensterheber_nicht_in_Blockerwar" 1 "Fensterheber_in_Blockerwartung_o" ;
VAL_ 974 HFS_Unten_Block_erw 0 "Fensterheber_nicht_in_Blockerwar" 1 "Fensterheber_in_Blockerwartung_u" ;
VAL_ 974 MTHFS_M_Taste 0 "nicht_betaetigt" 1 "betaetigt" ;
VAL_ 974 MTHFS_Pos1 0 "nicht_betaetigt" 1 "betaetigt" ;
VAL_ 974 MTHFS_Pos2 0 "nicht_betaetigt" 1 "betaetigt" ;
VAL_ 974 MTHFS_Pos3 0 "nicht_betaetigt" 1 "betaetigt" ;
VAL_ 974 HFS_MRollo_Schalter 0 "nicht_betaetigt" 1 "ZU_manuell" 2 "ZU_automatik" 3 "AUF_manuell" 4 "AUF_automatik" 5 "nicht_verfuegbar" 6 "Init" 7 "Fehler" ;
VAL_ 974 HFS_Lock_Taster_inv 0 "Lock Taster betätgit" 1 "Lock Taster nicht betätigt" ;
VAL_ 974 HFS_Status_eTAG 0 "Init" 1 "Griff_ausgefahren" 2 "Griff_eingefahren" 3 "Fehler" ;
VAL_ 974 HFS_Tuer_Status_QBit 0 "Status_Tuerkontakt_sicher" 1 "Status_Tuerkontakt_unsicher" ;
VAL_ 974 HFS_TCR_Mode_aktiv 0 "TCR_Mode_deaktiv" 1 "TCR_Mode_aktiv" ;
VAL_ 288 TSK_Status 0 "Hauptschalter_aus" 1 "Init" 2 "passiv" 3 "aktiv" 4 "Uebertreten" 5 "brake_only_Mode" 6 "reversibel_aus" 7 "irreversibel_aus" ;
VAL_ 288 TSK_v_Begrenzung_aktiv 0 "inaktiv" 1 "aktiv" ;
VAL_ 288 TSK_Standby_Anf_ESP 0 "keine_Standby_Anforderung" 1 "Standby_Anforderung" ;
VAL_ 288 TSK_Freig_WU 0 "TSK_Uebersetzungswunsch_nicht_freigegeben" 1 "TSK_Uebersetzungswunsch_freigegeben" ;
VAL_ 288 TSK_Freig_Verzoeg_Anf 0 "Verzoegerungsanforderung_nicht_freigegeben" 1 "Verzoegerungsanforderung_freigegeben" ;
VAL_ 288 TSK_Limiter_ausgewaehlt 0 "kein_Limiter_ausgewaehlt" 1 "Limiter_ausgewaehlt" ;
VAL_ 288 TSK_Wunsch_Uebersetz 0 "Init" ;
VAL_ 288 TSK_Hauptschalter_GRA_ACC 0 "Init" 1 "Aus" 2 "Ein" 3 "Fehler" ;
VAL_ 288 TSK_SRBM_Anf_ASIL 0 "keine_SRBM_Anforderung" 1 "SRBM_Anforderung_in_ASIL_QM" 2 "SRBM_Anforderung_in_ASIL_A" 3 "SRBM_Anforderung_in_ASIL_B" 4 "SRBM_Anforderung_in_ASIL_C" ;
VAL_ 288 TSK_ax_Getriebe_02 511 "Neutralwert" ;
VAL_ 288 TSK_Zwangszusch_ESP 0 "keine_ESP_ASR_Beeinflussung" 1 "ESP_ASR_Beeinflussung" ;
VAL_ 798 TSK_Wunschgeschw 1022 "keine_Anzeige" 1023 "kein_Wert_im_Speicher" ;
VAL_ 798 TSK_praediktiver_Hinweis 0 "keine_Anzeige" 1 "Vorschlag_zur_Bestaetigung" 2 "Hinweis_neuer_Setzwert" 3 "Regelung_im_Uebergang" 4 "Tempolimit_voraus" 5 "Tempolimit_erkannt" ;
VAL_ 798 TSK_naechstes_Event 0 "Init" 1 "Tempolimit_5" 2 "Tempolimit_10" 3 "Tempolimit_15" 4 "Tempolimit_20" 5 "Tempolimit_25" 6 "Tempolimit_30" 7 "Tempolimit_35" 8 "Tempolimit_40" 9 "Tempolimit_45" 10 "Tempolimit_50" 11 "Tempolimit_55" 12 "Tempolimit_60" 13 "Tempolimit_65" 14 "Tempolimit_70" 15 "Tempolimit_75" 16 "Tempolimit_80" 17 "Tempolimit_90" 18 "Tempolimit_100" 19 "Tempolimit_110" 20 "Tempolimit_120" 21 "Tempolimit_130" 22 "Tempolimit_140" 23 "Tempolimit_150" 24 "Tempolimit_160" 25 "Tempolimit_unbegrenzt" 26 "Linkskurve" 27 "Rechtskurve" 28 "Kuppe" 29 "Steigung" 30 "Gefaelle" 31 "Kreuzung" 32 "Ampel" 33 "Bahnuebergang" 34 "Ortsanfang" 35 "Kreisverkehr" 36 "naechstes_Limit_ausserh_Verfueg" ;
VAL_ 798 TSK_Fahrzeugstatus_praed_Fkt 0 "init" 1 "Praed_Fkt_verfuegbar" 2 "Praed_Fkt_eingeschraenkt_verfueg" 3 "Praed_Fkt_nicht_verfuegbar" 4 "Praed_Fkt_Land_nicht_verfuegbar" 5 "Praed_Fkt_Auffahrt" 6 "Praed_Fkt_Abfahrt" 7 "Praed_Fkt_Regelbereich_verlassen" ;
VAL_ 798 TSK_praediktiver_Automode 0 "Automode_inaktiv" 1 "Automode_aktiv" ;
VAL_ 798 TSK_Texte 0 "kein_Text" 1 "GRA_Modus_ausgewaehlt" 2 "ACC_Modus_ausgewaehlt" 3 "Lim_Modus_ausgewaehlt" 4 "Lim_nicht_verfuegbar_ESC_passiv" 5 "GRA_nicht_verfuegbar_ESC_passiv" 6 "Lim_nicht_verfuegbar_Charisma" 7 "GRA_nicht_verfuegbar_Charisma" 8 "Lim_nicht_verfuegbar_HDC" 9 "GRA_nicht_verfuegbar_HDC" 10 "P_GRA_Modus_ausgewaehlt" 11 "P_LIM_Modus_ausgewaehlt" 12 "Bremse_ueberhitzt" 13 "kein_Laengsregler" 14 "kein_Abstandsregler" 15 "keine_Abstandsregelung" 16 "Bitte_Hauptschalter_einschalten" ;
VAL_ 798 TSK_Akustik 0 "keine_Akustik" 1 "einzelner_Warnton" 2 "dauerhafter_Warnton" ;
VAL_ 798 TSK_Texte_Primaeranz 0 "keine_Anzeige" 1 "GRA_Symbol_passiv_xxx_kmh_mph" 2 "GRA_Symbol_aktiv_xxx_kmh_mph" 3 "Bremse_ueberhitzt" 4 "Limiter_Modus_aktiviert" 5 "GRA_Modus_aktiviert" 6 "ACC_Modus_aktiviert" 7 "Opt_Geschwindigkeitswarnung" 8 "Opt_und_akustische_GeschwWarnung" 9 "Opt_GeschwWarnung_dauerhaft_mit_einmal_Akustik" 10 "Limiter_passiv_mit_Akustik" 11 "Limiter_Fehler_mit_Akustik" 12 "Limiter_Symbol_passiv_xxx_kmh_mph" 13 "Limiter_Symbol_aktiv_xxx_kmh_mph" 14 "Popup_Geschw_zu_hoch__Resume_unzulaessig" ;
VAL_ 798 TSK_Limiter_Fahrerinfo 0 "keine_Info" 1 "Limit_erreicht" 2 "Ueberschritten" 3 "Vom_Fahrer_Ueberstimmt" ;
VAL_ 798 TSK_Limiter_Anzeige 0 "Display_Anzeige_GRA_ACC" 1 "Display_Anzeige_Limiter" ;
VAL_ 798 TSK_Fahrzeugstatus_GRA 0 "GRA_verfuegbar" 1 "GRA_nicht_verfuegbar" ;
VAL_ 798 TSK_Fahrzeugstatus_Limiter 0 "Limiter_verfuegbar" 1 "Limiter_nicht_verfuegbar" ;
VAL_ 798 MO_Motorlaufwarnung 0 "keine_Anzeige" 1 "Anforderung_Motorlaufwarnung" ;
VAL_ 798 MO_Verlassenswarnung 0 "keine_Anzeige" 1 "Anforderung_Verlassenswarnung" ;
VAL_ 798 TSK_naechstes_Event_Einheit 0 "kmh" 1 "mph" ;
VAL_ 798 TSK_Status_Anzeige 0 "Hauptschalter_aus" 1 "Init" 2 "passiv" 3 "aktiv" 4 "Uebertreten" 5 "Limitiierung_aktiv" 6 "reversibel_aus" 7 "irreversibel_aus" ;
VAL_ 563 TSK_praed_Wunschgeschw 1022 "keine_Anzeige" 1023 "kein_praed_Setzwert_verfuegbar" ;
VAL_ 1718 UH_Typ 0 "undefiniert" 1 "Quarzuhr" 2 "DCF" 3 "GPS" ;
VAL_ 1718 UH_DLS 0 "Winterzeit" 1 "Sommerzeit" ;
VAL_ 1718 UH_Monat 0 "Init" 14 "Relatives_Datum" 15 "Fehler" ;
VAL_ 1718 UH_Tag 0 "Init" ;
VAL_ 618 USS_MKE_Risiko 0 "gering" 1 "mittel" 2 "hoch" 3 "unbekannt" ;
VAL_ 618 USS_MKE_Index_Anstieg 0 "stark_abfallend" 1 "leicht_abfallend" 2 "gleichbleibend" 3 "leicht_ansteigend" 4 "stark_ansteigend" 5 "unbekannt" ;
VAL_ 618 USS_MKE_Index_Quelle_LWS_Basis 0 "nicht_verwendet" 1 "verwendet" ;
VAL_ 618 USS_MKE_Index_Quelle_LWS_Plus 0 "nicht_verwendet" 1 "verwendet" ;
VAL_ 618 USS_MKE_Index_Quelle_MFK 0 "nicht_verwendet" 1 "verwendet" ;
VAL_ 618 USS_MKE_Index_Quelle_FBK 0 "nicht_verwendet" 1 "verwendet" ;
VAL_ 618 USS_MKE_Index 126 "Init" 127 "Fehler" ;
VAL_ 618 USS_MKE_Index_Quelle_Biometrisch 0 "nicht_verwendet" 1 "verwendet" ;
VAL_ 618 USS_Fahrzeit_seit_Pause 1022 "keine_Fahrzeit_vorhanden" 1023 "Fehler" ;
VAL_ 618 USS_Fahrer_Texte 0 "keine_Anzeige" 1 "MKE_Warnstufe_1" 2 "MKE_Warnstufe_2" ;
VAL_ 2463978633 VAS_L_Bedien_Master 0 "Bedien_Slave" 1 "Bedien_Master" ;
VAL_ 2463978633 VAS_L_Parkview_aktiv 0 "Parkview_nicht_aktiv" 1 "Parkview_aktiv" ;
VAL_ 2463978633 VAS_L_Autobahnview_aktiv 0 "Autobahnview_nicht_aktiv" 1 "Autobahnview_aktiv" ;
VAL_ 2463978633 VAS_L_Turnview_aktiv 0 "Turnview_nicht_aktiv" 1 "Turnview_aktiv" ;
VAL_ 2463978633 VAS_L_HMI_Aktiv 0 "HMI_Inaktiv" 1 "HMI_Aktiv" ;
VAL_ 2463978633 VAS_L_SWA_HMI_Diagnose 0 "kein_Fehler_erkannt" 1 "Fehler_erkannt" ;
VAL_ 2463978633 VAS_L_Texte 0 "keine_Stoerung" 1 "Kameras_verschmutzt" 2 "Systemstoerung_links" 3 "Systemstoerung_rechts" 4 "allgemeine_Systemstoerung" 7 "Init" ;
VAL_ 2463978633 VAS_L_Spiegelauswahl 0 "Spiegel_links" 1 "Spiegel_rechts" ;
VAL_ 2463978633 VAS_L_Verstell_Pos_X 511 "Fehler" ;
VAL_ 2463978633 VAS_L_Heizung_Aktiv 127 "Fehler" ;
VAL_ 2463978633 VAS_L_Verstell_Pos_Y 511 "Fehler" ;
VAL_ 2463978633 VAS_L_Zoom_Level 127 "Fehler" ;
VAL_ 995 VS_VD_zu_ver 1 "Zustand des Verdecks verriegelt und geschlossen" ;
VAL_ 995 VS_VD_entriegelt 0 "Init" 1 "Zustand_des_Verdeck_entriegelt" ;
VAL_ 995 VS_VD_offen_ver 0 "Init" 1 "Verdeck_verriegelt_und_offen" ;
VAL_ 995 VS_VD_Zwischenposition 0 "Init" 1 "Verdeck_in_Zwischenposition" ;
VAL_ 995 VS_VD_Bew_auf 1 "Verdeck in Bewegung auf" ;
VAL_ 995 VS_VD_Bew_zu 1 "Verdeck in Bewegung zu" ;
VAL_ 995 VS_Verdeck_Anf 0 "init_nicht_aktiv" 1 "aktiv" ;
VAL_ 995 VS_Hardtop 0 "Init" 1 "Hardtop_montiert" ;
VAL_ 995 VS_VD_Fehler 0 "Init" 1 "Fehlerzustand Verdeck" ;
VAL_ 995 VS_Lampe_Blk 0 "Kontrollleuchte_inaktiv" 1 "Kontrollleuchte_aktiv" ;
VAL_ 995 VS_HD_sperren 0 "HD Entriegelung freigegeben" 1 "HD Entriegelung gesperrt" ;
VAL_ 995 VS_HHS_enable 0 "Init" 1 "Freigabe HHS" ;
VAL_ 995 VD_SpannungsAnf 0 "keine_Anforderung" 1 "Anforderung_Stufe1" 2 "Anforderung_Stufe2" 3 "Anforderung_Stufe3" ;
VAL_ 995 VS_VDKD_auf 0 "VDKD_nicht_vollst_auf" 1 "VDKD_vollstaendig_auf" ;
VAL_ 995 VS_FS_AutoHoch 0 "Keine_Verfahranforderung" 1 "Automatischer_Hochlauf" ;
VAL_ 995 VS_FS_AutoTief 0 "Keine_Verfahranforderung" 1 "Automatischer_Tieflauf" ;
VAL_ 995 VS_FS_ManHoch 0 "Keine_Verfahranforderung" 1 "Manueller_Hochlauf" ;
VAL_ 995 VS_FS_ManTief 0 "Keine_Verfahranforderung" 1 "Manueller_Tieflauf" ;
VAL_ 995 VS_BFS_AutoHoch 0 "Keine_Verfahranforderung" 1 "Automatischer_Hochlauf" ;
VAL_ 995 VS_BFS_AutoTief 0 "Keine_Verfahranforderung" 1 "Automatischer_Tieflauf" ;
VAL_ 995 VS_BFS_ManHoch 0 "Keine_Verfahranforderung" 1 "Manueller_Hochlauf" ;
VAL_ 995 VS_BFS_ManTief 0 "Keine_Verfahranforderung" 1 "Manueller_Tieflauf" ;
VAL_ 995 VS_HFS_AutoHoch 0 "Keine_Verfahranforderung" 1 "Automatischer_Hochlauf" ;
VAL_ 995 VS_HFS_AutoTief 0 "Keine_Verfahranforderung" 1 "Automatischer_Tieflauf" ;
VAL_ 995 VS_HFS_ManHoch 0 "Keine_Verfahranforderung" 1 "Manueller_Hochlauf" ;
VAL_ 995 VS_HFS_ManTief 0 "Keine_Verfahranforderung" 1 "Manueller_Tieflauf" ;
VAL_ 995 VS_HBFS_AutoHoch 0 "Keine_Verfahranforderung" 1 "Automatischer_Hochlauf" ;
VAL_ 995 VS_HBFS_AutoTief 0 "Keine_Verfahranforderung" 1 "Automatischer_Tieflauf" ;
VAL_ 995 VS_HBFS_ManHoch 0 "Keine_Verfahranforderung" 1 "Manueller_Hochlauf" ;
VAL_ 995 VS_HBFS_ManTief 0 "Keine_Verfahranforderung" 1 "Manueller_Tieflauf" ;
VAL_ 995 VS_FH_FT_Langhub 0 "Init" ;
VAL_ 995 VS_Windschott_nicht_abgelegt 0 "inaktiv" 1 "aktiv" ;
VAL_ 995 VS_FH_BT_Langhub 0 "Init" ;
VAL_ 995 VS_FH_HFS_Langhub 0 "Init" ;
VAL_ 995 VS_Heckschloss_auf 0 "kein_Oeffnen" 1 "Heckschloss_oeffnen" ;
VAL_ 995 VS_FH_HBFS_Langhub 0 "Init" ;
VAL_ 995 VSG_Meldungen 0 "keine_Meldung" ;
VAL_ 995 VS_StartStopp_Info 0 "Stoppfreigabe" 1 "Stoppverbot" 2 "Startanforderung" 3 "Fehler" ;
VAL_ 385 VZE_Anzeigemodus 0 "EU_RDW" 1 "USA" 2 "Canada" 3 "China" ;
VAL_ 385 VZE_Hinweistext 0 "kein_Hinweistext" ;
VAL_ 385 VZE_Akustik_Limitwechsel 0 "keine_akustische_Signalisierung" 1 "akustische_Signalisierung_an" ;
VAL_ 385 VZE_Modus_OptischeWarnung 0 "konstant" 1 "blinkend" ;
VAL_ 385 VZE_Verkehrszeichen_Einheit 0 "kmh" 1 "mph" ;
VAL_ 385 VZE_Anzeigeunterdrueck_Zeichen_3 0 "anzeigerelevant" 1 "nicht_anzeigerelevant" ;
VAL_ 385 VZE_Anzeigeunterdrueck_Zeichen_2 0 "anzeigerelevant" 1 "nicht_anzeigerelevant" ;
VAL_ 385 VZE_Verkehrszeichen_1 0 "kein_Verkehrszeichen" ;
VAL_ 385 VZE_Verkehrszeichen_2 0 "kein_Verkehrszeichen" ;
VAL_ 385 VZE_Verkehrszeichen_3 0 "kein_Verkehrszeichen" ;
VAL_ 385 VZE_Warnung_Verkehrszeichen_1 0 "keine_Warnung_Initialwert_Fehlerwert" 1 "Warnung" ;
VAL_ 385 VZE_Warnung_Verkehrszeichen_2 0 "keine_Warnung_Initialwert_Fehlerwert" 1 "Warnung" ;
VAL_ 385 VZE_Warnung_Verkehrszeichen_3 0 "keine_Warnung_Initialwert_Fehlerwert" 1 "Warnung" ;
VAL_ 385 VZE_Zusatzschild_1 0 "keine_Zusatzschild_Initialwert_Fehlerwert" ;
VAL_ 385 VZE_Zusatzschild_2 0 "keine_Zusatzschild_Initialwert_Fehlerwert" ;
VAL_ 385 VZE_Zusatzschild_3 0 "keine_Zusatzschild_Initialwert_Fehlerwert" ;
VAL_ 385 VZE_Anzeigeunterdrueck_Zeichen_1 0 "anzeigerelevant" 1 "nicht_anzeigerelevant" ;
VAL_ 385 VZE_Zeichen_01_KameraWied 0 "inaktiv" 1 "aktiv" ;
VAL_ 385 VZE_Zeichen_02_KameraWied 0 "inaktiv" 1 "aktiv" ;
VAL_ 385 VZE_Zeichen_03_KameraWied 0 "inaktiv" 1 "aktiv" ;
VAL_ 385 VZE_Zeichen_01_Kamera 0 "nicht_erkannt" 1 "erkannt" ;
VAL_ 385 VZE_Zeichen_01_Karte 0 "inaktiv" 1 "aktiv" ;
VAL_ 385 VZE_Zeichen_01_Gesetz 0 "nicht_erkannt" 1 "erkannt" ;
VAL_ 385 VZE_Zeichen_02_Kamera 0 "nicht_erkannt" 1 "erkannt" ;
VAL_ 385 VZE_Zeichen_02_Karte 0 "inaktiv" 1 "aktiv" ;
VAL_ 385 VZE_Zeichen_02_Gesetz 0 "nicht_erkannt" 1 "erkannt" ;
VAL_ 385 VZE_Zeichen_03_Kamera 0 "nicht_erkannt" 1 "erkannt" ;
VAL_ 385 VZE_Zeichen_03_Karte 0 "inaktiv" 1 "aktiv" ;
VAL_ 385 VZE_Zeichen_03_Gesetz 0 "nicht_erkannt" 1 "erkannt" ;
VAL_ 385 VZE_Gong 0 "Gong_deaktiv" 1 "Gong_aktiv" ;
VAL_ 668 VZE_Akustik_Limitwechsel_Status 0 "keine_akustische_Signalisierung" 1 "akustische_Signalisierung_an" ;
VAL_ 668 VZE_SLWF_Status 0 "Init" 1 "aktiv" 2 "deaktiv" ;
VAL_ 668 VZE_Anzeigeunterdrueck_Zeichen_5 0 "anzeigerelevant" 1 "nicht_anzeigerelevant" ;
VAL_ 668 VZE_Zeichen_05_KameraWied 0 "inaktiv" 1 "aktiv" ;
VAL_ 668 VZE_Zeichen_05_Kamera 0 "nicht_erkannt" 1 "erkannt" ;
VAL_ 668 VZE_Verkehrszeichen_4 0 "kein_Verkehrszeichen" ;
VAL_ 668 VZE_Verkehrszeichen_5 0 "kein_Verkehrszeichen" ;
VAL_ 668 VZE_Anhaenger_Vmax 14 "Init" 15 "Fehler" ;
VAL_ 668 VZE_Zeichen_04_Gesetz 0 "nicht_erkannt" 1 "erkannt" ;
VAL_ 668 VZE_Zeichen_04_Kamera 0 "nicht_erkannt" 1 "erkannt" ;
VAL_ 668 VZE_Zeichen_04_KameraWied 0 "inaktiv" 1 "aktiv" ;
VAL_ 668 VZE_Zeichen_04_Karte 0 "inaktiv" 1 "aktiv" ;
VAL_ 668 VZE_Warnung_Verkehrszeichen_4 0 "keine_Warnung_Initialwert_Fehlerwert" 1 "Warnung" ;
VAL_ 668 VZE_Warnung_Verkehrszeichen_5 0 "keine_Warnung_Initialwert_Fehlerwert" 1 "Warnung" ;
VAL_ 668 VZE_Zeichen_05_Gesetz 0 "nicht_erkannt" 1 "erkannt" ;
VAL_ 668 VZE_Zusatzschild_4 0 "keine_Zusatzschild_Initialwert_Fehlerwert" ;
VAL_ 668 VZE_Zusatzschild_5 0 "keine_Zusatzschild_Initialwert_Fehlerwert" ;
VAL_ 668 VZE_Baustelle 0 "Keine_Baustelle" 1 "Baustelle_erkannt" ;
VAL_ 668 VZE_Zeichen_05_Karte 0 "inaktiv" 1 "aktiv" ;
VAL_ 668 VZE_Zeichen_05_Entfernung 0 "Init" ;
VAL_ 668 VZE_Zeichen_05_Entfernung_StdA 0 "Init" ;
VAL_ 668 VZE_Anzeigeunterdrueck_Zeichen_4 0 "anzeigerelevant" 1 "nicht_anzeigerelevant" ;
VAL_ 2463978672 VZE_FoD_Status 0 "Init" 1 "Funktion_inaktiv" 2 "Funktion_aktiv" ;
VAL_ 2463978672 VZE_Anzeige_ZS_1 0 "Init" ;
VAL_ 2463978672 VZE_Anzeige_ZS_2 0 "Init" ;
VAL_ 2463978672 VZE_Anzeige_ZS_3 0 "Init" ;
VAL_ 2463978672 VZE_Hinweistext_03 0 "kein_Hinweistext" ;
VAL_ 2463978672 VZE_Land 0 "Init" ;
VAL_ 2463978672 VZE_Warnung_VZ_1 0 "keine_Warnung" 1 "Warnung" ;
VAL_ 2463978672 VZE_Warnung_VZ_2 0 "keine_Warnung" 1 "Warnung" ;
VAL_ 2463978672 VZE_Warnung_VZ_3 0 "keine_Warnung" 1 "Warnung" ;
VAL_ 2463978672 VZE_Anzeige_VZ_1 0 "kein_Verkehrszeichen" ;
VAL_ 2463978672 VZE_Anzeige_VZ_2 0 "kein_Verkehrszeichen" ;
VAL_ 2463978672 VZE_Anzeige_VZ_3 0 "kein_Verkehrszeichen" ;
VAL_ 181 WH_gespeicherte_Fahrstufe 0 "keine_Speicherung" 1 "P" 2 "R" 3 "N" 4 "D" 5 "S" 6 "Tipp_Gasse" ;
VAL_ 181 WH_Initialisierung 0 "keine Initphase" 1 "Initphase" ;
VAL_ 181 WH_SensorPos_roh 0 "Init" 1 "Pos_1" 2 "Pos_2" 3 "Pos_3" 4 "Pos_4" 5 "Pos_5" 6 "Pos_6" 7 "Pos_7" 8 "Pos_8" 9 "Pos_9" 10 "Pos_10" 11 "Pos_11" 12 "Pos_12" 13 "Pos_13" 14 "Pos_14" 15 "Fehler" ;
VAL_ 181 WH_SensorPos_roh_inv 0 "Fehler" 1 "Pos_14" 2 "Pos_13" 3 "Pos_12" 4 "Pos_11" 5 "Pos_10" 6 "Pos_9" 7 "Pos_8" 8 "Pos_7" 9 "Pos_6" 10 "Pos_5" 11 "Pos_4" 12 "Pos_3" 13 "Pos_2" 14 "Pos_1" 15 "Init" ;
VAL_ 181 WH_Test_Aktiv 0 "kein Testergebnis" 1 "Testergebnis" ;
VAL_ 181 WH_Ist_Haltemagnet 0 "Init__nicht_verbaut" 1 "haelt_nicht" 2 "haelt" 3 "Fehler" ;
VAL_ 181 WH_Variante 0 "Init" 1 "Rastierter_Waehlhebel" 2 "Tasten" 4 "Monostabil_2x2" 5 "Sport_Tasten" 6 "Monostabil_2x2_reduziert" 7 "Monostabil_2x2_Walzensegment" 8 "Monostabil_2x2_Lenkstock_DK3" ;
VAL_ 181 WH_Entsperrtaste_02 0 "Init_nicht_verbaut" 1 "nicht_betaetigt" 2 "betaetigt" 3 "Fehler" ;
VAL_ 181 WH_P_Taste 0 "Init" 1 "nicht_betaetigt" 2 "betaetigt" 3 "Fehler" ;
VAL_ 181 WH_Ende_N_Haltephase 0 "nicht_aktiv" 1 "aktiv" ;
VAL_ 181 WH_Fahrstufe 0 "Init" 4 "nicht_betaetigt" 5 "D" 6 "N" 7 "R" 8 "P" 9 "N_ohne_Spotausleuchtung" 10 "Tipp_Plus" 11 "Tipp_Minus" 12 "S" 14 "Tipp_Gasse" 15 "Fehler" ;
VAL_ 181 WH_Status_Shiftlock 0 "Init" 2 "WH_freigegeben" 3 "WH_gesperrt" 6 "Shiftlock_nicht_verbaut" 7 "Fehler" ;
VAL_ 2589283476 WH_Warnung_02 0 "Keine_Anzeige" 1 "Waehlhebel_defekt_Weiterfahrt_moeglich" 2 "Waehlhebel_in_Automatgasse_zurueckstellen" 3 "P_Taste_defekt" 4 "Zeitueberschr_P_wird_eingelegt" 5 "Wegrollgefahr__P_nicht_moeglich" ;
VAL_ 2589283476 WH_Warnung_03 0 "keine_Anzeige" 1 "Fahrstufe_D_mit_rechtem_Paddle" 2 "Fahrstufe_D_ueber_MD_Button" ;
VAL_ 916 WBA_Fahrstufe_02 0 "Zwischenstellung_keine_Position" 1 "Position_P" 2 "Position_R" 3 "Position_N" 4 "Position_D" 5 "Position_S" 6 "Position_M_Tippfunktion" 7 "Kurzzeit_M" 8 "Position_E" 9 "Position_MS" 10 "Position_S_Plus" 11 "Position_MS_Plus" 12 "Position_Offroad" 13 "Position_B" ;
VAL_ 916 WBA_ZielFahrstufe 0 "keine_Gangempfehlung_kein_Gang_eingelegt" 1 "Pfeil_nach_S" 2 "Pfeil_nach_D" 3 "Pfeil_nach_M" 4 "Pfeil_nach_E" ;
VAL_ 916 WBA_GE_Warnung_02 0 "keine_Anzeige" 1 "Fehlereskalationsstufe_I" 2 "Fehlereskalationsstufe_II" 3 "Weiterfahrt_nur_eingeschraenkt_moeglich__Kein_R_Gang" 4 "Getriebefehler_Weiterfahrt_nur_in_D_moeglich__P_bei_Motor_aus" 5 "Wegrollgefahr__P_nicht_moeglich" 6 "Paddlenotbetrieb_Schema+Warnung" 7 "Paddlenotbetrieb_Schema" 8 "Geschwindigkeitsbegrenzung_Notlauf" 9 "Fehlereskalationsst_o_Einschr" 10 "Fehlereskalationsstufe_v_Limit" 11 "Parksperre_Infostufe" 12 "Parksperre_Warnstufe_I" 13 "Parksperre_Warnstufe_II" ;
VAL_ 916 WBA_eing_Gang_02 0 "keine_Ganganzeige" 1 "Gang_1" 2 "Gang_2" 3 "Gang_3" 4 "Gang_4" 5 "Gang_5" 6 "Gang_6" 7 "Gang_7" 8 "Gang_8" 9 "Gang_9" 10 "Funktion_Ganganzeigeunterdrueckung" 11 "Gang_10" ;
VAL_ 916 WBA_GE_Texte 0 "keine_Anzeige" 1 "zum_Einlegen_einer_Fahrstufe_Fussbremse_betaetigen__ShiftLock_Information" 2 "zum_Einlegen_von_R_N_D_Fussbremse_betaetigen_und_Motor_starten" 3 "Wegrollgefahr_bitte_P_einlegen" 4 "Achtung_Zeitueberschreitung_P_wird_eingelegt" 5 "Wiederanmeldeprozedur_Bremse_betaetigen" 6 "P_nur_im_Stillstand_moeglich" 7 "Rennstart_aktiv" ;
VAL_ 916 WBA_Segeln_aktiv 0 "inaktiv" 1 "aktiv" ;
VAL_ 916 WBA_Schaltschema 0 "kein_Schaltschema" 1 "xxxD(S)" 2 "xxxD_S" 3 "xxxS(D)" 4 "xxxS_D" 5 "xxxM(D)" 6 "xxxM_D" 7 "xxxM(S)" 8 "xxxM_S" 9 "xxxE(D)" 10 "xxxE_D" 11 "xxxE(S)" 12 "xxxE_S" 13 "xxxE(M)" 14 "xxxE_M" ;
VAL_ 916 WBA_GE_Zusatzwarnungen 0 "keine_Anzeige" 1 "Getriebeueberhitzung_Warnstufe_I" 2 "Getriebeueberhitzung_Warnstufe_II" 3 "Getriebefehler_Bitte_anhalten_und_P_einlegen" ;
VAL_ 916 GE_Sollgang 0 "keine_Empfehlung" 1 "Gang_1" 2 "Gang_2" 3 "Gang_3" 4 "Gang_4" 5 "Gang_5" 6 "Gang_6" 7 "Gang_7" 8 "Gang_8" 9 "Gang_9" 11 "Gang_10" ;
VAL_ 916 GE_Tipschaltempf_verfuegbar 0 "nicht_verfuegbar" 1 "verfuegbar" ;
VAL_ 916 WBA_GE_Texte_02 0 "Keine_Anzeige" 1 "Fahrtrichtungswechsel_nur_nach_Stillstandt" 2 "Ladestecker_gesteckt" 3 "zusaetzlicher_Service_erforderlich" 4 "eLaunch_Aktiv" 5 "eLaunch_nicht_moeglich" 6 "WH_S_nicht_moeglich_Offroad" 7 "WH_S_nicht_moeglich_RangeMode" ;
VAL_ 916 WBA_GE_Texte_03 0 "init" 1 "LC_not_available" 2 "LCperformance_not_possible" 3 "LCperformance_possible" 4 "LCperformance_armed" 5 "LCperformance_preparation" 6 "LCperformance_launch" 7 "LCperformance_aborted" 8 "LCsmoke_not_possible" 9 "LCsmoke_possible" 10 "LCsmoke_armed" 11 "LCsmoke_launch" 12 "LCsmoke_aborted" 15 "Fehler" ;
VAL_ 916 WBA_Blinken 0 "kein_WBA_Blinken" 1 "WBA_Blinken" ;
VAL_ 916 GE_Wiederstart_Anz_Std 0 "keine_Anzeige" 1 "Standard_Wiederstartgrund" ;
VAL_ 916 GE_Stoppverbot_Anz_01 0 "keine_Anzeige" 1 "Temperaturbedingung" ;
VAL_ 916 GE_Stoppverbot_Anz_02 0 "keine_Anzeige" 1 "Drucksensorausfall" ;
VAL_ 916 GE_Stoppverbot_Anz_03 0 "keine_Anzeige" 1 "Grundeinstellung" ;
VAL_ 916 GE_Stoppverbot_Anz_04 0 "keine_Anzeige" 1 "Demontagestellung" ;
VAL_ 916 GE_Stoppverbot_Anz_05 0 "keine_Anzeige" 1 "Eingeschraenkte_Fahrfunktion_Notlauf_Liegenbleiber" ;
VAL_ 916 GE_Stoppverbot_Anz_06 0 "keine_Anzeige" 1 "Stoppverbot_ueber_Applikation" ;
VAL_ 916 GE_Stoppverbot_Anz_07 0 "keine_Anzeige" 1 "Schaltung_aktiv" ;
VAL_ 916 GE_Stoppverbot_Anz_Std 0 "keine_Anzeige" 1 "Standard_Stoppvetogrund" ;
VAL_ 2527679839 WCU_StTankWa 0 "StTankWa_valid_liquid" 1 "StTankWa_valid_partly_frozen" 2 "StTankWa_valid_contaminated" 10 "StTankWa_contaminated" 11 "StTankWa_frozen" 12 "StTankWa_completely_used_up" 13 "StTankWa_wrong_medium" 14 "Init" 15 "Fehler" ;
VAL_ 2527679839 WCU_VolWaRefill 126 "Init" 127 "Fehler" ;
VAL_ 2527679839 WCU_VolWaRem 510 "Init" 511 "Fehler" ;
VAL_ 2527679839 WCU_VolWaRemRaw 510 "Init" 511 "Fehler" ;
VAL_ 2527679839 WCU_PrctVolWaRem 126 "Init" 127 "Fehler" ;
VAL_ 1361 WFS_Schluessel_Fahrberecht 0 "kein authorisierter Schluessel erkannt" 1 "aktive_Funkschluessel_Nr_01" 2 "aktive_Funkschluessel_Nr_02" 3 "aktive_Funkschluessel_Nr_03" 4 "aktive_Funkschluessel_Nr_04" 5 "aktive_Funkschluessel_Nr_05" 6 "aktive_Funkschluessel_Nr_06" 7 "aktive_Funkschluessel_Nr_07" 8 "aktive_Funkschluessel_Nr_08" 9 "ungueltig_09" 10 "ungueltig_10" 11 "ungueltig_11" 12 "ungueltig_12" 13 "ungueltig_13" 14 "ungueltig_14" 15 "digitaler_Schluessel_aktiv" ;
VAL_ 1361 WFS_ID_Geb_autorisiert 0 "Schluessel_nicht_authorisiert" 1 "Schluessel_authorisiert" ;
VAL_ 1361 WFS_ID_Geb_autorisiert_in_Kl15 0 "nicht_authorisiert_in_Kl15" 1 "authorisiert_in_Kl15" ;
VAL_ 1361 WFS_ID_Geb_steckt 0 "kein_Schluessel_im_Zuendschloss" 1 " Schluessel steckt im Zuendschloss" ;
VAL_ 1361 WFS_Safe 0 "Init" 1 "WFS nicht deaktiviert" ;
VAL_ 1361 WFS_LZ 0 "nicht def." 1 "LZ 1" 2 "LZ 2" 3 "LZ 3" ;
VAL_ 1361 WFS_ELV_authorisiert 0 "ELV_nicht_authorisiert" 1 "ELV_authorisiert" ;
VAL_ 1361 WFS_LF_Aktiv 0 "Funktempfang_nicht_aktiv" 1 "LF_Funkempfang_aktiv" ;
VAL_ 1361 WFS_Betrieb_Lesespule 0 "keine_Schluesselkomm_Lesespule" 1 "Schluesselkomm_Lesespule" ;
VAL_ 1361 WFS_Klemmenfreigabe 0 "keine_Freigabe" 1 "Freigabe" ;
VAL_ 1361 WFS_Fahrerhinweise 0 "Keine_Anzeigeanforderung" 1 "Schuessel_Auth_niO" 2 "Notlauf_aktiv" 3 "Schluessel_Kessy_nicht_gefunden" ;
VAL_ 1361 WFS_Parken_Status 0 "Limitierung_inaktiv" 1 "Limitierung_aktiv" 2 "Abbruch" ;
VAL_ 1702 Wischer_vorne_aktiv 0 "Init" 1 "Wischer_vorne_laeuft" ;
VAL_ 1702 Waschen_vorne_aktiv 0 "inaktiv" 1 "Waschen_aktiv" ;
VAL_ 1702 Wischer_vorne_Normal 1 "Wischer Front normal aktiv" ;
VAL_ 1702 Wischer_vorne_Schnell 1 "Wischer vorne schnell aktiv" ;
VAL_ 1702 Wischer_vorne_Parklage 0 "Wischer_Front_nicht_in_Parklage" 1 "Wischer_Front_in_Parklage__Initialzustand" ;
VAL_ 1702 Wischer_vorne_defekt 0 "Init" 1 "Wischer vorne defekt" ;
VAL_ 1702 Wischer_vorne_blockiert 1 "Wischer vorne blockiert" ;
VAL_ 1702 Wischer1_Wischgeschwindigkeit 0 "0 U/min" 62 "Init" 63 "Fehler" ;
VAL_ 1702 BCM1_SRA_aktiv 0 "nicht aktiv" 1 "aktiv" ;
VAL_ 1702 Heckwischer_Anforderung 0 "Aus" 1 "Ein" ;
VAL_ 1702 WWSs_01_upd 0 "nicht_aktuell" 1 "aktuell" ;
VAL_ 1702 Wischer_Anzeigetext 0 "keine_Anzeige" 1 "Hinweis_Service_Position" 2 "void" 3 "void" ;
VAL_ 2527679496 WIV_Verschleissindex_Ueberlauf 0 "kein_Ueberlauf" 1 "min_1_Zaehlerueberlauf" ;
VAL_ 2527679496 WIV_Russindex_Ueberlauf 0 "kein_Ueberlauf" 1 "min_1_Zaehlerueberlauf" ;
VAL_ 2527679655 MMI_StartupAnimation 0 "Init" 1 "MIBReadyForCommunication" 2 "MIBReadyForAnimation" 3 "RequestCancelAnimation" 4 "MIBAnimationStarted" 5 "MIBAnimationStopped" 6 "ReplyMeasureDelay" ;
VAL_ 2463978613 zFAS_Pilottaster_LED_Farbe_Anf 0 "keine_Anforderung" 1 "Farbe1" 2 "Farbe2" 3 "Farbe3" ;
VAL_ 2463978613 zFAS_Pilottaster_LED_Modus_Anf 0 "keine_Anforderung" 1 "Sonderfunktion_ein" ;
VAL_ 2463978613 zFAS_Blinker_li 0 "keine_Anforderung" 1 "Blinker_links_aktivieren" ;
VAL_ 2463978613 zFAS_Blinker_re 0 "keine_Anforderung" 1 "Blinker_rechts_aktivieren" ;
VAL_ 1411 BCM_FH_Freigabe 1 "Funktionsfreigabe Fensterheber" ;
VAL_ 1411 BCM_Komfortfkt_Freigabe 0 "Komfortfunktion gesperrt" 1 "globale Freigabe der Komfortfunktion erteilt" ;
VAL_ 1411 BCM_HSK_Freigabe 0 "erlauben" 1 "sperren" ;
VAL_ 1411 BCM_Verdeck_Freigabe 0 "Verdeckbetrieb nicht erlaubt" 1 "Verdeckbetrieb erlaubt" ;
VAL_ 1411 ZV_verriegelt_intern_ist 1 "Fahrzeug innen verriegelt; Istzustand" ;
VAL_ 1411 ZV_verriegelt_extern_ist 1 "Fahrzeug_aussen_verriegelt_Istzustand" ;
VAL_ 1411 ZV_verriegelt_intern_soll 1 "Fahrzeug verriegelt intern; Sollzusstand" ;
VAL_ 1411 ZV_verriegelt_extern_soll 1 "Fahrzeug verriegelt extern; Sollzusstand" ;
VAL_ 1411 ZV_gesafet_extern_ist 1 "Fahrzeug aussen gesafet; Istzustand" ;
VAL_ 1411 ZV_gesafet_extern_soll 1 "Fahrzeug_aussen_gesafet_Sollzustand" ;
VAL_ 1411 ZV_Einzeltuerentriegelung 1 "Fahrzeug an Einzeltuer entriegelt" ;
VAL_ 1411 ZV_Heckeinzelentriegelung 1 "Heckdeckeleinzelentriegelung" ;
VAL_ 1411 ZV_FT_offen 0 "FT_geschlossen" 1 "FT_geoeffnet" ;
VAL_ 1411 ZV_BT_offen 0 "BT_geschlossen" 1 "BT_geoeffnet" ;
VAL_ 1411 ZV_HFS_offen 0 "geschlossen" 1 "offen" ;
VAL_ 1411 ZV_HBFS_offen 0 "geschlossen" 1 "offen" ;
VAL_ 1411 ZV_HD_offen 1 "Heckdeckel_auf" ;
VAL_ 1411 ZV_HS_offen 0 "Heckscheibe_geschlossen" 1 "Heckscheibe auf" ;
VAL_ 1411 IRUE_aktiv 0 "unscharf" 1 "scharf" ;
VAL_ 1411 DWA_aktiv 0 "unscharf" 1 "scharf" ;
VAL_ 1411 HD_Hauptraste 0 "geschlossen" 1 "offen" ;
VAL_ 1411 HD_Vorraste 0 "geschlossen" 1 "offen" ;
VAL_ 1411 FFB_CarFinder 0 "nicht aktiv" 1 "aktiv" ;
VAL_ 1411 FFB_Komfortoeffnen 0 "kein_Komfortoeffnen_empfangen" 1 "Komfortoeffnen ueber Funk empfangen" ;
VAL_ 1411 FFB_Komfortschliessen 0 "kein_Komfortschliessen_empfangen" 1 "Komfortschliessen ueber Funk empfangen" ;
VAL_ 1411 ZV_Schluessel_Zugang 0 "kein_auth_Schluessel_erkannt" 1 "aktive_Funkschluessel_Nr_01" 2 "aktive_Funkschluessel_Nr_02" 3 "aktive_Funkschluessel_Nr_03" 4 "aktive_Funkschluessel_Nr_04" 5 "aktive_Funkschluessel_Nr_05" 6 "aktive_Funkschluessel_Nr_06" 7 "aktive_Funkschluessel_Nr_07" 8 "aktive_Funkschluessel_Nr_08" 9 "aktive_SmartDevice_Nr_09" 10 "ungueltig_10" 11 "ungueltig_11" 12 "ungueltig_12" 13 "ungueltig_13" 14 "ungueltig_14" 15 "ungueltig_15" ;
VAL_ 1411 ZV_SafeFunktion_aktiv 0 "inaktiv" 1 "aktiv" ;
VAL_ 1411 FBS_Warn_Schluessel_Batt 0 "i.O." 1 "defekt" ;
VAL_ 1411 ZV_Oeffnungsmodus 0 "globale_Oeffnung" 1 "ZV_mit_Einzeltuerentr" 2 "ZV_individuell_selektiv" 3 "ZV_seitenselektiv" ;
VAL_ 1411 HFS_verriegelt 0 "nicht_verriegelt" 1 "verriegelt" ;
VAL_ 1411 HFS_gesafet 0 "nicht_gesafet" 1 "gesafet" ;
VAL_ 1411 HBFS_verriegelt 0 "nicht_verriegelt" 1 "verriegelt" ;
VAL_ 1411 HBFS_gesafet 0 "nicht_gesafet" 1 "gesafet" ;
VAL_ 1411 ZV_ist_Zustand_verfuegbar 0 "nicht_verfuegbar" 1 "verfuegbar_alle_TSGs_am_Bus" ;
VAL_ 1411 IRUE_Taster_Fkts_LED 0 "LED_aus" 1 "LED_ein" ;
VAL_ 1411 ZV_Tankklappe_offen 0 "Tankklappe_geschlossen" 1 "Tankklappe_offen" ;
VAL_ 1411 ZV_Rollo_auf 0 "inaktiv" 1 "aktiv" ;
VAL_ 1411 ZV_Rollo_zu 0 "inaktiv" 1 "aktiv" ;
VAL_ 1411 ZV_SAD_auf 0 "inaktiv" 1 "aktiv" ;
VAL_ 1411 ZV_SAD_zu 0 "inaktiv" 1 "aktiv" ;
VAL_ 1411 BCM_Tankklappensteller_Fehler 0 "kein_Fehler" 1 "Fehler" ;
VAL_ 1411 ZV_verriegelt_soll 0 "Init" 1 "nicht_verriegelt" 2 "verriegelt" ;
